[part 4 of 4: package /ComponentTypes]
AUTOSAR XML (schema 00050)
package /ComponentTypes  (continued)
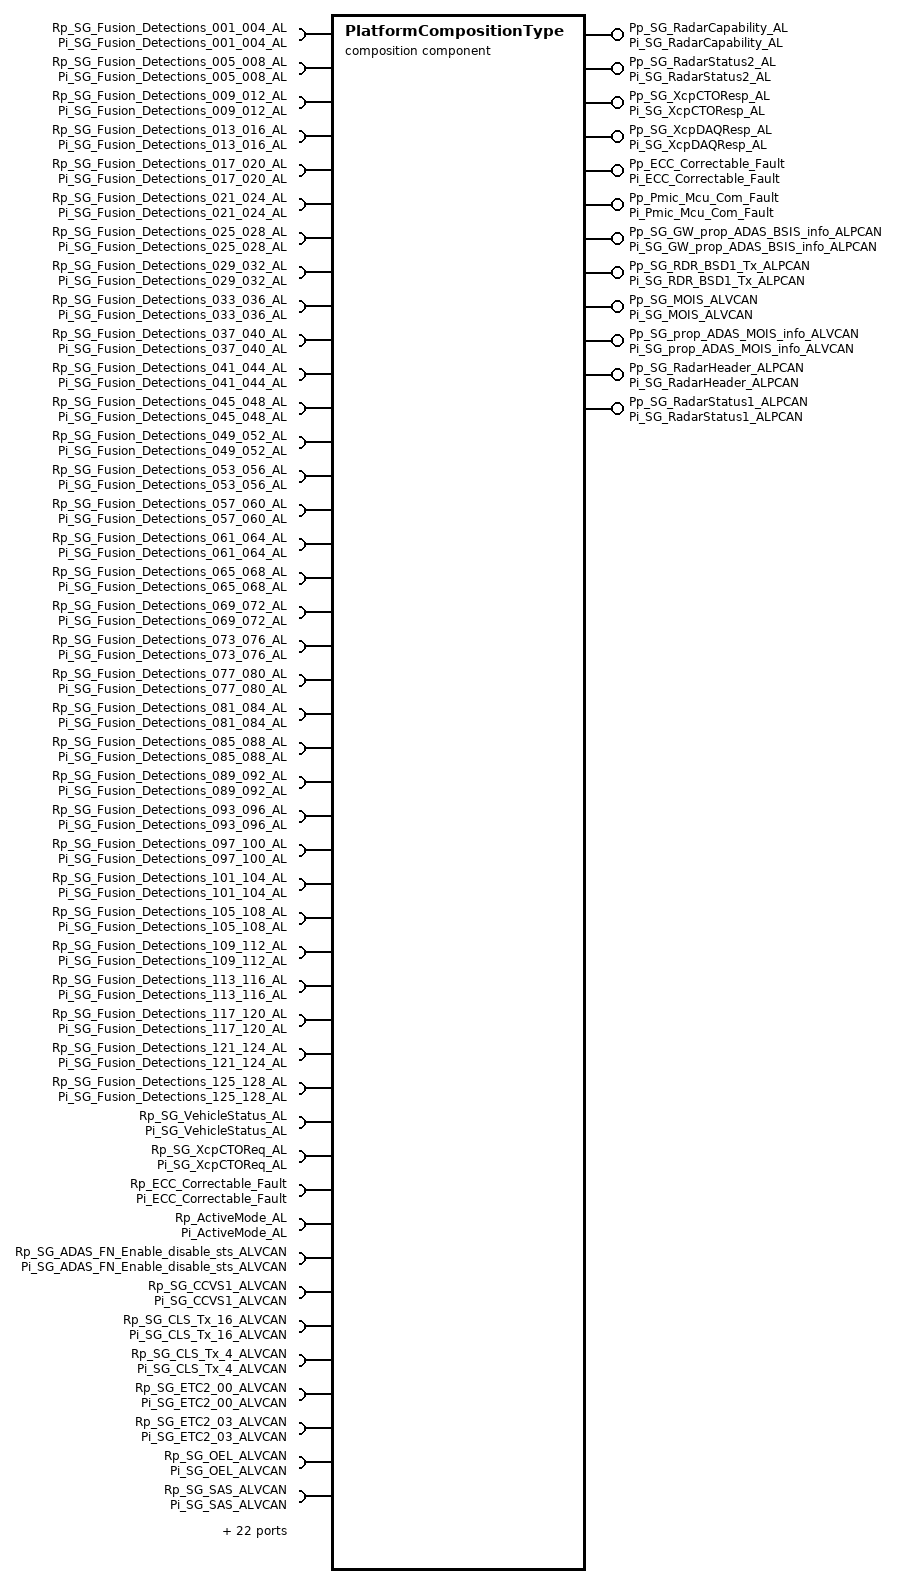
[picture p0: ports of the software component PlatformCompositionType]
  composition sw component type PlatformCompositionType  (continued)
    102 x provide port:  (continued)
      Pp_SG_Detections_397_400_AL: nonqueued-sender-com-spec{data-element=Vdp_SG_Detections_397_400_AL, init-value=fields=[DET_AZIMUTH_397:0, DET_AZIMUTH_398:0, DET_AZIMUTH_399:0, DET_AZIMUTH_400:0, DET_AZIMUTH_ERR_397:0, DET_AZIMUTH_ERR_398:0, DET_AZIMUTH_ERR_399:0, DET_AZIMUTH_ERR_400:0, DET_BELOW_RAIN_THOLD_397:0, DET_BELOW_RAIN_THOLD_398:0, DET_BELOW_RAIN_THOLD_399:0, DET_BELOW_RAIN_THOLD_400:0, DET_BI_STATIC_FLAG_397:0, DET_BI_STATIC_FLAG_398:0, DET_BI_STATIC_FLAG_399:0, DET_BI_STATIC_FLAG_400:0, DET_CONFD_AZIMUTH_397:0, DET_CONFD_AZIMUTH_398:0, DET_CONFD_AZIMUTH_399:0, DET_CONFD_AZIMUTH_400:0, DET_CONFD_ELEVATION_397:0, DET_CONFD_ELEVATION_398:0, DET_CONFD_ELEVATION_399:0, DET_CONFD_ELEVATION_400:0, DET_ELEVATION_397:0, DET_ELEVATION_398:0, DET_ELEVATION_399:0, DET_ELEVATION_400:0, DET_ELEVATION_ERR_397:0, DET_ELEVATION_ERR_398:0, DET_ELEVATION_ERR_399:0, DET_ELEVATION_ERR_400:0, DET_EXISTENCE_PROB_397:0, DET_EXISTENCE_PROB_398:0, DET_EXISTENCE_PROB_399:0, DET_EXISTENCE_PROB_400:0, DET_HVC_FLAG_397:0, DET_HVC_FLAG_398:0, DET_HVC_FLAG_399:0, DET_HVC_FLAG_400:0, DET_IDM_397:0, DET_IDM_398:0, DET_IDM_399:0, DET_IDM_400:0, DET_MH_CRC16_397_400:0, DET_MH_CYCLE_COUNTER_397_400:0, DET_MH_SCAN_INDEX_4LSB_397_400:0, DET_MTD_397:0, DET_MTD_398:0, DET_MTD_399:0, DET_MTD_400:0, DET_PROB_1STAZHYPO_397:0, DET_PROB_1STAZHYPO_398:0, DET_PROB_1STAZHYPO_399:0, DET_PROB_1STAZHYPO_400:0, DET_RANGE_397:0, DET_RANGE_398:0, DET_RANGE_399:0, DET_RANGE_400:0, DET_RANGE_ERR_397:0, DET_RANGE_ERR_398:0, DET_RANGE_ERR_399:0, DET_RANGE_ERR_400:0, DET_RANGE_VELOCITY_397:16384, DET_RANGE_VELOCITY_398:16384, DET_RANGE_VELOCITY_399:16384, DET_RANGE_VELOCITY_400:16384, DET_RANGE_VELOCITY_ERR_397:0, DET_RANGE_VELOCITY_ERR_398:0, DET_RANGE_VELOCITY_ERR_399:0, DET_RANGE_VELOCITY_ERR_400:0, DET_RCS_397:128, DET_RCS_398:128, DET_RCS_399:128, DET_RCS_400:128, DET_SNR_397:0, DET_SNR_398:0, DET_SNR_399:0, DET_SNR_400:0, DET_SUPER_RES_TARGET_397:0, DET_SUPER_RES_TARGET_398:0, DET_SUPER_RES_TARGET_399:0, DET_SUPER_RES_TARGET_400:0]}, provided-interface=Pi_SG_Detections_397_400_AL
    32 x require port:
      Rp_SG_Fusion_Detections_001_004_AL: nonqueued-receiver-com-spec{data-element=Vdp_SG_Fusion_Detections_001_004_AL, init-value=fields=[DET_AZIMUTH_001_Rx:0, DET_AZIMUTH_002_Rx:0, DET_AZIMUTH_003_Rx:0, DET_AZIMUTH_004_Rx:0, DET_AZIMUTH_ERR_001_Rx:0, DET_AZIMUTH_ERR_002_Rx:0, DET_AZIMUTH_ERR_003_Rx:0, DET_AZIMUTH_ERR_004_Rx:0, DET_BELOW_RAIN_THOLD_001_Rx:0, DET_BELOW_RAIN_THOLD_002_Rx:0, DET_BELOW_RAIN_THOLD_003_Rx:0, DET_BELOW_RAIN_THOLD_004_Rx:0, DET_BI_STATIC_FLAG_001_Rx:0, DET_BI_STATIC_FLAG_002_Rx:0, DET_BI_STATIC_FLAG_003_Rx:0, DET_BI_STATIC_FLAG_004_Rx:0, DET_CONFD_AZIMUTH_001_Rx:0, DET_CONFD_AZIMUTH_002_Rx:0, DET_CONFD_AZIMUTH_003_Rx:0, DET_CONFD_AZIMUTH_004_Rx:0, DET_CONFD_ELEVATION_001_Rx:0, DET_CONFD_ELEVATION_002_Rx:0, DET_CONFD_ELEVATION_003_Rx:0, DET_CONFD_ELEVATION_004_Rx:0, DET_ELEVATION_001_Rx:0, DET_ELEVATION_002_Rx:0, DET_ELEVATION_003_Rx:0, DET_ELEVATION_004_Rx:0, DET_ELEVATION_ERR_001_Rx:0, DET_ELEVATION_ERR_002_Rx:0, DET_ELEVATION_ERR_003_Rx:0, DET_ELEVATION_ERR_004_Rx:0, DET_EXISTENCE_PROB_001_Rx:0, DET_EXISTENCE_PROB_002_Rx:0, DET_EXISTENCE_PROB_003_Rx:0, DET_EXISTENCE_PROB_004_Rx:0, DET_HVC_FLAG_001_Rx:0, DET_HVC_FLAG_002_Rx:0, DET_HVC_FLAG_003_Rx:0, DET_HVC_FLAG_004_Rx:0, DET_IDM_001_Rx:0, DET_IDM_002_Rx:0, DET_IDM_003_Rx:0, DET_IDM_004_Rx:0, DET_MH_CRC16_001_004_Rx:0, DET_MH_CYCLE_COUNTER_001_004_Rx:0, DET_MH_SCAN_INDEX_4LSB_001_004_Rx:0, DET_MTD_001_Rx:0, DET_MTD_002_Rx:0, DET_MTD_003_Rx:0, DET_MTD_004_Rx:0, DET_PROB_1STAZHYPO_001_Rx:0, DET_PROB_1STAZHYPO_002_Rx:0, DET_PROB_1STAZHYPO_003_Rx:0, DET_PROB_1STAZHYPO_004_Rx:0, DET_RANGE_001_Rx:0, DET_RANGE_002_Rx:0, DET_RANGE_003_Rx:0, DET_RANGE_004_Rx:0, DET_RANGE_ERR_001_Rx:0, DET_RANGE_ERR_002_Rx:0, DET_RANGE_ERR_003_Rx:0, DET_RANGE_ERR_004_Rx:0, DET_RANGE_VELOCITY_001_Rx:0, DET_RANGE_VELOCITY_002_Rx:0, DET_RANGE_VELOCITY_003_Rx:0, DET_RANGE_VELOCITY_004_Rx:0, DET_RANGE_VELOCITY_ERR_001_Rx:0, DET_RANGE_VELOCITY_ERR_002_Rx:0, DET_RANGE_VELOCITY_ERR_003_Rx:0, DET_RANGE_VELOCITY_ERR_004_Rx:0, DET_RCS_001_Rx:0, DET_RCS_002_Rx:0, DET_RCS_003_Rx:0, DET_RCS_004_Rx:0, DET_SNR_001_Rx:0, DET_SNR_002_Rx:0, DET_SNR_003_Rx:0, DET_SNR_004_Rx:0, DET_SUPER_RES_TARGET_001_Rx:0, DET_SUPER_RES_TARGET_002_Rx:0, DET_SUPER_RES_TARGET_003_Rx:0, DET_SUPER_RES_TARGET_004_Rx:0]}, required-interface=Pi_SG_Fusion_Detections_001_004_AL
      Rp_SG_Fusion_Detections_005_008_AL: nonqueued-receiver-com-spec{data-element=Vdp_SG_Fusion_Detections_005_008_AL, init-value=fields=[DET_AZIMUTH_005_Rx:0, DET_AZIMUTH_006_Rx:0, DET_AZIMUTH_007_Rx:0, DET_AZIMUTH_008_Rx:0, DET_AZIMUTH_ERR_005_Rx:0, DET_AZIMUTH_ERR_006_Rx:0, DET_AZIMUTH_ERR_007_Rx:0, DET_AZIMUTH_ERR_008_Rx:0, DET_BELOW_RAIN_THOLD_005_Rx:0, DET_BELOW_RAIN_THOLD_006_Rx:0, DET_BELOW_RAIN_THOLD_007_Rx:0, DET_BELOW_RAIN_THOLD_008_Rx:0, DET_BI_STATIC_FLAG_005_Rx:0, DET_BI_STATIC_FLAG_006_Rx:0, DET_BI_STATIC_FLAG_007_Rx:0, DET_BI_STATIC_FLAG_008_Rx:0, DET_CONFD_AZIMUTH_005_Rx:0, DET_CONFD_AZIMUTH_006_Rx:0, DET_CONFD_AZIMUTH_007_Rx:0, DET_CONFD_AZIMUTH_008_Rx:0, DET_CONFD_ELEVATION_005_Rx:0, DET_CONFD_ELEVATION_006_Rx:0, DET_CONFD_ELEVATION_007_Rx:0, DET_CONFD_ELEVATION_008_Rx:0, DET_ELEVATION_005_Rx:0, DET_ELEVATION_006_Rx:0, DET_ELEVATION_007_Rx:0, DET_ELEVATION_008_Rx:0, DET_ELEVATION_ERR_005_Rx:0, DET_ELEVATION_ERR_006_Rx:0, DET_ELEVATION_ERR_007_Rx:0, DET_ELEVATION_ERR_008_Rx:0, DET_EXISTENCE_PROB_005_Rx:0, DET_EXISTENCE_PROB_006_Rx:0, DET_EXISTENCE_PROB_007_Rx:0, DET_EXISTENCE_PROB_008_Rx:0, DET_HVC_FLAG_005_Rx:0, DET_HVC_FLAG_006_Rx:0, DET_HVC_FLAG_007_Rx:0, DET_HVC_FLAG_008_Rx:0, DET_IDM_005_Rx:0, DET_IDM_006_Rx:0, DET_IDM_007_Rx:0, DET_IDM_008_Rx:0, DET_MH_CRC16_005_008_Rx:0, DET_MH_CYCLE_COUNTER_005_008_Rx:0, DET_MH_SCAN_INDEX_4LSB_005_008_Rx:0, DET_MTD_005_Rx:0, DET_MTD_006_Rx:0, DET_MTD_007_Rx:0, DET_MTD_008_Rx:0, DET_PROB_1STAZHYPO_005_Rx:0, DET_PROB_1STAZHYPO_006_Rx:0, DET_PROB_1STAZHYPO_007_Rx:0, DET_PROB_1STAZHYPO_008_Rx:0, DET_RANGE_005_Rx:0, DET_RANGE_006_Rx:0, DET_RANGE_007_Rx:0, DET_RANGE_008_Rx:0, DET_RANGE_ERR_005_Rx:0, DET_RANGE_ERR_006_Rx:0, DET_RANGE_ERR_007_Rx:0, DET_RANGE_ERR_008_Rx:0, DET_RANGE_VELOCITY_005_Rx:0, DET_RANGE_VELOCITY_006_Rx:0, DET_RANGE_VELOCITY_007_Rx:0, DET_RANGE_VELOCITY_008_Rx:0, DET_RANGE_VELOCITY_ERR_005_Rx:0, DET_RANGE_VELOCITY_ERR_006_Rx:0, DET_RANGE_VELOCITY_ERR_007_Rx:0, DET_RANGE_VELOCITY_ERR_008_Rx:0, DET_RCS_005_Rx:0, DET_RCS_006_Rx:0, DET_RCS_007_Rx:0, DET_RCS_008_Rx:0, DET_SNR_005_Rx:0, DET_SNR_006_Rx:0, DET_SNR_007_Rx:0, DET_SNR_008_Rx:0, DET_SUPER_RES_TARGET_005_Rx:0, DET_SUPER_RES_TARGET_006_Rx:0, DET_SUPER_RES_TARGET_007_Rx:0, DET_SUPER_RES_TARGET_008_Rx:0]}, required-interface=Pi_SG_Fusion_Detections_005_008_AL
      Rp_SG_Fusion_Detections_009_012_AL: nonqueued-receiver-com-spec{data-element=Vdp_SG_Fusion_Detections_009_012_AL, init-value=fields=[DET_AZIMUTH_009_Rx:0, DET_AZIMUTH_010_Rx:0, DET_AZIMUTH_011_Rx:0, DET_AZIMUTH_012_Rx:0, DET_AZIMUTH_ERR_009_Rx:0, DET_AZIMUTH_ERR_010_Rx:0, DET_AZIMUTH_ERR_011_Rx:0, DET_AZIMUTH_ERR_012_Rx:0, DET_BELOW_RAIN_THOLD_009_Rx:0, DET_BELOW_RAIN_THOLD_010_Rx:0, DET_BELOW_RAIN_THOLD_011_Rx:0, DET_BELOW_RAIN_THOLD_012_Rx:0, DET_BI_STATIC_FLAG_009_Rx:0, DET_BI_STATIC_FLAG_010_Rx:0, DET_BI_STATIC_FLAG_011_Rx:0, DET_BI_STATIC_FLAG_012_Rx:0, DET_CONFD_AZIMUTH_009_Rx:0, DET_CONFD_AZIMUTH_010_Rx:0, DET_CONFD_AZIMUTH_011_Rx:0, DET_CONFD_AZIMUTH_012_Rx:0, DET_CONFD_ELEVATION_009_Rx:0, DET_CONFD_ELEVATION_010_Rx:0, DET_CONFD_ELEVATION_011_Rx:0, DET_CONFD_ELEVATION_012_Rx:0, DET_ELEVATION_009_Rx:0, DET_ELEVATION_010_Rx:0, DET_ELEVATION_011_Rx:0, DET_ELEVATION_012_Rx:0, DET_ELEVATION_ERR_009_Rx:0, DET_ELEVATION_ERR_010_Rx:0, DET_ELEVATION_ERR_011_Rx:0, DET_ELEVATION_ERR_012_Rx:0, DET_EXISTENCE_PROB_009_Rx:0, DET_EXISTENCE_PROB_010_Rx:0, DET_EXISTENCE_PROB_011_Rx:0, DET_EXISTENCE_PROB_012_Rx:0, DET_HVC_FLAG_009_Rx:0, DET_HVC_FLAG_010_Rx:0, DET_HVC_FLAG_011_Rx:0, DET_HVC_FLAG_012_Rx:0, DET_IDM_009_Rx:0, DET_IDM_010_Rx:0, DET_IDM_011_Rx:0, DET_IDM_012_Rx:0, DET_MH_CRC16_009_012_Rx:0, DET_MH_CYCLE_COUNTER_009_012_Rx:0, DET_MH_SCAN_INDEX_4LSB_009_012_Rx:0, DET_MTD_009_Rx:0, DET_MTD_010_Rx:0, DET_MTD_011_Rx:0, DET_MTD_012_Rx:0, DET_PROB_1STAZHYPO_009_Rx:0, DET_PROB_1STAZHYPO_010_Rx:0, DET_PROB_1STAZHYPO_011_Rx:0, DET_PROB_1STAZHYPO_012_Rx:0, DET_RANGE_009_Rx:0, DET_RANGE_010_Rx:0, DET_RANGE_011_Rx:0, DET_RANGE_012_Rx:0, DET_RANGE_ERR_009_Rx:0, DET_RANGE_ERR_010_Rx:0, DET_RANGE_ERR_011_Rx:0, DET_RANGE_ERR_012_Rx:0, DET_RANGE_VELOCITY_009_Rx:0, DET_RANGE_VELOCITY_010_Rx:0, DET_RANGE_VELOCITY_011_Rx:0, DET_RANGE_VELOCITY_012_Rx:0, DET_RANGE_VELOCITY_ERR_009_Rx:0, DET_RANGE_VELOCITY_ERR_010_Rx:0, DET_RANGE_VELOCITY_ERR_011_Rx:0, DET_RANGE_VELOCITY_ERR_012_Rx:0, DET_RCS_009_Rx:0, DET_RCS_010_Rx:0, DET_RCS_011_Rx:0, DET_RCS_012_Rx:0, DET_SNR_009_Rx:0, DET_SNR_010_Rx:0, DET_SNR_011_Rx:0, DET_SNR_012_Rx:0, DET_SUPER_RES_TARGET_009_Rx:0, DET_SUPER_RES_TARGET_010_Rx:0, DET_SUPER_RES_TARGET_011_Rx:0, DET_SUPER_RES_TARGET_012_Rx:0]}, required-interface=Pi_SG_Fusion_Detections_009_012_AL
      Rp_SG_Fusion_Detections_013_016_AL: nonqueued-receiver-com-spec{data-element=Vdp_SG_Fusion_Detections_013_016_AL, init-value=fields=[DET_AZIMUTH_013_Rx:0, DET_AZIMUTH_014_Rx:0, DET_AZIMUTH_015_Rx:0, DET_AZIMUTH_016_Rx:0, DET_AZIMUTH_ERR_013_Rx:0, DET_AZIMUTH_ERR_014_Rx:0, DET_AZIMUTH_ERR_015_Rx:0, DET_AZIMUTH_ERR_016_Rx:0, DET_BELOW_RAIN_THOLD_013_Rx:0, DET_BELOW_RAIN_THOLD_014_Rx:0, DET_BELOW_RAIN_THOLD_015_Rx:0, DET_BELOW_RAIN_THOLD_016_Rx:0, DET_BI_STATIC_FLAG_013_Rx:0, DET_BI_STATIC_FLAG_014_Rx:0, DET_BI_STATIC_FLAG_015_Rx:0, DET_BI_STATIC_FLAG_016_Rx:0, DET_CONFD_AZIMUTH_013_Rx:0, DET_CONFD_AZIMUTH_014_Rx:0, DET_CONFD_AZIMUTH_015_Rx:0, DET_CONFD_AZIMUTH_016_Rx:0, DET_CONFD_ELEVATION_013_Rx:0, DET_CONFD_ELEVATION_014_Rx:0, DET_CONFD_ELEVATION_015_Rx:0, DET_CONFD_ELEVATION_016_Rx:0, DET_ELEVATION_013_Rx:0, DET_ELEVATION_014_Rx:0, DET_ELEVATION_015_Rx:0, DET_ELEVATION_016_Rx:0, DET_ELEVATION_ERR_013_Rx:0, DET_ELEVATION_ERR_014_Rx:0, DET_ELEVATION_ERR_015_Rx:0, DET_ELEVATION_ERR_016_Rx:0, DET_EXISTENCE_PROB_013_Rx:0, DET_EXISTENCE_PROB_014_Rx:0, DET_EXISTENCE_PROB_015_Rx:0, DET_EXISTENCE_PROB_016_Rx:0, DET_HVC_FLAG_013_Rx:0, DET_HVC_FLAG_014_Rx:0, DET_HVC_FLAG_015_Rx:0, DET_HVC_FLAG_016_Rx:0, DET_IDM_013_Rx:0, DET_IDM_014_Rx:0, DET_IDM_015_Rx:0, DET_IDM_016_Rx:0, DET_MH_CRC16_013_016_Rx:0, DET_MH_CYCLE_COUNTER_013_016_Rx:0, DET_MH_SCAN_INDEX_4LSB_013_016_Rx:0, DET_MTD_013_Rx:0, DET_MTD_014_Rx:0, DET_MTD_015_Rx:0, DET_MTD_016_Rx:0, DET_PROB_1STAZHYPO_013_Rx:0, DET_PROB_1STAZHYPO_014_Rx:0, DET_PROB_1STAZHYPO_015_Rx:0, DET_PROB_1STAZHYPO_016_Rx:0, DET_RANGE_013_Rx:0, DET_RANGE_014_Rx:0, DET_RANGE_015_Rx:0, DET_RANGE_016_Rx:0, DET_RANGE_ERR_013_Rx:0, DET_RANGE_ERR_014_Rx:0, DET_RANGE_ERR_015_Rx:0, DET_RANGE_ERR_016_Rx:0, DET_RANGE_VELOCITY_013_Rx:0, DET_RANGE_VELOCITY_014_Rx:0, DET_RANGE_VELOCITY_015_Rx:0, DET_RANGE_VELOCITY_016_Rx:0, DET_RANGE_VELOCITY_ERR_013_Rx:0, DET_RANGE_VELOCITY_ERR_014_Rx:0, DET_RANGE_VELOCITY_ERR_015_Rx:0, DET_RANGE_VELOCITY_ERR_016_Rx:0, DET_RCS_013_Rx:0, DET_RCS_014_Rx:0, DET_RCS_015_Rx:0, DET_RCS_016_Rx:0, DET_SNR_013_Rx:0, DET_SNR_014_Rx:0, DET_SNR_015_Rx:0, DET_SNR_016_Rx:0, DET_SUPER_RES_TARGET_013_Rx:0, DET_SUPER_RES_TARGET_014_Rx:0, DET_SUPER_RES_TARGET_015_Rx:0, DET_SUPER_RES_TARGET_016_Rx:0]}, required-interface=Pi_SG_Fusion_Detections_013_016_AL
      Rp_SG_Fusion_Detections_017_020_AL: nonqueued-receiver-com-spec{data-element=Vdp_SG_Fusion_Detections_017_020_AL, init-value=fields=[DET_AZIMUTH_017_Rx:0, DET_AZIMUTH_018_Rx:0, DET_AZIMUTH_019_Rx:0, DET_AZIMUTH_020_Rx:0, DET_AZIMUTH_ERR_017_Rx:0, DET_AZIMUTH_ERR_018_Rx:0, DET_AZIMUTH_ERR_019_Rx:0, DET_AZIMUTH_ERR_020_Rx:0, DET_BELOW_RAIN_THOLD_017_Rx:0, DET_BELOW_RAIN_THOLD_018_Rx:0, DET_BELOW_RAIN_THOLD_019_Rx:0, DET_BELOW_RAIN_THOLD_020_Rx:0, DET_BI_STATIC_FLAG_017_Rx:0, DET_BI_STATIC_FLAG_018_Rx:0, DET_BI_STATIC_FLAG_019_Rx:0, DET_BI_STATIC_FLAG_020_Rx:0, DET_CONFD_AZIMUTH_017_Rx:0, DET_CONFD_AZIMUTH_018_Rx:0, DET_CONFD_AZIMUTH_019_Rx:0, DET_CONFD_AZIMUTH_020_Rx:0, DET_CONFD_ELEVATION_017_Rx:0, DET_CONFD_ELEVATION_018_Rx:0, DET_CONFD_ELEVATION_019_Rx:0, DET_CONFD_ELEVATION_020_Rx:0, DET_ELEVATION_017_Rx:0, DET_ELEVATION_018_Rx:0, DET_ELEVATION_019_Rx:0, DET_ELEVATION_020_Rx:0, DET_ELEVATION_ERR_017_Rx:0, DET_ELEVATION_ERR_018_Rx:0, DET_ELEVATION_ERR_019_Rx:0, DET_ELEVATION_ERR_020_Rx:0, DET_EXISTENCE_PROB_017_Rx:0, DET_EXISTENCE_PROB_018_Rx:0, DET_EXISTENCE_PROB_019_Rx:0, DET_EXISTENCE_PROB_020_Rx:0, DET_HVC_FLAG_017_Rx:0, DET_HVC_FLAG_018_Rx:0, DET_HVC_FLAG_019_Rx:0, DET_HVC_FLAG_020_Rx:0, DET_IDM_017_Rx:0, DET_IDM_018_Rx:0, DET_IDM_019_Rx:0, DET_IDM_020_Rx:0, DET_MH_CRC16_017_020_Rx:0, DET_MH_CYCLE_COUNTER_017_020_Rx:0, DET_MH_SCAN_INDEX_4LSB_017_020_Rx:0, DET_MTD_017_Rx:0, DET_MTD_018_Rx:0, DET_MTD_019_Rx:0, DET_MTD_020_Rx:0, DET_PROB_1STAZHYPO_017_Rx:0, DET_PROB_1STAZHYPO_018_Rx:0, DET_PROB_1STAZHYPO_019_Rx:0, DET_PROB_1STAZHYPO_020_Rx:0, DET_RANGE_017_Rx:0, DET_RANGE_018_Rx:0, DET_RANGE_019_Rx:0, DET_RANGE_020_Rx:0, DET_RANGE_ERR_017_Rx:0, DET_RANGE_ERR_018_Rx:0, DET_RANGE_ERR_019_Rx:0, DET_RANGE_ERR_020_Rx:0, DET_RANGE_VELOCITY_017_Rx:0, DET_RANGE_VELOCITY_018_Rx:0, DET_RANGE_VELOCITY_019_Rx:0, DET_RANGE_VELOCITY_020_Rx:0, DET_RANGE_VELOCITY_ERR_017_Rx:0, DET_RANGE_VELOCITY_ERR_018_Rx:0, DET_RANGE_VELOCITY_ERR_019_Rx:0, DET_RANGE_VELOCITY_ERR_020_Rx:0, DET_RCS_017_Rx:0, DET_RCS_018_Rx:0, DET_RCS_019_Rx:0, DET_RCS_020_Rx:0, DET_SNR_017_Rx:0, DET_SNR_018_Rx:0, DET_SNR_019_Rx:0, DET_SNR_020_Rx:0, DET_SUPER_RES_TARGET_017_Rx:0, DET_SUPER_RES_TARGET_018_Rx:0, DET_SUPER_RES_TARGET_019_Rx:0, DET_SUPER_RES_TARGET_020_Rx:0]}, required-interface=Pi_SG_Fusion_Detections_017_020_AL
      Rp_SG_Fusion_Detections_021_024_AL: nonqueued-receiver-com-spec{data-element=Vdp_SG_Fusion_Detections_021_024_AL, init-value=fields=[DET_AZIMUTH_021_Rx:0, DET_AZIMUTH_022_Rx:0, DET_AZIMUTH_023_Rx:0, DET_AZIMUTH_024_Rx:0, DET_AZIMUTH_ERR_021_Rx:0, DET_AZIMUTH_ERR_022_Rx:0, DET_AZIMUTH_ERR_023_Rx:0, DET_AZIMUTH_ERR_024_Rx:0, DET_BELOW_RAIN_THOLD_021_Rx:0, DET_BELOW_RAIN_THOLD_022_Rx:0, DET_BELOW_RAIN_THOLD_023_Rx:0, DET_BELOW_RAIN_THOLD_024_Rx:0, DET_BI_STATIC_FLAG_021_Rx:0, DET_BI_STATIC_FLAG_022_Rx:0, DET_BI_STATIC_FLAG_023_Rx:0, DET_BI_STATIC_FLAG_024_Rx:0, DET_CONFD_AZIMUTH_021_Rx:0, DET_CONFD_AZIMUTH_022_Rx:0, DET_CONFD_AZIMUTH_023_Rx:0, DET_CONFD_AZIMUTH_024_Rx:0, DET_CONFD_ELEVATION_021_Rx:0, DET_CONFD_ELEVATION_022_Rx:0, DET_CONFD_ELEVATION_023_Rx:0, DET_CONFD_ELEVATION_024_Rx:0, DET_ELEVATION_021_Rx:0, DET_ELEVATION_022_Rx:0, DET_ELEVATION_023_Rx:0, DET_ELEVATION_024_Rx:0, DET_ELEVATION_ERR_021_Rx:0, DET_ELEVATION_ERR_022_Rx:0, DET_ELEVATION_ERR_023_Rx:0, DET_ELEVATION_ERR_024_Rx:0, DET_EXISTENCE_PROB_021_Rx:0, DET_EXISTENCE_PROB_022_Rx:0, DET_EXISTENCE_PROB_023_Rx:0, DET_EXISTENCE_PROB_024_Rx:0, DET_HVC_FLAG_021_Rx:0, DET_HVC_FLAG_022_Rx:0, DET_HVC_FLAG_023_Rx:0, DET_HVC_FLAG_024_Rx:0, DET_IDM_021_Rx:0, DET_IDM_022_Rx:0, DET_IDM_023_Rx:0, DET_IDM_024_Rx:0, DET_MH_CRC16_021_024_Rx:0, DET_MH_CYCLE_COUNTER_021_024_Rx:0, DET_MH_SCAN_INDEX_4LSB_021_024_Rx:0, DET_MTD_021_Rx:0, DET_MTD_022_Rx:0, DET_MTD_023_Rx:0, DET_MTD_024_Rx:0, DET_PROB_1STAZHYPO_021_Rx:0, DET_PROB_1STAZHYPO_022_Rx:0, DET_PROB_1STAZHYPO_023_Rx:0, DET_PROB_1STAZHYPO_024_Rx:0, DET_RANGE_021_Rx:0, DET_RANGE_022_Rx:0, DET_RANGE_023_Rx:0, DET_RANGE_024_Rx:0, DET_RANGE_ERR_021_Rx:0, DET_RANGE_ERR_022_Rx:0, DET_RANGE_ERR_023_Rx:0, DET_RANGE_ERR_024_Rx:0, DET_RANGE_VELOCITY_021_Rx:0, DET_RANGE_VELOCITY_022_Rx:0, DET_RANGE_VELOCITY_023_Rx:0, DET_RANGE_VELOCITY_024_Rx:0, DET_RANGE_VELOCITY_ERR_021_Rx:0, DET_RANGE_VELOCITY_ERR_022_Rx:0, DET_RANGE_VELOCITY_ERR_023_Rx:0, DET_RANGE_VELOCITY_ERR_024_Rx:0, DET_RCS_021_Rx:0, DET_RCS_022_Rx:0, DET_RCS_023_Rx:0, DET_RCS_024_Rx:0, DET_SNR_021_Rx:0, DET_SNR_022_Rx:0, DET_SNR_023_Rx:0, DET_SNR_024_Rx:0, DET_SUPER_RES_TARGET_021_Rx:0, DET_SUPER_RES_TARGET_022_Rx:0, DET_SUPER_RES_TARGET_023_Rx:0, DET_SUPER_RES_TARGET_024_Rx:0]}, required-interface=Pi_SG_Fusion_Detections_021_024_AL
      Rp_SG_Fusion_Detections_025_028_AL: nonqueued-receiver-com-spec{data-element=Vdp_SG_Fusion_Detections_025_028_AL, init-value=fields=[DET_AZIMUTH_025_Rx:0, DET_AZIMUTH_026_Rx:0, DET_AZIMUTH_027_Rx:0, DET_AZIMUTH_028_Rx:0, DET_AZIMUTH_ERR_025_Rx:0, DET_AZIMUTH_ERR_026_Rx:0, DET_AZIMUTH_ERR_027_Rx:0, DET_AZIMUTH_ERR_028_Rx:0, DET_BELOW_RAIN_THOLD_025_Rx:0, DET_BELOW_RAIN_THOLD_026_Rx:0, DET_BELOW_RAIN_THOLD_027_Rx:0, DET_BELOW_RAIN_THOLD_028_Rx:0, DET_BI_STATIC_FLAG_025_Rx:0, DET_BI_STATIC_FLAG_026_Rx:0, DET_BI_STATIC_FLAG_027_Rx:0, DET_BI_STATIC_FLAG_028_Rx:0, DET_CONFD_AZIMUTH_025_Rx:0, DET_CONFD_AZIMUTH_026_Rx:0, DET_CONFD_AZIMUTH_027_Rx:0, DET_CONFD_AZIMUTH_028_Rx:0, DET_CONFD_ELEVATION_025_Rx:0, DET_CONFD_ELEVATION_026_Rx:0, DET_CONFD_ELEVATION_027_Rx:0, DET_CONFD_ELEVATION_028_Rx:0, DET_ELEVATION_025_Rx:0, DET_ELEVATION_026_Rx:0, DET_ELEVATION_027_Rx:0, DET_ELEVATION_028_Rx:0, DET_ELEVATION_ERR_025_Rx:0, DET_ELEVATION_ERR_026_Rx:0, DET_ELEVATION_ERR_027_Rx:0, DET_ELEVATION_ERR_028_Rx:0, DET_EXISTENCE_PROB_025_Rx:0, DET_EXISTENCE_PROB_026_Rx:0, DET_EXISTENCE_PROB_027_Rx:0, DET_EXISTENCE_PROB_028_Rx:0, DET_HVC_FLAG_025_Rx:0, DET_HVC_FLAG_026_Rx:0, DET_HVC_FLAG_027_Rx:0, DET_HVC_FLAG_028_Rx:0, DET_IDM_025_Rx:0, DET_IDM_026_Rx:0, DET_IDM_027_Rx:0, DET_IDM_028_Rx:0, DET_MH_CRC16_025_028_Rx:0, DET_MH_CYCLE_COUNTER_025_028_Rx:0, DET_MH_SCAN_INDEX_4LSB_025_028_Rx:0, DET_MTD_025_Rx:0, DET_MTD_026_Rx:0, DET_MTD_027_Rx:0, DET_MTD_028_Rx:0, DET_PROB_1STAZHYPO_025_Rx:0, DET_PROB_1STAZHYPO_026_Rx:0, DET_PROB_1STAZHYPO_027_Rx:0, DET_PROB_1STAZHYPO_028_Rx:0, DET_RANGE_025_Rx:0, DET_RANGE_026_Rx:0, DET_RANGE_027_Rx:0, DET_RANGE_028_Rx:0, DET_RANGE_ERR_025_Rx:0, DET_RANGE_ERR_026_Rx:0, DET_RANGE_ERR_027_Rx:0, DET_RANGE_ERR_028_Rx:0, DET_RANGE_VELOCITY_025_Rx:0, DET_RANGE_VELOCITY_026_Rx:0, DET_RANGE_VELOCITY_027_Rx:0, DET_RANGE_VELOCITY_028_Rx:0, DET_RANGE_VELOCITY_ERR_025_Rx:0, DET_RANGE_VELOCITY_ERR_026_Rx:0, DET_RANGE_VELOCITY_ERR_027_Rx:0, DET_RANGE_VELOCITY_ERR_028_Rx:0, DET_RCS_025_Rx:0, DET_RCS_026_Rx:0, DET_RCS_027_Rx:0, DET_RCS_028_Rx:0, DET_SNR_025_Rx:0, DET_SNR_026_Rx:0, DET_SNR_027_Rx:0, DET_SNR_028_Rx:0, DET_SUPER_RES_TARGET_025_Rx:0, DET_SUPER_RES_TARGET_026_Rx:0, DET_SUPER_RES_TARGET_027_Rx:0, DET_SUPER_RES_TARGET_028_Rx:0]}, required-interface=Pi_SG_Fusion_Detections_025_028_AL
      Rp_SG_Fusion_Detections_029_032_AL: nonqueued-receiver-com-spec{data-element=Vdp_SG_Fusion_Detections_029_032_AL, init-value=fields=[DET_AZIMUTH_029_Rx:0, DET_AZIMUTH_030_Rx:0, DET_AZIMUTH_031_Rx:0, DET_AZIMUTH_032_Rx:0, DET_AZIMUTH_ERR_029_Rx:0, DET_AZIMUTH_ERR_030_Rx:0, DET_AZIMUTH_ERR_031_Rx:0, DET_AZIMUTH_ERR_032_Rx:0, DET_BELOW_RAIN_THOLD_029_Rx:0, DET_BELOW_RAIN_THOLD_030_Rx:0, DET_BELOW_RAIN_THOLD_031_Rx:0, DET_BELOW_RAIN_THOLD_032_Rx:0, DET_BI_STATIC_FLAG_029_Rx:0, DET_BI_STATIC_FLAG_030_Rx:0, DET_BI_STATIC_FLAG_031_Rx:0, DET_BI_STATIC_FLAG_032_Rx:0, DET_CONFD_AZIMUTH_029_Rx:0, DET_CONFD_AZIMUTH_030_Rx:0, DET_CONFD_AZIMUTH_031_Rx:0, DET_CONFD_AZIMUTH_032_Rx:0, DET_CONFD_ELEVATION_029_Rx:0, DET_CONFD_ELEVATION_030_Rx:0, DET_CONFD_ELEVATION_031_Rx:0, DET_CONFD_ELEVATION_032_Rx:0, DET_ELEVATION_029_Rx:0, DET_ELEVATION_030_Rx:0, DET_ELEVATION_031_Rx:0, DET_ELEVATION_032_Rx:0, DET_ELEVATION_ERR_029_Rx:0, DET_ELEVATION_ERR_030_Rx:0, DET_ELEVATION_ERR_031_Rx:0, DET_ELEVATION_ERR_032_Rx:0, DET_EXISTENCE_PROB_029_Rx:0, DET_EXISTENCE_PROB_030_Rx:0, DET_EXISTENCE_PROB_031_Rx:0, DET_EXISTENCE_PROB_032_Rx:0, DET_HVC_FLAG_029_Rx:0, DET_HVC_FLAG_030_Rx:0, DET_HVC_FLAG_031_Rx:0, DET_HVC_FLAG_032_Rx:0, DET_IDM_029_Rx:0, DET_IDM_030_Rx:0, DET_IDM_031_Rx:0, DET_IDM_032_Rx:0, DET_MH_CRC16_029_032_Rx:0, DET_MH_CYCLE_COUNTER_029_032_Rx:0, DET_MH_SCAN_INDEX_4LSB_029_032_Rx:0, DET_MTD_029_Rx:0, DET_MTD_030_Rx:0, DET_MTD_031_Rx:0, DET_MTD_032_Rx:0, DET_PROB_1STAZHYPO_029_Rx:0, DET_PROB_1STAZHYPO_030_Rx:0, DET_PROB_1STAZHYPO_031_Rx:0, DET_PROB_1STAZHYPO_032_Rx:0, DET_RANGE_029_Rx:0, DET_RANGE_030_Rx:0, DET_RANGE_031_Rx:0, DET_RANGE_032_Rx:0, DET_RANGE_ERR_029_Rx:0, DET_RANGE_ERR_030_Rx:0, DET_RANGE_ERR_031_Rx:0, DET_RANGE_ERR_032_Rx:0, DET_RANGE_VELOCITY_029_Rx:0, DET_RANGE_VELOCITY_030_Rx:0, DET_RANGE_VELOCITY_031_Rx:0, DET_RANGE_VELOCITY_032_Rx:0, DET_RANGE_VELOCITY_ERR_029_Rx:0, DET_RANGE_VELOCITY_ERR_030_Rx:0, DET_RANGE_VELOCITY_ERR_031_Rx:0, DET_RANGE_VELOCITY_ERR_032_Rx:0, DET_RCS_029_Rx:0, DET_RCS_030_Rx:0, DET_RCS_031_Rx:0, DET_RCS_032_Rx:0, DET_SNR_029_Rx:0, DET_SNR_030_Rx:0, DET_SNR_031_Rx:0, DET_SNR_032_Rx:0, DET_SUPER_RES_TARGET_029_Rx:0, DET_SUPER_RES_TARGET_030_Rx:0, DET_SUPER_RES_TARGET_031_Rx:0, DET_SUPER_RES_TARGET_032_Rx:0]}, required-interface=Pi_SG_Fusion_Detections_029_032_AL
      Rp_SG_Fusion_Detections_033_036_AL: nonqueued-receiver-com-spec{data-element=Vdp_SG_Fusion_Detections_033_036_AL, init-value=fields=[DET_AZIMUTH_033_Rx:0, DET_AZIMUTH_034_Rx:0, DET_AZIMUTH_035_Rx:0, DET_AZIMUTH_036_Rx:0, DET_AZIMUTH_ERR_033_Rx:0, DET_AZIMUTH_ERR_034_Rx:0, DET_AZIMUTH_ERR_035_Rx:0, DET_AZIMUTH_ERR_036_Rx:0, DET_BELOW_RAIN_THOLD_033_Rx:0, DET_BELOW_RAIN_THOLD_034_Rx:0, DET_BELOW_RAIN_THOLD_035_Rx:0, DET_BELOW_RAIN_THOLD_036_Rx:0, DET_BI_STATIC_FLAG_033_Rx:0, DET_BI_STATIC_FLAG_034_Rx:0, DET_BI_STATIC_FLAG_035_Rx:0, DET_BI_STATIC_FLAG_036_Rx:0, DET_CONFD_AZIMUTH_033_Rx:0, DET_CONFD_AZIMUTH_034_Rx:0, DET_CONFD_AZIMUTH_035_Rx:0, DET_CONFD_AZIMUTH_036_Rx:0, DET_CONFD_ELEVATION_033_Rx:0, DET_CONFD_ELEVATION_034_Rx:0, DET_CONFD_ELEVATION_035_Rx:0, DET_CONFD_ELEVATION_036_Rx:0, DET_ELEVATION_033_Rx:0, DET_ELEVATION_034_Rx:0, DET_ELEVATION_035_Rx:0, DET_ELEVATION_036_Rx:0, DET_ELEVATION_ERR_033_Rx:0, DET_ELEVATION_ERR_034_Rx:0, DET_ELEVATION_ERR_035_Rx:0, DET_ELEVATION_ERR_036_Rx:0, DET_EXISTENCE_PROB_033_Rx:0, DET_EXISTENCE_PROB_034_Rx:0, DET_EXISTENCE_PROB_035_Rx:0, DET_EXISTENCE_PROB_036_Rx:0, DET_HVC_FLAG_033_Rx:0, DET_HVC_FLAG_034_Rx:0, DET_HVC_FLAG_035_Rx:0, DET_HVC_FLAG_036_Rx:0, DET_IDM_033_Rx:0, DET_IDM_034_Rx:0, DET_IDM_035_Rx:0, DET_IDM_036_Rx:0, DET_MH_CRC16_033_036_Rx:0, DET_MH_CYCLE_COUNTER_033_036_Rx:0, DET_MH_SCAN_INDEX_4LSB_033_036_Rx:0, DET_MTD_033_Rx:0, DET_MTD_034_Rx:0, DET_MTD_035_Rx:0, DET_MTD_036_Rx:0, DET_PROB_1STAZHYPO_033_Rx:0, DET_PROB_1STAZHYPO_034_Rx:0, DET_PROB_1STAZHYPO_035_Rx:0, DET_PROB_1STAZHYPO_036_Rx:0, DET_RANGE_033_Rx:0, DET_RANGE_034_Rx:0, DET_RANGE_035_Rx:0, DET_RANGE_036_Rx:0, DET_RANGE_ERR_033_Rx:0, DET_RANGE_ERR_034_Rx:0, DET_RANGE_ERR_035_Rx:0, DET_RANGE_ERR_036_Rx:0, DET_RANGE_VELOCITY_033_Rx:0, DET_RANGE_VELOCITY_034_Rx:0, DET_RANGE_VELOCITY_035_Rx:0, DET_RANGE_VELOCITY_036_Rx:0, DET_RANGE_VELOCITY_ERR_033_Rx:0, DET_RANGE_VELOCITY_ERR_034_Rx:0, DET_RANGE_VELOCITY_ERR_035_Rx:0, DET_RANGE_VELOCITY_ERR_036_Rx:0, DET_RCS_033_Rx:0, DET_RCS_034_Rx:0, DET_RCS_035_Rx:0, DET_RCS_036_Rx:0, DET_SNR_033_Rx:0, DET_SNR_034_Rx:0, DET_SNR_035_Rx:0, DET_SNR_036_Rx:0, DET_SUPER_RES_TARGET_033_Rx:0, DET_SUPER_RES_TARGET_034_Rx:0, DET_SUPER_RES_TARGET_035_Rx:0, DET_SUPER_RES_TARGET_036_Rx:0]}, required-interface=Pi_SG_Fusion_Detections_033_036_AL
      Rp_SG_Fusion_Detections_037_040_AL: nonqueued-receiver-com-spec{data-element=Vdp_SG_Fusion_Detections_037_040_AL, init-value=fields=[DET_AZIMUTH_037_Rx:0, DET_AZIMUTH_038_Rx:0, DET_AZIMUTH_039_Rx:0, DET_AZIMUTH_040_Rx:0, DET_AZIMUTH_ERR_037_Rx:0, DET_AZIMUTH_ERR_038_Rx:0, DET_AZIMUTH_ERR_039_Rx:0, DET_AZIMUTH_ERR_040_Rx:0, DET_BELOW_RAIN_THOLD_037_Rx:0, DET_BELOW_RAIN_THOLD_038_Rx:0, DET_BELOW_RAIN_THOLD_039_Rx:0, DET_BELOW_RAIN_THOLD_040_Rx:0, DET_BI_STATIC_FLAG_037_Rx:0, DET_BI_STATIC_FLAG_038_Rx:0, DET_BI_STATIC_FLAG_039_Rx:0, DET_BI_STATIC_FLAG_040_Rx:0, DET_CONFD_AZIMUTH_037_Rx:0, DET_CONFD_AZIMUTH_038_Rx:0, DET_CONFD_AZIMUTH_039_Rx:0, DET_CONFD_AZIMUTH_040_Rx:0, DET_CONFD_ELEVATION_037_Rx:0, DET_CONFD_ELEVATION_038_Rx:0, DET_CONFD_ELEVATION_039_Rx:0, DET_CONFD_ELEVATION_040_Rx:0, DET_ELEVATION_037_Rx:0, DET_ELEVATION_038_Rx:0, DET_ELEVATION_039_Rx:0, DET_ELEVATION_040_Rx:0, DET_ELEVATION_ERR_037_Rx:0, DET_ELEVATION_ERR_038_Rx:0, DET_ELEVATION_ERR_039_Rx:0, DET_ELEVATION_ERR_040_Rx:0, DET_EXISTENCE_PROB_037_Rx:0, DET_EXISTENCE_PROB_038_Rx:0, DET_EXISTENCE_PROB_039_Rx:0, DET_EXISTENCE_PROB_040_Rx:0, DET_HVC_FLAG_037_Rx:0, DET_HVC_FLAG_038_Rx:0, DET_HVC_FLAG_039_Rx:0, DET_HVC_FLAG_040_Rx:0, DET_IDM_037_Rx:0, DET_IDM_038_Rx:0, DET_IDM_039_Rx:0, DET_IDM_040_Rx:0, DET_MH_CRC16_037_040_Rx:0, DET_MH_CYCLE_COUNTER_037_040_Rx:0, DET_MH_SCAN_INDEX_4LSB_037_040_Rx:0, DET_MTD_037_Rx:0, DET_MTD_038_Rx:0, DET_MTD_039_Rx:0, DET_MTD_040_Rx:0, DET_PROB_1STAZHYPO_037_Rx:0, DET_PROB_1STAZHYPO_038_Rx:0, DET_PROB_1STAZHYPO_039_Rx:0, DET_PROB_1STAZHYPO_040_Rx:0, DET_RANGE_037_Rx:0, DET_RANGE_038_Rx:0, DET_RANGE_039_Rx:0, DET_RANGE_040_Rx:0, DET_RANGE_ERR_037_Rx:0, DET_RANGE_ERR_038_Rx:0, DET_RANGE_ERR_039_Rx:0, DET_RANGE_ERR_040_Rx:0, DET_RANGE_VELOCITY_037_Rx:0, DET_RANGE_VELOCITY_038_Rx:0, DET_RANGE_VELOCITY_039_Rx:0, DET_RANGE_VELOCITY_040_Rx:0, DET_RANGE_VELOCITY_ERR_037_Rx:0, DET_RANGE_VELOCITY_ERR_038_Rx:0, DET_RANGE_VELOCITY_ERR_039_Rx:0, DET_RANGE_VELOCITY_ERR_040_Rx:0, DET_RCS_037_Rx:0, DET_RCS_038_Rx:0, DET_RCS_039_Rx:0, DET_RCS_040_Rx:0, DET_SNR_037_Rx:0, DET_SNR_038_Rx:0, DET_SNR_039_Rx:0, DET_SNR_040_Rx:0, DET_SUPER_RES_TARGET_037_Rx:0, DET_SUPER_RES_TARGET_038_Rx:0, DET_SUPER_RES_TARGET_039_Rx:0, DET_SUPER_RES_TARGET_040_Rx:0]}, required-interface=Pi_SG_Fusion_Detections_037_040_AL
      Rp_SG_Fusion_Detections_041_044_AL: nonqueued-receiver-com-spec{data-element=Vdp_SG_Fusion_Detections_041_044_AL, init-value=fields=[DET_AZIMUTH_041_Rx:0, DET_AZIMUTH_042_Rx:0, DET_AZIMUTH_043_Rx:0, DET_AZIMUTH_044_Rx:0, DET_AZIMUTH_ERR_041_Rx:0, DET_AZIMUTH_ERR_042_Rx:0, DET_AZIMUTH_ERR_043_Rx:0, DET_AZIMUTH_ERR_044_Rx:0, DET_BELOW_RAIN_THOLD_041_Rx:0, DET_BELOW_RAIN_THOLD_042_Rx:0, DET_BELOW_RAIN_THOLD_043_Rx:0, DET_BELOW_RAIN_THOLD_044_Rx:0, DET_BI_STATIC_FLAG_041_Rx:0, DET_BI_STATIC_FLAG_042_Rx:0, DET_BI_STATIC_FLAG_043_Rx:0, DET_BI_STATIC_FLAG_044_Rx:0, DET_CONFD_AZIMUTH_041_Rx:0, DET_CONFD_AZIMUTH_042_Rx:0, DET_CONFD_AZIMUTH_043_Rx:0, DET_CONFD_AZIMUTH_044_Rx:0, DET_CONFD_ELEVATION_041_Rx:0, DET_CONFD_ELEVATION_042_Rx:0, DET_CONFD_ELEVATION_043_Rx:0, DET_CONFD_ELEVATION_044_Rx:0, DET_ELEVATION_041_Rx:0, DET_ELEVATION_042_Rx:0, DET_ELEVATION_043_Rx:0, DET_ELEVATION_044_Rx:0, DET_ELEVATION_ERR_041_Rx:0, DET_ELEVATION_ERR_042_Rx:0, DET_ELEVATION_ERR_043_Rx:0, DET_ELEVATION_ERR_044_Rx:0, DET_EXISTENCE_PROB_041_Rx:0, DET_EXISTENCE_PROB_042_Rx:0, DET_EXISTENCE_PROB_043_Rx:0, DET_EXISTENCE_PROB_044_Rx:0, DET_HVC_FLAG_041_Rx:0, DET_HVC_FLAG_042_Rx:0, DET_HVC_FLAG_043_Rx:0, DET_HVC_FLAG_044_Rx:0, DET_IDM_041_Rx:0, DET_IDM_042_Rx:0, DET_IDM_043_Rx:0, DET_IDM_044_Rx:0, DET_MH_CRC16_041_044_Rx:0, DET_MH_CYCLE_COUNTER_041_044_Rx:0, DET_MH_SCAN_INDEX_4LSB_041_044_Rx:0, DET_MTD_041_Rx:0, DET_MTD_042_Rx:0, DET_MTD_043_Rx:0, DET_MTD_044_Rx:0, DET_PROB_1STAZHYPO_041_Rx:0, DET_PROB_1STAZHYPO_042_Rx:0, DET_PROB_1STAZHYPO_043_Rx:0, DET_PROB_1STAZHYPO_044_Rx:0, DET_RANGE_041_Rx:0, DET_RANGE_042_Rx:0, DET_RANGE_043_Rx:0, DET_RANGE_044_Rx:0, DET_RANGE_ERR_041_Rx:0, DET_RANGE_ERR_042_Rx:0, DET_RANGE_ERR_043_Rx:0, DET_RANGE_ERR_044_Rx:0, DET_RANGE_VELOCITY_041_Rx:0, DET_RANGE_VELOCITY_042_Rx:0, DET_RANGE_VELOCITY_043_Rx:0, DET_RANGE_VELOCITY_044_Rx:0, DET_RANGE_VELOCITY_ERR_041_Rx:0, DET_RANGE_VELOCITY_ERR_042_Rx:0, DET_RANGE_VELOCITY_ERR_043_Rx:0, DET_RANGE_VELOCITY_ERR_044_Rx:0, DET_RCS_041_Rx:0, DET_RCS_042_Rx:0, DET_RCS_043_Rx:0, DET_RCS_044_Rx:0, DET_SNR_041_Rx:0, DET_SNR_042_Rx:0, DET_SNR_043_Rx:0, DET_SNR_044_Rx:0, DET_SUPER_RES_TARGET_041_Rx:0, DET_SUPER_RES_TARGET_042_Rx:0, DET_SUPER_RES_TARGET_043_Rx:0, DET_SUPER_RES_TARGET_044_Rx:0]}, required-interface=Pi_SG_Fusion_Detections_041_044_AL
      Rp_SG_Fusion_Detections_045_048_AL: nonqueued-receiver-com-spec{data-element=Vdp_SG_Fusion_Detections_045_048_AL, init-value=fields=[DET_AZIMUTH_045_Rx:0, DET_AZIMUTH_046_Rx:0, DET_AZIMUTH_047_Rx:0, DET_AZIMUTH_048_Rx:0, DET_AZIMUTH_ERR_045_Rx:0, DET_AZIMUTH_ERR_046_Rx:0, DET_AZIMUTH_ERR_047_Rx:0, DET_AZIMUTH_ERR_048_Rx:0, DET_BELOW_RAIN_THOLD_045_Rx:0, DET_BELOW_RAIN_THOLD_046_Rx:0, DET_BELOW_RAIN_THOLD_047_Rx:0, DET_BELOW_RAIN_THOLD_048_Rx:0, DET_BI_STATIC_FLAG_045_Rx:0, DET_BI_STATIC_FLAG_046_Rx:0, DET_BI_STATIC_FLAG_047_Rx:0, DET_BI_STATIC_FLAG_048_Rx:0, DET_CONFD_AZIMUTH_045_Rx:0, DET_CONFD_AZIMUTH_046_Rx:0, DET_CONFD_AZIMUTH_047_Rx:0, DET_CONFD_AZIMUTH_048_Rx:0, DET_CONFD_ELEVATION_045_Rx:0, DET_CONFD_ELEVATION_046_Rx:0, DET_CONFD_ELEVATION_047_Rx:0, DET_CONFD_ELEVATION_048_Rx:0, DET_ELEVATION_045_Rx:0, DET_ELEVATION_046_Rx:0, DET_ELEVATION_047_Rx:0, DET_ELEVATION_048_Rx:0, DET_ELEVATION_ERR_045_Rx:0, DET_ELEVATION_ERR_046_Rx:0, DET_ELEVATION_ERR_047_Rx:0, DET_ELEVATION_ERR_048_Rx:0, DET_EXISTENCE_PROB_045_Rx:0, DET_EXISTENCE_PROB_046_Rx:0, DET_EXISTENCE_PROB_047_Rx:0, DET_EXISTENCE_PROB_048_Rx:0, DET_HVC_FLAG_045_Rx:0, DET_HVC_FLAG_046_Rx:0, DET_HVC_FLAG_047_Rx:0, DET_HVC_FLAG_048_Rx:0, DET_IDM_045_Rx:0, DET_IDM_046_Rx:0, DET_IDM_047_Rx:0, DET_IDM_048_Rx:0, DET_MH_CRC16_045_048_Rx:0, DET_MH_CYCLE_COUNTER_045_048_Rx:0, DET_MH_SCAN_INDEX_4LSB_045_048_Rx:0, DET_MTD_045_Rx:0, DET_MTD_046_Rx:0, DET_MTD_047_Rx:0, DET_MTD_048_Rx:0, DET_PROB_1STAZHYPO_045_Rx:0, DET_PROB_1STAZHYPO_046_Rx:0, DET_PROB_1STAZHYPO_047_Rx:0, DET_PROB_1STAZHYPO_048_Rx:0, DET_RANGE_045_Rx:0, DET_RANGE_046_Rx:0, DET_RANGE_047_Rx:0, DET_RANGE_048_Rx:0, DET_RANGE_ERR_045_Rx:0, DET_RANGE_ERR_046_Rx:0, DET_RANGE_ERR_047_Rx:0, DET_RANGE_ERR_048_Rx:0, DET_RANGE_VELOCITY_045_Rx:0, DET_RANGE_VELOCITY_046_Rx:0, DET_RANGE_VELOCITY_047_Rx:0, DET_RANGE_VELOCITY_048_Rx:0, DET_RANGE_VELOCITY_ERR_045_Rx:0, DET_RANGE_VELOCITY_ERR_046_Rx:0, DET_RANGE_VELOCITY_ERR_047_Rx:0, DET_RANGE_VELOCITY_ERR_048_Rx:0, DET_RCS_045_Rx:0, DET_RCS_046_Rx:0, DET_RCS_047_Rx:0, DET_RCS_048_Rx:0, DET_SNR_045_Rx:0, DET_SNR_046_Rx:0, DET_SNR_047_Rx:0, DET_SNR_048_Rx:0, DET_SUPER_RES_TARGET_045_Rx:0, DET_SUPER_RES_TARGET_046_Rx:0, DET_SUPER_RES_TARGET_047_Rx:0, DET_SUPER_RES_TARGET_048_Rx:0]}, required-interface=Pi_SG_Fusion_Detections_045_048_AL
      Rp_SG_Fusion_Detections_049_052_AL: nonqueued-receiver-com-spec{data-element=Vdp_SG_Fusion_Detections_049_052_AL, init-value=fields=[DET_AZIMUTH_049_Rx:0, DET_AZIMUTH_050_Rx:0, DET_AZIMUTH_051_Rx:0, DET_AZIMUTH_052_Rx:0, DET_AZIMUTH_ERR_049_Rx:0, DET_AZIMUTH_ERR_050_Rx:0, DET_AZIMUTH_ERR_051_Rx:0, DET_AZIMUTH_ERR_052_Rx:0, DET_BELOW_RAIN_THOLD_049_Rx:0, DET_BELOW_RAIN_THOLD_050_Rx:0, DET_BELOW_RAIN_THOLD_051_Rx:0, DET_BELOW_RAIN_THOLD_052_Rx:0, DET_BI_STATIC_FLAG_049_Rx:0, DET_BI_STATIC_FLAG_050_Rx:0, DET_BI_STATIC_FLAG_051_Rx:0, DET_BI_STATIC_FLAG_052_Rx:0, DET_CONFD_AZIMUTH_049_Rx:0, DET_CONFD_AZIMUTH_050_Rx:0, DET_CONFD_AZIMUTH_051_Rx:0, DET_CONFD_AZIMUTH_052_Rx:0, DET_CONFD_ELEVATION_049_Rx:0, DET_CONFD_ELEVATION_050_Rx:0, DET_CONFD_ELEVATION_051_Rx:0, DET_CONFD_ELEVATION_052_Rx:0, DET_ELEVATION_049_Rx:0, DET_ELEVATION_050_Rx:0, DET_ELEVATION_051_Rx:0, DET_ELEVATION_052_Rx:0, DET_ELEVATION_ERR_049_Rx:0, DET_ELEVATION_ERR_050_Rx:0, DET_ELEVATION_ERR_051_Rx:0, DET_ELEVATION_ERR_052_Rx:0, DET_EXISTENCE_PROB_049_Rx:0, DET_EXISTENCE_PROB_050_Rx:0, DET_EXISTENCE_PROB_051_Rx:0, DET_EXISTENCE_PROB_052_Rx:0, DET_HVC_FLAG_049_Rx:0, DET_HVC_FLAG_050_Rx:0, DET_HVC_FLAG_051_Rx:0, DET_HVC_FLAG_052_Rx:0, DET_IDM_049_Rx:0, DET_IDM_050_Rx:0, DET_IDM_051_Rx:0, DET_IDM_052_Rx:0, DET_MH_CRC16_049_052_Rx:0, DET_MH_CYCLE_COUNTER_049_052_Rx:0, DET_MH_SCAN_INDEX_4LSB_049_052_Rx:0, DET_MTD_049_Rx:0, DET_MTD_050_Rx:0, DET_MTD_051_Rx:0, DET_MTD_052_Rx:0, DET_PROB_1STAZHYPO_049_Rx:0, DET_PROB_1STAZHYPO_050_Rx:0, DET_PROB_1STAZHYPO_051_Rx:0, DET_PROB_1STAZHYPO_052_Rx:0, DET_RANGE_049_Rx:0, DET_RANGE_050_Rx:0, DET_RANGE_051_Rx:0, DET_RANGE_052_Rx:0, DET_RANGE_ERR_049_Rx:0, DET_RANGE_ERR_050_Rx:0, DET_RANGE_ERR_051_Rx:0, DET_RANGE_ERR_052_Rx:0, DET_RANGE_VELOCITY_049_Rx:0, DET_RANGE_VELOCITY_050_Rx:0, DET_RANGE_VELOCITY_051_Rx:0, DET_RANGE_VELOCITY_052_Rx:0, DET_RANGE_VELOCITY_ERR_049_Rx:0, DET_RANGE_VELOCITY_ERR_050_Rx:0, DET_RANGE_VELOCITY_ERR_051_Rx:0, DET_RANGE_VELOCITY_ERR_052_Rx:0, DET_RCS_049_Rx:0, DET_RCS_050_Rx:0, DET_RCS_051_Rx:0, DET_RCS_052_Rx:0, DET_SNR_049_Rx:0, DET_SNR_050_Rx:0, DET_SNR_051_Rx:0, DET_SNR_052_Rx:0, DET_SUPER_RES_TARGET_049_Rx:0, DET_SUPER_RES_TARGET_050_Rx:0, DET_SUPER_RES_TARGET_051_Rx:0, DET_SUPER_RES_TARGET_052_Rx:0]}, required-interface=Pi_SG_Fusion_Detections_049_052_AL
      Rp_SG_Fusion_Detections_053_056_AL: nonqueued-receiver-com-spec{data-element=Vdp_SG_Fusion_Detections_053_056_AL, init-value=fields=[DET_AZIMUTH_053_Rx:0, DET_AZIMUTH_054_Rx:0, DET_AZIMUTH_055_Rx:0, DET_AZIMUTH_056_Rx:0, DET_AZIMUTH_ERR_053_Rx:0, DET_AZIMUTH_ERR_054_Rx:0, DET_AZIMUTH_ERR_055_Rx:0, DET_AZIMUTH_ERR_056_Rx:0, DET_BELOW_RAIN_THOLD_053_Rx:0, DET_BELOW_RAIN_THOLD_054_Rx:0, DET_BELOW_RAIN_THOLD_055_Rx:0, DET_BELOW_RAIN_THOLD_056_Rx:0, DET_BI_STATIC_FLAG_053_Rx:0, DET_BI_STATIC_FLAG_054_Rx:0, DET_BI_STATIC_FLAG_055_Rx:0, DET_BI_STATIC_FLAG_056_Rx:0, DET_CONFD_AZIMUTH_053_Rx:0, DET_CONFD_AZIMUTH_054_Rx:0, DET_CONFD_AZIMUTH_055_Rx:0, DET_CONFD_AZIMUTH_056_Rx:0, DET_CONFD_ELEVATION_053_Rx:0, DET_CONFD_ELEVATION_054_Rx:0, DET_CONFD_ELEVATION_055_Rx:0, DET_CONFD_ELEVATION_056_Rx:0, DET_ELEVATION_053_Rx:0, DET_ELEVATION_054_Rx:0, DET_ELEVATION_055_Rx:0, DET_ELEVATION_056_Rx:0, DET_ELEVATION_ERR_053_Rx:0, DET_ELEVATION_ERR_054_Rx:0, DET_ELEVATION_ERR_055_Rx:0, DET_ELEVATION_ERR_056_Rx:0, DET_EXISTENCE_PROB_053_Rx:0, DET_EXISTENCE_PROB_054_Rx:0, DET_EXISTENCE_PROB_055_Rx:0, DET_EXISTENCE_PROB_056_Rx:0, DET_HVC_FLAG_053_Rx:0, DET_HVC_FLAG_054_Rx:0, DET_HVC_FLAG_055_Rx:0, DET_HVC_FLAG_056_Rx:0, DET_IDM_053_Rx:0, DET_IDM_054_Rx:0, DET_IDM_055_Rx:0, DET_IDM_056_Rx:0, DET_MH_CRC16_053_056_Rx:0, DET_MH_CYCLE_COUNTER_053_056_Rx:0, DET_MH_SCAN_INDEX_4LSB_053_056_Rx:0, DET_MTD_053_Rx:0, DET_MTD_054_Rx:0, DET_MTD_055_Rx:0, DET_MTD_056_Rx:0, DET_PROB_1STAZHYPO_053_Rx:0, DET_PROB_1STAZHYPO_054_Rx:0, DET_PROB_1STAZHYPO_055_Rx:0, DET_PROB_1STAZHYPO_056_Rx:0, DET_RANGE_053_Rx:0, DET_RANGE_054_Rx:0, DET_RANGE_055_Rx:0, DET_RANGE_056_Rx:0, DET_RANGE_ERR_053_Rx:0, DET_RANGE_ERR_054_Rx:0, DET_RANGE_ERR_055_Rx:0, DET_RANGE_ERR_056_Rx:0, DET_RANGE_VELOCITY_053_Rx:0, DET_RANGE_VELOCITY_054_Rx:0, DET_RANGE_VELOCITY_055_Rx:0, DET_RANGE_VELOCITY_056_Rx:0, DET_RANGE_VELOCITY_ERR_053_Rx:0, DET_RANGE_VELOCITY_ERR_054_Rx:0, DET_RANGE_VELOCITY_ERR_055_Rx:0, DET_RANGE_VELOCITY_ERR_056_Rx:0, DET_RCS_053_Rx:0, DET_RCS_054_Rx:0, DET_RCS_055_Rx:0, DET_RCS_056_Rx:0, DET_SNR_053_Rx:0, DET_SNR_054_Rx:0, DET_SNR_055_Rx:0, DET_SNR_056_Rx:0, DET_SUPER_RES_TARGET_053_Rx:0, DET_SUPER_RES_TARGET_054_Rx:0, DET_SUPER_RES_TARGET_055_Rx:0, DET_SUPER_RES_TARGET_056_Rx:0]}, required-interface=Pi_SG_Fusion_Detections_053_056_AL
      Rp_SG_Fusion_Detections_057_060_AL: nonqueued-receiver-com-spec{data-element=Vdp_SG_Fusion_Detections_057_060_AL, init-value=fields=[DET_AZIMUTH_057_Rx:0, DET_AZIMUTH_058_Rx:0, DET_AZIMUTH_059_Rx:0, DET_AZIMUTH_060_Rx:0, DET_AZIMUTH_ERR_057_Rx:0, DET_AZIMUTH_ERR_058_Rx:0, DET_AZIMUTH_ERR_059_Rx:0, DET_AZIMUTH_ERR_060_Rx:0, DET_BELOW_RAIN_THOLD_057_Rx:0, DET_BELOW_RAIN_THOLD_058_Rx:0, DET_BELOW_RAIN_THOLD_059_Rx:0, DET_BELOW_RAIN_THOLD_060_Rx:0, DET_BI_STATIC_FLAG_057_Rx:0, DET_BI_STATIC_FLAG_058_Rx:0, DET_BI_STATIC_FLAG_059_Rx:0, DET_BI_STATIC_FLAG_060_Rx:0, DET_CONFD_AZIMUTH_057_Rx:0, DET_CONFD_AZIMUTH_058_Rx:0, DET_CONFD_AZIMUTH_059_Rx:0, DET_CONFD_AZIMUTH_060_Rx:0, DET_CONFD_ELEVATION_057_Rx:0, DET_CONFD_ELEVATION_058_Rx:0, DET_CONFD_ELEVATION_059_Rx:0, DET_CONFD_ELEVATION_060_Rx:0, DET_ELEVATION_057_Rx:0, DET_ELEVATION_058_Rx:0, DET_ELEVATION_059_Rx:0, DET_ELEVATION_060_Rx:0, DET_ELEVATION_ERR_057_Rx:0, DET_ELEVATION_ERR_058_Rx:0, DET_ELEVATION_ERR_059_Rx:0, DET_ELEVATION_ERR_060_Rx:0, DET_EXISTENCE_PROB_057_Rx:0, DET_EXISTENCE_PROB_058_Rx:0, DET_EXISTENCE_PROB_059_Rx:0, DET_EXISTENCE_PROB_060_Rx:0, DET_HVC_FLAG_057_Rx:0, DET_HVC_FLAG_058_Rx:0, DET_HVC_FLAG_059_Rx:0, DET_HVC_FLAG_060_Rx:0, DET_IDM_057_Rx:0, DET_IDM_058_Rx:0, DET_IDM_059_Rx:0, DET_IDM_060_Rx:0, DET_MH_CRC16_057_060_Rx:0, DET_MH_CYCLE_COUNTER_057_060_Rx:0, DET_MH_SCAN_INDEX_4LSB_057_060_Rx:0, DET_MTD_057_Rx:0, DET_MTD_058_Rx:0, DET_MTD_059_Rx:0, DET_MTD_060_Rx:0, DET_PROB_1STAZHYPO_057_Rx:0, DET_PROB_1STAZHYPO_058_Rx:0, DET_PROB_1STAZHYPO_059_Rx:0, DET_PROB_1STAZHYPO_060_Rx:0, DET_RANGE_057_Rx:0, DET_RANGE_058_Rx:0, DET_RANGE_059_Rx:0, DET_RANGE_060_Rx:0, DET_RANGE_ERR_057_Rx:0, DET_RANGE_ERR_058_Rx:0, DET_RANGE_ERR_059_Rx:0, DET_RANGE_ERR_060_Rx:0, DET_RANGE_VELOCITY_057_Rx:0, DET_RANGE_VELOCITY_058_Rx:0, DET_RANGE_VELOCITY_059_Rx:0, DET_RANGE_VELOCITY_060_Rx:0, DET_RANGE_VELOCITY_ERR_057_Rx:0, DET_RANGE_VELOCITY_ERR_058_Rx:0, DET_RANGE_VELOCITY_ERR_059_Rx:0, DET_RANGE_VELOCITY_ERR_060_Rx:0, DET_RCS_057_Rx:0, DET_RCS_058_Rx:0, DET_RCS_059_Rx:0, DET_RCS_060_Rx:0, DET_SNR_057_Rx:0, DET_SNR_058_Rx:0, DET_SNR_059_Rx:0, DET_SNR_060_Rx:0, DET_SUPER_RES_TARGET_057_Rx:0, DET_SUPER_RES_TARGET_058_Rx:0, DET_SUPER_RES_TARGET_059_Rx:0, DET_SUPER_RES_TARGET_060_Rx:0]}, required-interface=Pi_SG_Fusion_Detections_057_060_AL
      Rp_SG_Fusion_Detections_061_064_AL: nonqueued-receiver-com-spec{data-element=Vdp_SG_Fusion_Detections_061_064_AL, init-value=fields=[DET_AZIMUTH_061_Rx:0, DET_AZIMUTH_062_Rx:0, DET_AZIMUTH_063_Rx:0, DET_AZIMUTH_064_Rx:0, DET_AZIMUTH_ERR_061_Rx:0, DET_AZIMUTH_ERR_062_Rx:0, DET_AZIMUTH_ERR_063_Rx:0, DET_AZIMUTH_ERR_064_Rx:0, DET_BELOW_RAIN_THOLD_061_Rx:0, DET_BELOW_RAIN_THOLD_062_Rx:0, DET_BELOW_RAIN_THOLD_063_Rx:0, DET_BELOW_RAIN_THOLD_064_Rx:0, DET_BI_STATIC_FLAG_061_Rx:0, DET_BI_STATIC_FLAG_062_Rx:0, DET_BI_STATIC_FLAG_063_Rx:0, DET_BI_STATIC_FLAG_064_Rx:0, DET_CONFD_AZIMUTH_061_Rx:0, DET_CONFD_AZIMUTH_062_Rx:0, DET_CONFD_AZIMUTH_063_Rx:0, DET_CONFD_AZIMUTH_064_Rx:0, DET_CONFD_ELEVATION_061_Rx:0, DET_CONFD_ELEVATION_062_Rx:0, DET_CONFD_ELEVATION_063_Rx:0, DET_CONFD_ELEVATION_064_Rx:0, DET_ELEVATION_061_Rx:0, DET_ELEVATION_062_Rx:0, DET_ELEVATION_063_Rx:0, DET_ELEVATION_064_Rx:0, DET_ELEVATION_ERR_061_Rx:0, DET_ELEVATION_ERR_062_Rx:0, DET_ELEVATION_ERR_063_Rx:0, DET_ELEVATION_ERR_064_Rx:0, DET_EXISTENCE_PROB_061_Rx:0, DET_EXISTENCE_PROB_062_Rx:0, DET_EXISTENCE_PROB_063_Rx:0, DET_EXISTENCE_PROB_064_Rx:0, DET_HVC_FLAG_061_Rx:0, DET_HVC_FLAG_062_Rx:0, DET_HVC_FLAG_063_Rx:0, DET_HVC_FLAG_064_Rx:0, DET_IDM_061_Rx:0, DET_IDM_062_Rx:0, DET_IDM_063_Rx:0, DET_IDM_064_Rx:0, DET_MH_CRC16_061_064_Rx:0, DET_MH_CYCLE_COUNTER_061_064_Rx:0, DET_MH_SCAN_INDEX_4LSB_061_064_Rx:0, DET_MTD_061_Rx:0, DET_MTD_062_Rx:0, DET_MTD_063_Rx:0, DET_MTD_064_Rx:0, DET_PROB_1STAZHYPO_061_Rx:0, DET_PROB_1STAZHYPO_062_Rx:0, DET_PROB_1STAZHYPO_063_Rx:0, DET_PROB_1STAZHYPO_064_Rx:0, DET_RANGE_061_Rx:0, DET_RANGE_062_Rx:0, DET_RANGE_063_Rx:0, DET_RANGE_064_Rx:0, DET_RANGE_ERR_061_Rx:0, DET_RANGE_ERR_062_Rx:0, DET_RANGE_ERR_063_Rx:0, DET_RANGE_ERR_064_Rx:0, DET_RANGE_VELOCITY_061_Rx:0, DET_RANGE_VELOCITY_062_Rx:0, DET_RANGE_VELOCITY_063_Rx:0, DET_RANGE_VELOCITY_064_Rx:0, DET_RANGE_VELOCITY_ERR_061_Rx:0, DET_RANGE_VELOCITY_ERR_062_Rx:0, DET_RANGE_VELOCITY_ERR_063_Rx:0, DET_RANGE_VELOCITY_ERR_064_Rx:0, DET_RCS_061_Rx:0, DET_RCS_062_Rx:0, DET_RCS_063_Rx:0, DET_RCS_064_Rx:0, DET_SNR_061_Rx:0, DET_SNR_062_Rx:0, DET_SNR_063_Rx:0, DET_SNR_064_Rx:0, DET_SUPER_RES_TARGET_061_Rx:0, DET_SUPER_RES_TARGET_062_Rx:0, DET_SUPER_RES_TARGET_063_Rx:0, DET_SUPER_RES_TARGET_064_Rx:0]}, required-interface=Pi_SG_Fusion_Detections_061_064_AL
      Rp_SG_Fusion_Detections_065_068_AL: nonqueued-receiver-com-spec{data-element=Vdp_SG_Fusion_Detections_065_068_AL, init-value=fields=[DET_AZIMUTH_065_Rx:0, DET_AZIMUTH_066_Rx:0, DET_AZIMUTH_067_Rx:0, DET_AZIMUTH_068_Rx:0, DET_AZIMUTH_ERR_065_Rx:0, DET_AZIMUTH_ERR_066_Rx:0, DET_AZIMUTH_ERR_067_Rx:0, DET_AZIMUTH_ERR_068_Rx:0, DET_BELOW_RAIN_THOLD_065_Rx:0, DET_BELOW_RAIN_THOLD_066_Rx:0, DET_BELOW_RAIN_THOLD_067_Rx:0, DET_BELOW_RAIN_THOLD_068_Rx:0, DET_BI_STATIC_FLAG_065_Rx:0, DET_BI_STATIC_FLAG_066_Rx:0, DET_BI_STATIC_FLAG_067_Rx:0, DET_BI_STATIC_FLAG_068_Rx:0, DET_CONFD_AZIMUTH_065_Rx:0, DET_CONFD_AZIMUTH_066_Rx:0, DET_CONFD_AZIMUTH_067_Rx:0, DET_CONFD_AZIMUTH_068_Rx:0, DET_CONFD_ELEVATION_065_Rx:0, DET_CONFD_ELEVATION_066_Rx:0, DET_CONFD_ELEVATION_067_Rx:0, DET_CONFD_ELEVATION_068_Rx:0, DET_ELEVATION_065_Rx:0, DET_ELEVATION_066_Rx:0, DET_ELEVATION_067_Rx:0, DET_ELEVATION_068_Rx:0, DET_ELEVATION_ERR_065_Rx:0, DET_ELEVATION_ERR_066_Rx:0, DET_ELEVATION_ERR_067_Rx:0, DET_ELEVATION_ERR_068_Rx:0, DET_EXISTENCE_PROB_065_Rx:0, DET_EXISTENCE_PROB_066_Rx:0, DET_EXISTENCE_PROB_067_Rx:0, DET_EXISTENCE_PROB_068_Rx:0, DET_HVC_FLAG_065_Rx:0, DET_HVC_FLAG_066_Rx:0, DET_HVC_FLAG_067_Rx:0, DET_HVC_FLAG_068_Rx:0, DET_IDM_065_Rx:0, DET_IDM_066_Rx:0, DET_IDM_067_Rx:0, DET_IDM_068_Rx:0, DET_MH_CRC16_065_068_Rx:0, DET_MH_CYCLE_COUNTER_065_068_Rx:0, DET_MH_SCAN_INDEX_4LSB_065_068_Rx:0, DET_MTD_065_Rx:0, DET_MTD_066_Rx:0, DET_MTD_067_Rx:0, DET_MTD_068_Rx:0, DET_PROB_1STAZHYPO_065_Rx:0, DET_PROB_1STAZHYPO_066_Rx:0, DET_PROB_1STAZHYPO_067_Rx:0, DET_PROB_1STAZHYPO_068_Rx:0, DET_RANGE_065_Rx:0, DET_RANGE_066_Rx:0, DET_RANGE_067_Rx:0, DET_RANGE_068_Rx:0, DET_RANGE_ERR_065_Rx:0, DET_RANGE_ERR_066_Rx:0, DET_RANGE_ERR_067_Rx:0, DET_RANGE_ERR_068_Rx:0, DET_RANGE_VELOCITY_065_Rx:0, DET_RANGE_VELOCITY_066_Rx:0, DET_RANGE_VELOCITY_067_Rx:0, DET_RANGE_VELOCITY_068_Rx:0, DET_RANGE_VELOCITY_ERR_065_Rx:0, DET_RANGE_VELOCITY_ERR_066_Rx:0, DET_RANGE_VELOCITY_ERR_067_Rx:0, DET_RANGE_VELOCITY_ERR_068_Rx:0, DET_RCS_065_Rx:0, DET_RCS_066_Rx:0, DET_RCS_067_Rx:0, DET_RCS_068_Rx:0, DET_SNR_065_Rx:0, DET_SNR_066_Rx:0, DET_SNR_067_Rx:0, DET_SNR_068_Rx:0, DET_SUPER_RES_TARGET_065_Rx:0, DET_SUPER_RES_TARGET_066_Rx:0, DET_SUPER_RES_TARGET_067_Rx:0, DET_SUPER_RES_TARGET_068_Rx:0]}, required-interface=Pi_SG_Fusion_Detections_065_068_AL
      Rp_SG_Fusion_Detections_069_072_AL: nonqueued-receiver-com-spec{data-element=Vdp_SG_Fusion_Detections_069_072_AL, init-value=fields=[DET_AZIMUTH_069_Rx:0, DET_AZIMUTH_070_Rx:0, DET_AZIMUTH_071_Rx:0, DET_AZIMUTH_072_Rx:0, DET_AZIMUTH_ERR_069_Rx:0, DET_AZIMUTH_ERR_070_Rx:0, DET_AZIMUTH_ERR_071_Rx:0, DET_AZIMUTH_ERR_072_Rx:0, DET_BELOW_RAIN_THOLD_069_Rx:0, DET_BELOW_RAIN_THOLD_070_Rx:0, DET_BELOW_RAIN_THOLD_071_Rx:0, DET_BELOW_RAIN_THOLD_072_Rx:0, DET_BI_STATIC_FLAG_069_Rx:0, DET_BI_STATIC_FLAG_070_Rx:0, DET_BI_STATIC_FLAG_071_Rx:0, DET_BI_STATIC_FLAG_072_Rx:0, DET_CONFD_AZIMUTH_069_Rx:0, DET_CONFD_AZIMUTH_070_Rx:0, DET_CONFD_AZIMUTH_071_Rx:0, DET_CONFD_AZIMUTH_072_Rx:0, DET_CONFD_ELEVATION_069_Rx:0, DET_CONFD_ELEVATION_070_Rx:0, DET_CONFD_ELEVATION_071_Rx:0, DET_CONFD_ELEVATION_072_Rx:0, DET_ELEVATION_069_Rx:0, DET_ELEVATION_070_Rx:0, DET_ELEVATION_071_Rx:0, DET_ELEVATION_072_Rx:0, DET_ELEVATION_ERR_069_Rx:0, DET_ELEVATION_ERR_070_Rx:0, DET_ELEVATION_ERR_071_Rx:0, DET_ELEVATION_ERR_072_Rx:0, DET_EXISTENCE_PROB_069_Rx:0, DET_EXISTENCE_PROB_070_Rx:0, DET_EXISTENCE_PROB_071_Rx:0, DET_EXISTENCE_PROB_072_Rx:0, DET_HVC_FLAG_069_Rx:0, DET_HVC_FLAG_070_Rx:0, DET_HVC_FLAG_071_Rx:0, DET_HVC_FLAG_072_Rx:0, DET_IDM_069_Rx:0, DET_IDM_070_Rx:0, DET_IDM_071_Rx:0, DET_IDM_072_Rx:0, DET_MH_CRC16_069_072_Rx:0, DET_MH_CYCLE_COUNTER_069_072_Rx:0, DET_MH_SCAN_INDEX_4LSB_069_072_Rx:0, DET_MTD_069_Rx:0, DET_MTD_070_Rx:0, DET_MTD_071_Rx:0, DET_MTD_072_Rx:0, DET_PROB_1STAZHYPO_069_Rx:0, DET_PROB_1STAZHYPO_070_Rx:0, DET_PROB_1STAZHYPO_071_Rx:0, DET_PROB_1STAZHYPO_072_Rx:0, DET_RANGE_069_Rx:0, DET_RANGE_070_Rx:0, DET_RANGE_071_Rx:0, DET_RANGE_072_Rx:0, DET_RANGE_ERR_069_Rx:0, DET_RANGE_ERR_070_Rx:0, DET_RANGE_ERR_071_Rx:0, DET_RANGE_ERR_072_Rx:0, DET_RANGE_VELOCITY_069_Rx:0, DET_RANGE_VELOCITY_070_Rx:0, DET_RANGE_VELOCITY_071_Rx:0, DET_RANGE_VELOCITY_072_Rx:0, DET_RANGE_VELOCITY_ERR_069_Rx:0, DET_RANGE_VELOCITY_ERR_070_Rx:0, DET_RANGE_VELOCITY_ERR_071_Rx:0, DET_RANGE_VELOCITY_ERR_072_Rx:0, DET_RCS_069_Rx:0, DET_RCS_070_Rx:0, DET_RCS_071_Rx:0, DET_RCS_072_Rx:0, DET_SNR_069_Rx:0, DET_SNR_070_Rx:0, DET_SNR_071_Rx:0, DET_SNR_072_Rx:0, DET_SUPER_RES_TARGET_069_Rx:0, DET_SUPER_RES_TARGET_070_Rx:0, DET_SUPER_RES_TARGET_071_Rx:0, DET_SUPER_RES_TARGET_072_Rx:0]}, required-interface=Pi_SG_Fusion_Detections_069_072_AL
      Rp_SG_Fusion_Detections_073_076_AL: nonqueued-receiver-com-spec{data-element=Vdp_SG_Fusion_Detections_073_076_AL, init-value=fields=[DET_AZIMUTH_073_Rx:0, DET_AZIMUTH_074_Rx:0, DET_AZIMUTH_075_Rx:0, DET_AZIMUTH_076_Rx:0, DET_AZIMUTH_ERR_073_Rx:0, DET_AZIMUTH_ERR_074_Rx:0, DET_AZIMUTH_ERR_075_Rx:0, DET_AZIMUTH_ERR_076_Rx:0, DET_BELOW_RAIN_THOLD_073_Rx:0, DET_BELOW_RAIN_THOLD_074_Rx:0, DET_BELOW_RAIN_THOLD_075_Rx:0, DET_BELOW_RAIN_THOLD_076_Rx:0, DET_BI_STATIC_FLAG_073_Rx:0, DET_BI_STATIC_FLAG_074_Rx:0, DET_BI_STATIC_FLAG_075_Rx:0, DET_BI_STATIC_FLAG_076_Rx:0, DET_CONFD_AZIMUTH_073_Rx:0, DET_CONFD_AZIMUTH_074_Rx:0, DET_CONFD_AZIMUTH_075_Rx:0, DET_CONFD_AZIMUTH_076_Rx:0, DET_CONFD_ELEVATION_073_Rx:0, DET_CONFD_ELEVATION_074_Rx:0, DET_CONFD_ELEVATION_075_Rx:0, DET_CONFD_ELEVATION_076_Rx:0, DET_ELEVATION_073_Rx:0, DET_ELEVATION_074_Rx:0, DET_ELEVATION_075_Rx:0, DET_ELEVATION_076_Rx:0, DET_ELEVATION_ERR_073_Rx:0, DET_ELEVATION_ERR_074_Rx:0, DET_ELEVATION_ERR_075_Rx:0, DET_ELEVATION_ERR_076_Rx:0, DET_EXISTENCE_PROB_073_Rx:0, DET_EXISTENCE_PROB_074_Rx:0, DET_EXISTENCE_PROB_075_Rx:0, DET_EXISTENCE_PROB_076_Rx:0, DET_HVC_FLAG_073_Rx:0, DET_HVC_FLAG_074_Rx:0, DET_HVC_FLAG_075_Rx:0, DET_HVC_FLAG_076_Rx:0, DET_IDM_073_Rx:0, DET_IDM_074_Rx:0, DET_IDM_075_Rx:0, DET_IDM_076_Rx:0, DET_MH_CRC16_073_076_Rx:0, DET_MH_CYCLE_COUNTER_073_076_Rx:0, DET_MH_SCAN_INDEX_4LSB_073_076_Rx:0, DET_MTD_073_Rx:0, DET_MTD_074_Rx:0, DET_MTD_075_Rx:0, DET_MTD_076_Rx:0, DET_PROB_1STAZHYPO_073_Rx:0, DET_PROB_1STAZHYPO_074_Rx:0, DET_PROB_1STAZHYPO_075_Rx:0, DET_PROB_1STAZHYPO_076_Rx:0, DET_RANGE_073_Rx:0, DET_RANGE_074_Rx:0, DET_RANGE_075_Rx:0, DET_RANGE_076_Rx:0, DET_RANGE_ERR_073_Rx:0, DET_RANGE_ERR_074_Rx:0, DET_RANGE_ERR_075_Rx:0, DET_RANGE_ERR_076_Rx:0, DET_RANGE_VELOCITY_073_Rx:0, DET_RANGE_VELOCITY_074_Rx:0, DET_RANGE_VELOCITY_075_Rx:0, DET_RANGE_VELOCITY_076_Rx:0, DET_RANGE_VELOCITY_ERR_073_Rx:0, DET_RANGE_VELOCITY_ERR_074_Rx:0, DET_RANGE_VELOCITY_ERR_075_Rx:0, DET_RANGE_VELOCITY_ERR_076_Rx:0, DET_RCS_073_Rx:0, DET_RCS_074_Rx:0, DET_RCS_075_Rx:0, DET_RCS_076_Rx:0, DET_SNR_073_Rx:0, DET_SNR_074_Rx:0, DET_SNR_075_Rx:0, DET_SNR_076_Rx:0, DET_SUPER_RES_TARGET_073_Rx:0, DET_SUPER_RES_TARGET_074_Rx:0, DET_SUPER_RES_TARGET_075_Rx:0, DET_SUPER_RES_TARGET_076_Rx:0]}, required-interface=Pi_SG_Fusion_Detections_073_076_AL
      Rp_SG_Fusion_Detections_077_080_AL: nonqueued-receiver-com-spec{data-element=Vdp_SG_Fusion_Detections_077_080_AL, init-value=fields=[DET_AZIMUTH_077_Rx:0, DET_AZIMUTH_078_Rx:0, DET_AZIMUTH_079_Rx:0, DET_AZIMUTH_080_Rx:0, DET_AZIMUTH_ERR_077_Rx:0, DET_AZIMUTH_ERR_078_Rx:0, DET_AZIMUTH_ERR_079_Rx:0, DET_AZIMUTH_ERR_080_Rx:0, DET_BELOW_RAIN_THOLD_077_Rx:0, DET_BELOW_RAIN_THOLD_078_Rx:0, DET_BELOW_RAIN_THOLD_079_Rx:0, DET_BELOW_RAIN_THOLD_080_Rx:0, DET_BI_STATIC_FLAG_077_Rx:0, DET_BI_STATIC_FLAG_078_Rx:0, DET_BI_STATIC_FLAG_079_Rx:0, DET_BI_STATIC_FLAG_080_Rx:0, DET_CONFD_AZIMUTH_077_Rx:0, DET_CONFD_AZIMUTH_078_Rx:0, DET_CONFD_AZIMUTH_079_Rx:0, DET_CONFD_AZIMUTH_080_Rx:0, DET_CONFD_ELEVATION_077_Rx:0, DET_CONFD_ELEVATION_078_Rx:0, DET_CONFD_ELEVATION_079_Rx:0, DET_CONFD_ELEVATION_080_Rx:0, DET_ELEVATION_077_Rx:0, DET_ELEVATION_078_Rx:0, DET_ELEVATION_079_Rx:0, DET_ELEVATION_080_Rx:0, DET_ELEVATION_ERR_077_Rx:0, DET_ELEVATION_ERR_078_Rx:0, DET_ELEVATION_ERR_079_Rx:0, DET_ELEVATION_ERR_080_Rx:0, DET_EXISTENCE_PROB_077_Rx:0, DET_EXISTENCE_PROB_078_Rx:0, DET_EXISTENCE_PROB_079_Rx:0, DET_EXISTENCE_PROB_080_Rx:0, DET_HVC_FLAG_077_Rx:0, DET_HVC_FLAG_078_Rx:0, DET_HVC_FLAG_079_Rx:0, DET_HVC_FLAG_080_Rx:0, DET_IDM_077_Rx:0, DET_IDM_078_Rx:0, DET_IDM_079_Rx:0, DET_IDM_080_Rx:0, DET_MH_CRC16_077_080_Rx:0, DET_MH_CYCLE_COUNTER_077_080_Rx:0, DET_MH_SCAN_INDEX_4LSB_077_080_Rx:0, DET_MTD_077_Rx:0, DET_MTD_078_Rx:0, DET_MTD_079_Rx:0, DET_MTD_080_Rx:0, DET_PROB_1STAZHYPO_077_Rx:0, DET_PROB_1STAZHYPO_078_Rx:0, DET_PROB_1STAZHYPO_079_Rx:0, DET_PROB_1STAZHYPO_080_Rx:0, DET_RANGE_077_Rx:0, DET_RANGE_078_Rx:0, DET_RANGE_079_Rx:0, DET_RANGE_080_Rx:0, DET_RANGE_ERR_077_Rx:0, DET_RANGE_ERR_078_Rx:0, DET_RANGE_ERR_079_Rx:0, DET_RANGE_ERR_080_Rx:0, DET_RANGE_VELOCITY_077_Rx:0, DET_RANGE_VELOCITY_078_Rx:0, DET_RANGE_VELOCITY_079_Rx:0, DET_RANGE_VELOCITY_080_Rx:0, DET_RANGE_VELOCITY_ERR_077_Rx:0, DET_RANGE_VELOCITY_ERR_078_Rx:0, DET_RANGE_VELOCITY_ERR_079_Rx:0, DET_RANGE_VELOCITY_ERR_080_Rx:0, DET_RCS_077_Rx:0, DET_RCS_078_Rx:0, DET_RCS_079_Rx:0, DET_RCS_080_Rx:0, DET_SNR_077_Rx:0, DET_SNR_078_Rx:0, DET_SNR_079_Rx:0, DET_SNR_080_Rx:0, DET_SUPER_RES_TARGET_077_Rx:0, DET_SUPER_RES_TARGET_078_Rx:0, DET_SUPER_RES_TARGET_079_Rx:0, DET_SUPER_RES_TARGET_080_Rx:0]}, required-interface=Pi_SG_Fusion_Detections_077_080_AL
      Rp_SG_Fusion_Detections_081_084_AL: nonqueued-receiver-com-spec{data-element=Vdp_SG_Fusion_Detections_081_084_AL, init-value=fields=[DET_AZIMUTH_081_Rx:0, DET_AZIMUTH_082_Rx:0, DET_AZIMUTH_083_Rx:0, DET_AZIMUTH_084_Rx:0, DET_AZIMUTH_ERR_081_Rx:0, DET_AZIMUTH_ERR_082_Rx:0, DET_AZIMUTH_ERR_083_Rx:0, DET_AZIMUTH_ERR_084_Rx:0, DET_BELOW_RAIN_THOLD_081_Rx:0, DET_BELOW_RAIN_THOLD_082_Rx:0, DET_BELOW_RAIN_THOLD_083_Rx:0, DET_BELOW_RAIN_THOLD_084_Rx:0, DET_BI_STATIC_FLAG_081_Rx:0, DET_BI_STATIC_FLAG_082_Rx:0, DET_BI_STATIC_FLAG_083_Rx:0, DET_BI_STATIC_FLAG_084_Rx:0, DET_CONFD_AZIMUTH_081_Rx:0, DET_CONFD_AZIMUTH_082_Rx:0, DET_CONFD_AZIMUTH_083_Rx:0, DET_CONFD_AZIMUTH_084_Rx:0, DET_CONFD_ELEVATION_081_Rx:0, DET_CONFD_ELEVATION_082_Rx:0, DET_CONFD_ELEVATION_083_Rx:0, DET_CONFD_ELEVATION_084_Rx:0, DET_ELEVATION_081_Rx:0, DET_ELEVATION_082_Rx:0, DET_ELEVATION_083_Rx:0, DET_ELEVATION_084_Rx:0, DET_ELEVATION_ERR_081_Rx:0, DET_ELEVATION_ERR_082_Rx:0, DET_ELEVATION_ERR_083_Rx:0, DET_ELEVATION_ERR_084_Rx:0, DET_EXISTENCE_PROB_081_Rx:0, DET_EXISTENCE_PROB_082_Rx:0, DET_EXISTENCE_PROB_083_Rx:0, DET_EXISTENCE_PROB_084_Rx:0, DET_HVC_FLAG_081_Rx:0, DET_HVC_FLAG_082_Rx:0, DET_HVC_FLAG_083_Rx:0, DET_HVC_FLAG_084_Rx:0, DET_IDM_081_Rx:0, DET_IDM_082_Rx:0, DET_IDM_083_Rx:0, DET_IDM_084_Rx:0, DET_MH_CRC16_081_084_Rx:0, DET_MH_CYCLE_COUNTER_081_084_Rx:0, DET_MH_SCAN_INDEX_4LSB_081_084_Rx:0, DET_MTD_081_Rx:0, DET_MTD_082_Rx:0, DET_MTD_083_Rx:0, DET_MTD_084_Rx:0, DET_PROB_1STAZHYPO_081_Rx:0, DET_PROB_1STAZHYPO_082_Rx:0, DET_PROB_1STAZHYPO_083_Rx:0, DET_PROB_1STAZHYPO_084_Rx:0, DET_RANGE_081_Rx:0, DET_RANGE_082_Rx:0, DET_RANGE_083_Rx:0, DET_RANGE_084_Rx:0, DET_RANGE_ERR_081_Rx:0, DET_RANGE_ERR_082_Rx:0, DET_RANGE_ERR_083_Rx:0, DET_RANGE_ERR_084_Rx:0, DET_RANGE_VELOCITY_081_Rx:0, DET_RANGE_VELOCITY_082_Rx:0, DET_RANGE_VELOCITY_083_Rx:0, DET_RANGE_VELOCITY_084_Rx:0, DET_RANGE_VELOCITY_ERR_081_Rx:0, DET_RANGE_VELOCITY_ERR_082_Rx:0, DET_RANGE_VELOCITY_ERR_083_Rx:0, DET_RANGE_VELOCITY_ERR_084_Rx:0, DET_RCS_081_Rx:0, DET_RCS_082_Rx:0, DET_RCS_083_Rx:0, DET_RCS_084_Rx:0, DET_SNR_081_Rx:0, DET_SNR_082_Rx:0, DET_SNR_083_Rx:0, DET_SNR_084_Rx:0, DET_SUPER_RES_TARGET_081_Rx:0, DET_SUPER_RES_TARGET_082_Rx:0, DET_SUPER_RES_TARGET_083_Rx:0, DET_SUPER_RES_TARGET_084_Rx:0]}, required-interface=Pi_SG_Fusion_Detections_081_084_AL
      Rp_SG_Fusion_Detections_085_088_AL: nonqueued-receiver-com-spec{data-element=Vdp_SG_Fusion_Detections_085_088_AL, init-value=fields=[DET_AZIMUTH_085_Rx:0, DET_AZIMUTH_086_Rx:0, DET_AZIMUTH_087_Rx:0, DET_AZIMUTH_088_Rx:0, DET_AZIMUTH_ERR_085_Rx:0, DET_AZIMUTH_ERR_086_Rx:0, DET_AZIMUTH_ERR_087_Rx:0, DET_AZIMUTH_ERR_088_Rx:0, DET_BELOW_RAIN_THOLD_085_Rx:0, DET_BELOW_RAIN_THOLD_086_Rx:0, DET_BELOW_RAIN_THOLD_087_Rx:0, DET_BELOW_RAIN_THOLD_088_Rx:0, DET_BI_STATIC_FLAG_085_Rx:0, DET_BI_STATIC_FLAG_086_Rx:0, DET_BI_STATIC_FLAG_087_Rx:0, DET_BI_STATIC_FLAG_088_Rx:0, DET_CONFD_AZIMUTH_085_Rx:0, DET_CONFD_AZIMUTH_086_Rx:0, DET_CONFD_AZIMUTH_087_Rx:0, DET_CONFD_AZIMUTH_088_Rx:0, DET_CONFD_ELEVATION_085_Rx:0, DET_CONFD_ELEVATION_086_Rx:0, DET_CONFD_ELEVATION_087_Rx:0, DET_CONFD_ELEVATION_088_Rx:0, DET_ELEVATION_085_Rx:0, DET_ELEVATION_086_Rx:0, DET_ELEVATION_087_Rx:0, DET_ELEVATION_088_Rx:0, DET_ELEVATION_ERR_085_Rx:0, DET_ELEVATION_ERR_086_Rx:0, DET_ELEVATION_ERR_087_Rx:0, DET_ELEVATION_ERR_088_Rx:0, DET_EXISTENCE_PROB_085_Rx:0, DET_EXISTENCE_PROB_086_Rx:0, DET_EXISTENCE_PROB_087_Rx:0, DET_EXISTENCE_PROB_088_Rx:0, DET_HVC_FLAG_085_Rx:0, DET_HVC_FLAG_086_Rx:0, DET_HVC_FLAG_087_Rx:0, DET_HVC_FLAG_088_Rx:0, DET_IDM_085_Rx:0, DET_IDM_086_Rx:0, DET_IDM_087_Rx:0, DET_IDM_088_Rx:0, DET_MH_CRC16_085_088_Rx:0, DET_MH_CYCLE_COUNTER_085_088_Rx:0, DET_MH_SCAN_INDEX_4LSB_085_088_Rx:0, DET_MTD_085_Rx:0, DET_MTD_086_Rx:0, DET_MTD_087_Rx:0, DET_MTD_088_Rx:0, DET_PROB_1STAZHYPO_085_Rx:0, DET_PROB_1STAZHYPO_086_Rx:0, DET_PROB_1STAZHYPO_087_Rx:0, DET_PROB_1STAZHYPO_088_Rx:0, DET_RANGE_085_Rx:0, DET_RANGE_086_Rx:0, DET_RANGE_087_Rx:0, DET_RANGE_088_Rx:0, DET_RANGE_ERR_085_Rx:0, DET_RANGE_ERR_086_Rx:0, DET_RANGE_ERR_087_Rx:0, DET_RANGE_ERR_088_Rx:0, DET_RANGE_VELOCITY_085_Rx:0, DET_RANGE_VELOCITY_086_Rx:0, DET_RANGE_VELOCITY_087_Rx:0, DET_RANGE_VELOCITY_088_Rx:0, DET_RANGE_VELOCITY_ERR_085_Rx:0, DET_RANGE_VELOCITY_ERR_086_Rx:0, DET_RANGE_VELOCITY_ERR_087_Rx:0, DET_RANGE_VELOCITY_ERR_088_Rx:0, DET_RCS_085_Rx:0, DET_RCS_086_Rx:0, DET_RCS_087_Rx:0, DET_RCS_088_Rx:0, DET_SNR_085_Rx:0, DET_SNR_086_Rx:0, DET_SNR_087_Rx:0, DET_SNR_088_Rx:0, DET_SUPER_RES_TARGET_085_Rx:0, DET_SUPER_RES_TARGET_086_Rx:0, DET_SUPER_RES_TARGET_087_Rx:0, DET_SUPER_RES_TARGET_088_Rx:0]}, required-interface=Pi_SG_Fusion_Detections_085_088_AL
      Rp_SG_Fusion_Detections_089_092_AL: nonqueued-receiver-com-spec{data-element=Vdp_SG_Fusion_Detections_089_092_AL, init-value=fields=[DET_AZIMUTH_089_Rx:0, DET_AZIMUTH_090_Rx:0, DET_AZIMUTH_091_Rx:0, DET_AZIMUTH_092_Rx:0, DET_AZIMUTH_ERR_089_Rx:0, DET_AZIMUTH_ERR_090_Rx:0, DET_AZIMUTH_ERR_091_Rx:0, DET_AZIMUTH_ERR_092_Rx:0, DET_BELOW_RAIN_THOLD_089_Rx:0, DET_BELOW_RAIN_THOLD_090_Rx:0, DET_BELOW_RAIN_THOLD_091_Rx:0, DET_BELOW_RAIN_THOLD_092_Rx:0, DET_BI_STATIC_FLAG_089_Rx:0, DET_BI_STATIC_FLAG_090_Rx:0, DET_BI_STATIC_FLAG_091_Rx:0, DET_BI_STATIC_FLAG_092_Rx:0, DET_CONFD_AZIMUTH_089_Rx:0, DET_CONFD_AZIMUTH_090_Rx:0, DET_CONFD_AZIMUTH_091_Rx:0, DET_CONFD_AZIMUTH_092_Rx:0, DET_CONFD_ELEVATION_089_Rx:0, DET_CONFD_ELEVATION_090_Rx:0, DET_CONFD_ELEVATION_091_Rx:0, DET_CONFD_ELEVATION_092_Rx:0, DET_ELEVATION_089_Rx:0, DET_ELEVATION_090_Rx:0, DET_ELEVATION_091_Rx:0, DET_ELEVATION_092_Rx:0, DET_ELEVATION_ERR_089_Rx:0, DET_ELEVATION_ERR_090_Rx:0, DET_ELEVATION_ERR_091_Rx:0, DET_ELEVATION_ERR_092_Rx:0, DET_EXISTENCE_PROB_089_Rx:0, DET_EXISTENCE_PROB_090_Rx:0, DET_EXISTENCE_PROB_091_Rx:0, DET_EXISTENCE_PROB_092_Rx:0, DET_HVC_FLAG_089_Rx:0, DET_HVC_FLAG_090_Rx:0, DET_HVC_FLAG_091_Rx:0, DET_HVC_FLAG_092_Rx:0, DET_IDM_089_Rx:0, DET_IDM_090_Rx:0, DET_IDM_091_Rx:0, DET_IDM_092_Rx:0, DET_MH_CRC16_089_092_Rx:0, DET_MH_CYCLE_COUNTER_089_092_Rx:0, DET_MH_SCAN_INDEX_4LSB_089_092_Rx:0, DET_MTD_089_Rx:0, DET_MTD_090_Rx:0, DET_MTD_091_Rx:0, DET_MTD_092_Rx:0, DET_PROB_1STAZHYPO_089_Rx:0, DET_PROB_1STAZHYPO_090_Rx:0, DET_PROB_1STAZHYPO_091_Rx:0, DET_PROB_1STAZHYPO_092_Rx:0, DET_RANGE_089_Rx:0, DET_RANGE_090_Rx:0, DET_RANGE_091_Rx:0, DET_RANGE_092_Rx:0, DET_RANGE_ERR_089_Rx:0, DET_RANGE_ERR_090_Rx:0, DET_RANGE_ERR_091_Rx:0, DET_RANGE_ERR_092_Rx:0, DET_RANGE_VELOCITY_089_Rx:0, DET_RANGE_VELOCITY_090_Rx:0, DET_RANGE_VELOCITY_091_Rx:0, DET_RANGE_VELOCITY_092_Rx:0, DET_RANGE_VELOCITY_ERR_089_Rx:0, DET_RANGE_VELOCITY_ERR_090_Rx:0, DET_RANGE_VELOCITY_ERR_091_Rx:0, DET_RANGE_VELOCITY_ERR_092_Rx:0, DET_RCS_089_Rx:0, DET_RCS_090_Rx:0, DET_RCS_091_Rx:0, DET_RCS_092_Rx:0, DET_SNR_089_Rx:0, DET_SNR_090_Rx:0, DET_SNR_091_Rx:0, DET_SNR_092_Rx:0, DET_SUPER_RES_TARGET_089_Rx:0, DET_SUPER_RES_TARGET_090_Rx:0, DET_SUPER_RES_TARGET_091_Rx:0, DET_SUPER_RES_TARGET_092_Rx:0]}, required-interface=Pi_SG_Fusion_Detections_089_092_AL
      Rp_SG_Fusion_Detections_093_096_AL: nonqueued-receiver-com-spec{data-element=Vdp_SG_Fusion_Detections_093_096_AL, init-value=fields=[DET_AZIMUTH_093_Rx:0, DET_AZIMUTH_094_Rx:0, DET_AZIMUTH_095_Rx:0, DET_AZIMUTH_096_Rx:0, DET_AZIMUTH_ERR_093_Rx:0, DET_AZIMUTH_ERR_094_Rx:0, DET_AZIMUTH_ERR_095_Rx:0, DET_AZIMUTH_ERR_096_Rx:0, DET_BELOW_RAIN_THOLD_093_Rx:0, DET_BELOW_RAIN_THOLD_094_Rx:0, DET_BELOW_RAIN_THOLD_095_Rx:0, DET_BELOW_RAIN_THOLD_096_Rx:0, DET_BI_STATIC_FLAG_093_Rx:0, DET_BI_STATIC_FLAG_094_Rx:0, DET_BI_STATIC_FLAG_095_Rx:0, DET_BI_STATIC_FLAG_096_Rx:0, DET_CONFD_AZIMUTH_093_Rx:0, DET_CONFD_AZIMUTH_094_Rx:0, DET_CONFD_AZIMUTH_095_Rx:0, DET_CONFD_AZIMUTH_096_Rx:0, DET_CONFD_ELEVATION_093_Rx:0, DET_CONFD_ELEVATION_094_Rx:0, DET_CONFD_ELEVATION_095_Rx:0, DET_CONFD_ELEVATION_096_Rx:0, DET_ELEVATION_093_Rx:0, DET_ELEVATION_094_Rx:0, DET_ELEVATION_095_Rx:0, DET_ELEVATION_096_Rx:0, DET_ELEVATION_ERR_093_Rx:0, DET_ELEVATION_ERR_094_Rx:0, DET_ELEVATION_ERR_095_Rx:0, DET_ELEVATION_ERR_096_Rx:0, DET_EXISTENCE_PROB_093_Rx:0, DET_EXISTENCE_PROB_094_Rx:0, DET_EXISTENCE_PROB_095_Rx:0, DET_EXISTENCE_PROB_096_Rx:0, DET_HVC_FLAG_093_Rx:0, DET_HVC_FLAG_094_Rx:0, DET_HVC_FLAG_095_Rx:0, DET_HVC_FLAG_096_Rx:0, DET_IDM_093_Rx:0, DET_IDM_094_Rx:0, DET_IDM_095_Rx:0, DET_IDM_096_Rx:0, DET_MH_CRC16_093_096_Rx:0, DET_MH_CYCLE_COUNTER_093_096_Rx:0, DET_MH_SCAN_INDEX_4LSB_093_096_Rx:0, DET_MTD_093_Rx:0, DET_MTD_094_Rx:0, DET_MTD_095_Rx:0, DET_MTD_096_Rx:0, DET_PROB_1STAZHYPO_093_Rx:0, DET_PROB_1STAZHYPO_094_Rx:0, DET_PROB_1STAZHYPO_095_Rx:0, DET_PROB_1STAZHYPO_096_Rx:0, DET_RANGE_093_Rx:0, DET_RANGE_094_Rx:0, DET_RANGE_095_Rx:0, DET_RANGE_096_Rx:0, DET_RANGE_ERR_093_Rx:0, DET_RANGE_ERR_094_Rx:0, DET_RANGE_ERR_095_Rx:0, DET_RANGE_ERR_096_Rx:0, DET_RANGE_VELOCITY_093_Rx:0, DET_RANGE_VELOCITY_094_Rx:0, DET_RANGE_VELOCITY_095_Rx:0, DET_RANGE_VELOCITY_096_Rx:0, DET_RANGE_VELOCITY_ERR_093_Rx:0, DET_RANGE_VELOCITY_ERR_094_Rx:0, DET_RANGE_VELOCITY_ERR_095_Rx:0, DET_RANGE_VELOCITY_ERR_096_Rx:0, DET_RCS_093_Rx:0, DET_RCS_094_Rx:0, DET_RCS_095_Rx:0, DET_RCS_096_Rx:0, DET_SNR_093_Rx:0, DET_SNR_094_Rx:0, DET_SNR_095_Rx:0, DET_SNR_096_Rx:0, DET_SUPER_RES_TARGET_093_Rx:0, DET_SUPER_RES_TARGET_094_Rx:0, DET_SUPER_RES_TARGET_095_Rx:0, DET_SUPER_RES_TARGET_096_Rx:0]}, required-interface=Pi_SG_Fusion_Detections_093_096_AL
      Rp_SG_Fusion_Detections_097_100_AL: nonqueued-receiver-com-spec{data-element=Vdp_SG_Fusion_Detections_097_100_AL, init-value=fields=[DET_AZIMUTH_097_Rx:0, DET_AZIMUTH_098_Rx:0, DET_AZIMUTH_099_Rx:0, DET_AZIMUTH_100_Rx:0, DET_AZIMUTH_ERR_097_Rx:0, DET_AZIMUTH_ERR_098_Rx:0, DET_AZIMUTH_ERR_099_Rx:0, DET_AZIMUTH_ERR_100_Rx:0, DET_BELOW_RAIN_THOLD_097_Rx:0, DET_BELOW_RAIN_THOLD_098_Rx:0, DET_BELOW_RAIN_THOLD_099_Rx:0, DET_BELOW_RAIN_THOLD_100_Rx:0, DET_BI_STATIC_FLAG_097_Rx:0, DET_BI_STATIC_FLAG_098_Rx:0, DET_BI_STATIC_FLAG_099_Rx:0, DET_BI_STATIC_FLAG_100_Rx:0, DET_CONFD_AZIMUTH_097_Rx:0, DET_CONFD_AZIMUTH_098_Rx:0, DET_CONFD_AZIMUTH_099_Rx:0, DET_CONFD_AZIMUTH_100_Rx:0, DET_CONFD_ELEVATION_097_Rx:0, DET_CONFD_ELEVATION_098_Rx:0, DET_CONFD_ELEVATION_099_Rx:0, DET_CONFD_ELEVATION_100_Rx:0, DET_ELEVATION_097_Rx:0, DET_ELEVATION_098_Rx:0, DET_ELEVATION_099_Rx:0, DET_ELEVATION_100_Rx:0, DET_ELEVATION_ERR_097_Rx:0, DET_ELEVATION_ERR_098_Rx:0, DET_ELEVATION_ERR_099_Rx:0, DET_ELEVATION_ERR_100_Rx:0, DET_EXISTENCE_PROB_097_Rx:0, DET_EXISTENCE_PROB_098_Rx:0, DET_EXISTENCE_PROB_099_Rx:0, DET_EXISTENCE_PROB_100_Rx:0, DET_HVC_FLAG_097_Rx:0, DET_HVC_FLAG_098_Rx:0, DET_HVC_FLAG_099_Rx:0, DET_HVC_FLAG_100_Rx:0, DET_IDM_097_Rx:0, DET_IDM_098_Rx:0, DET_IDM_099_Rx:0, DET_IDM_100_Rx:0, DET_MH_CRC16_097_100_Rx:0, DET_MH_CYCLE_COUNTER_097_100_Rx:0, DET_MH_SCAN_INDEX_4LSB_097_100_Rx:0, DET_MTD_097_Rx:0, DET_MTD_098_Rx:0, DET_MTD_099_Rx:0, DET_MTD_100_Rx:0, DET_PROB_1STAZHYPO_097_Rx:0, DET_PROB_1STAZHYPO_098_Rx:0, DET_PROB_1STAZHYPO_099_Rx:0, DET_PROB_1STAZHYPO_100_Rx:0, DET_RANGE_097_Rx:0, DET_RANGE_098_Rx:0, DET_RANGE_099_Rx:0, DET_RANGE_100_Rx:0, DET_RANGE_ERR_097_Rx:0, DET_RANGE_ERR_098_Rx:0, DET_RANGE_ERR_099_Rx:0, DET_RANGE_ERR_100_Rx:0, DET_RANGE_VELOCITY_097_Rx:0, DET_RANGE_VELOCITY_098_Rx:0, DET_RANGE_VELOCITY_099_Rx:0, DET_RANGE_VELOCITY_100_Rx:0, DET_RANGE_VELOCITY_ERR_097_Rx:0, DET_RANGE_VELOCITY_ERR_098_Rx:0, DET_RANGE_VELOCITY_ERR_099_Rx:0, DET_RANGE_VELOCITY_ERR_100_Rx:0, DET_RCS_097_Rx:0, DET_RCS_098_Rx:0, DET_RCS_099_Rx:0, DET_RCS_100_Rx:0, DET_SNR_097_Rx:0, DET_SNR_098_Rx:0, DET_SNR_099_Rx:0, DET_SNR_100_Rx:0, DET_SUPER_RES_TARGET_097_Rx:0, DET_SUPER_RES_TARGET_098_Rx:0, DET_SUPER_RES_TARGET_099_Rx:0, DET_SUPER_RES_TARGET_100_Rx:0]}, required-interface=Pi_SG_Fusion_Detections_097_100_AL
      Rp_SG_Fusion_Detections_101_104_AL: nonqueued-receiver-com-spec{data-element=Vdp_SG_Fusion_Detections_101_104_AL, init-value=fields=[DET_AZIMUTH_101_Rx:0, DET_AZIMUTH_102_Rx:0, DET_AZIMUTH_103_Rx:0, DET_AZIMUTH_104_Rx:0, DET_AZIMUTH_ERR_101_Rx:0, DET_AZIMUTH_ERR_102_Rx:0, DET_AZIMUTH_ERR_103_Rx:0, DET_AZIMUTH_ERR_104_Rx:0, DET_BELOW_RAIN_THOLD_101_Rx:0, DET_BELOW_RAIN_THOLD_102_Rx:0, DET_BELOW_RAIN_THOLD_103_Rx:0, DET_BELOW_RAIN_THOLD_104_Rx:0, DET_BI_STATIC_FLAG_101_Rx:0, DET_BI_STATIC_FLAG_102_Rx:0, DET_BI_STATIC_FLAG_103_Rx:0, DET_BI_STATIC_FLAG_104_Rx:0, DET_CONFD_AZIMUTH_101_Rx:0, DET_CONFD_AZIMUTH_102_Rx:0, DET_CONFD_AZIMUTH_103_Rx:0, DET_CONFD_AZIMUTH_104_Rx:0, DET_CONFD_ELEVATION_101_Rx:0, DET_CONFD_ELEVATION_102_Rx:0, DET_CONFD_ELEVATION_103_Rx:0, DET_CONFD_ELEVATION_104_Rx:0, DET_ELEVATION_101_Rx:0, DET_ELEVATION_102_Rx:0, DET_ELEVATION_103_Rx:0, DET_ELEVATION_104_Rx:0, DET_ELEVATION_ERR_101_Rx:0, DET_ELEVATION_ERR_102_Rx:0, DET_ELEVATION_ERR_103_Rx:0, DET_ELEVATION_ERR_104_Rx:0, DET_EXISTENCE_PROB_101_Rx:0, DET_EXISTENCE_PROB_102_Rx:0, DET_EXISTENCE_PROB_103_Rx:0, DET_EXISTENCE_PROB_104_Rx:0, DET_HVC_FLAG_101_Rx:0, DET_HVC_FLAG_102_Rx:0, DET_HVC_FLAG_103_Rx:0, DET_HVC_FLAG_104_Rx:0, DET_IDM_101_Rx:0, DET_IDM_102_Rx:0, DET_IDM_103_Rx:0, DET_IDM_104_Rx:0, DET_MH_CRC16_101_104_Rx:0, DET_MH_CYCLE_COUNTER_101_104_Rx:0, DET_MH_SCAN_INDEX_4LSB_101_104_Rx:0, DET_MTD_101_Rx:0, DET_MTD_102_Rx:0, DET_MTD_103_Rx:0, DET_MTD_104_Rx:0, DET_PROB_1STAZHYPO_101_Rx:0, DET_PROB_1STAZHYPO_102_Rx:0, DET_PROB_1STAZHYPO_103_Rx:0, DET_PROB_1STAZHYPO_104_Rx:0, DET_RANGE_101_Rx:0, DET_RANGE_102_Rx:0, DET_RANGE_103_Rx:0, DET_RANGE_104_Rx:0, DET_RANGE_ERR_101_Rx:0, DET_RANGE_ERR_102_Rx:0, DET_RANGE_ERR_103_Rx:0, DET_RANGE_ERR_104_Rx:0, DET_RANGE_VELOCITY_101_Rx:0, DET_RANGE_VELOCITY_102_Rx:0, DET_RANGE_VELOCITY_103_Rx:0, DET_RANGE_VELOCITY_104_Rx:0, DET_RANGE_VELOCITY_ERR_101_Rx:0, DET_RANGE_VELOCITY_ERR_102_Rx:0, DET_RANGE_VELOCITY_ERR_103_Rx:0, DET_RANGE_VELOCITY_ERR_104_Rx:0, DET_RCS_101_Rx:0, DET_RCS_102_Rx:0, DET_RCS_103_Rx:0, DET_RCS_104_Rx:0, DET_SNR_101_Rx:0, DET_SNR_102_Rx:0, DET_SNR_103_Rx:0, DET_SNR_104_Rx:0, DET_SUPER_RES_TARGET_101_Rx:0, DET_SUPER_RES_TARGET_102_Rx:0, DET_SUPER_RES_TARGET_103_Rx:0, DET_SUPER_RES_TARGET_104_Rx:0]}, required-interface=Pi_SG_Fusion_Detections_101_104_AL
      Rp_SG_Fusion_Detections_105_108_AL: nonqueued-receiver-com-spec{data-element=Vdp_SG_Fusion_Detections_105_108_AL, init-value=fields=[DET_AZIMUTH_105_Rx:0, DET_AZIMUTH_106_Rx:0, DET_AZIMUTH_107_Rx:0, DET_AZIMUTH_108_Rx:0, DET_AZIMUTH_ERR_105_Rx:0, DET_AZIMUTH_ERR_106_Rx:0, DET_AZIMUTH_ERR_107_Rx:0, DET_AZIMUTH_ERR_108_Rx:0, DET_BELOW_RAIN_THOLD_105_Rx:0, DET_BELOW_RAIN_THOLD_106_Rx:0, DET_BELOW_RAIN_THOLD_107_Rx:0, DET_BELOW_RAIN_THOLD_108_Rx:0, DET_BI_STATIC_FLAG_105_Rx:0, DET_BI_STATIC_FLAG_106_Rx:0, DET_BI_STATIC_FLAG_107_Rx:0, DET_BI_STATIC_FLAG_108_Rx:0, DET_CONFD_AZIMUTH_105_Rx:0, DET_CONFD_AZIMUTH_106_Rx:0, DET_CONFD_AZIMUTH_107_Rx:0, DET_CONFD_AZIMUTH_108_Rx:0, DET_CONFD_ELEVATION_105_Rx:0, DET_CONFD_ELEVATION_106_Rx:0, DET_CONFD_ELEVATION_107_Rx:0, DET_CONFD_ELEVATION_108_Rx:0, DET_ELEVATION_105_Rx:0, DET_ELEVATION_106_Rx:0, DET_ELEVATION_107_Rx:0, DET_ELEVATION_108_Rx:0, DET_ELEVATION_ERR_105_Rx:0, DET_ELEVATION_ERR_106_Rx:0, DET_ELEVATION_ERR_107_Rx:0, DET_ELEVATION_ERR_108_Rx:0, DET_EXISTENCE_PROB_105_Rx:0, DET_EXISTENCE_PROB_106_Rx:0, DET_EXISTENCE_PROB_107_Rx:0, DET_EXISTENCE_PROB_108_Rx:0, DET_HVC_FLAG_105_Rx:0, DET_HVC_FLAG_106_Rx:0, DET_HVC_FLAG_107_Rx:0, DET_HVC_FLAG_108_Rx:0, DET_IDM_105_Rx:0, DET_IDM_106_Rx:0, DET_IDM_107_Rx:0, DET_IDM_108_Rx:0, DET_MH_CRC16_105_108_Rx:0, DET_MH_CYCLE_COUNTER_105_108_Rx:0, DET_MH_SCAN_INDEX_4LSB_105_108_Rx:0, DET_MTD_105_Rx:0, DET_MTD_106_Rx:0, DET_MTD_107_Rx:0, DET_MTD_108_Rx:0, DET_PROB_1STAZHYPO_105_Rx:0, DET_PROB_1STAZHYPO_106_Rx:0, DET_PROB_1STAZHYPO_107_Rx:0, DET_PROB_1STAZHYPO_108_Rx:0, DET_RANGE_105_Rx:0, DET_RANGE_106_Rx:0, DET_RANGE_107_Rx:0, DET_RANGE_108_Rx:0, DET_RANGE_ERR_105_Rx:0, DET_RANGE_ERR_106_Rx:0, DET_RANGE_ERR_107_Rx:0, DET_RANGE_ERR_108_Rx:0, DET_RANGE_VELOCITY_105_Rx:0, DET_RANGE_VELOCITY_106_Rx:0, DET_RANGE_VELOCITY_107_Rx:0, DET_RANGE_VELOCITY_108_Rx:0, DET_RANGE_VELOCITY_ERR_105_Rx:0, DET_RANGE_VELOCITY_ERR_106_Rx:0, DET_RANGE_VELOCITY_ERR_107_Rx:0, DET_RANGE_VELOCITY_ERR_108_Rx:0, DET_RCS_105_Rx:0, DET_RCS_106_Rx:0, DET_RCS_107_Rx:0, DET_RCS_108_Rx:0, DET_SNR_105_Rx:0, DET_SNR_106_Rx:0, DET_SNR_107_Rx:0, DET_SNR_108_Rx:0, DET_SUPER_RES_TARGET_105_Rx:0, DET_SUPER_RES_TARGET_106_Rx:0, DET_SUPER_RES_TARGET_107_Rx:0, DET_SUPER_RES_TARGET_108_Rx:0]}, required-interface=Pi_SG_Fusion_Detections_105_108_AL
      Rp_SG_Fusion_Detections_109_112_AL: nonqueued-receiver-com-spec{data-element=Vdp_SG_Fusion_Detections_109_112_AL, init-value=fields=[DET_AZIMUTH_109_Rx:0, DET_AZIMUTH_110_Rx:0, DET_AZIMUTH_111_Rx:0, DET_AZIMUTH_112_Rx:0, DET_AZIMUTH_ERR_109_Rx:0, DET_AZIMUTH_ERR_110_Rx:0, DET_AZIMUTH_ERR_111_Rx:0, DET_AZIMUTH_ERR_112_Rx:0, DET_BELOW_RAIN_THOLD_109_Rx:0, DET_BELOW_RAIN_THOLD_110_Rx:0, DET_BELOW_RAIN_THOLD_111_Rx:0, DET_BELOW_RAIN_THOLD_112_Rx:0, DET_BI_STATIC_FLAG_109_Rx:0, DET_BI_STATIC_FLAG_110_Rx:0, DET_BI_STATIC_FLAG_111_Rx:0, DET_BI_STATIC_FLAG_112_Rx:0, DET_CONFD_AZIMUTH_109_Rx:0, DET_CONFD_AZIMUTH_110_Rx:0, DET_CONFD_AZIMUTH_111_Rx:0, DET_CONFD_AZIMUTH_112_Rx:0, DET_CONFD_ELEVATION_109_Rx:0, DET_CONFD_ELEVATION_110_Rx:0, DET_CONFD_ELEVATION_111_Rx:0, DET_CONFD_ELEVATION_112_Rx:0, DET_ELEVATION_109_Rx:0, DET_ELEVATION_110_Rx:0, DET_ELEVATION_111_Rx:0, DET_ELEVATION_112_Rx:0, DET_ELEVATION_ERR_109_Rx:0, DET_ELEVATION_ERR_110_Rx:0, DET_ELEVATION_ERR_111_Rx:0, DET_ELEVATION_ERR_112_Rx:0, DET_EXISTENCE_PROB_109_Rx:0, DET_EXISTENCE_PROB_110_Rx:0, DET_EXISTENCE_PROB_111_Rx:0, DET_EXISTENCE_PROB_112_Rx:0, DET_HVC_FLAG_109_Rx:0, DET_HVC_FLAG_110_Rx:0, DET_HVC_FLAG_111_Rx:0, DET_HVC_FLAG_112_Rx:0, DET_IDM_109_Rx:0, DET_IDM_110_Rx:0, DET_IDM_111_Rx:0, DET_IDM_112_Rx:0, DET_MH_CRC16_109_112_Rx:0, DET_MH_CYCLE_COUNTER_109_112_Rx:0, DET_MH_SCAN_INDEX_4LSB_109_112_Rx:0, DET_MTD_109_Rx:0, DET_MTD_110_Rx:0, DET_MTD_111_Rx:0, DET_MTD_112_Rx:0, DET_PROB_1STAZHYPO_109_Rx:0, DET_PROB_1STAZHYPO_110_Rx:0, DET_PROB_1STAZHYPO_111_Rx:0, DET_PROB_1STAZHYPO_112_Rx:0, DET_RANGE_109_Rx:0, DET_RANGE_110_Rx:0, DET_RANGE_111_Rx:0, DET_RANGE_112_Rx:0, DET_RANGE_ERR_109_Rx:0, DET_RANGE_ERR_110_Rx:0, DET_RANGE_ERR_111_Rx:0, DET_RANGE_ERR_112_Rx:0, DET_RANGE_VELOCITY_109_Rx:0, DET_RANGE_VELOCITY_110_Rx:0, DET_RANGE_VELOCITY_111_Rx:0, DET_RANGE_VELOCITY_112_Rx:0, DET_RANGE_VELOCITY_ERR_109_Rx:0, DET_RANGE_VELOCITY_ERR_110_Rx:0, DET_RANGE_VELOCITY_ERR_111_Rx:0, DET_RANGE_VELOCITY_ERR_112_Rx:0, DET_RCS_109_Rx:0, DET_RCS_110_Rx:0, DET_RCS_111_Rx:0, DET_RCS_112_Rx:0, DET_SNR_109_Rx:0, DET_SNR_110_Rx:0, DET_SNR_111_Rx:0, DET_SNR_112_Rx:0, DET_SUPER_RES_TARGET_109_Rx:0, DET_SUPER_RES_TARGET_110_Rx:0, DET_SUPER_RES_TARGET_111_Rx:0, DET_SUPER_RES_TARGET_112_Rx:0]}, required-interface=Pi_SG_Fusion_Detections_109_112_AL
      Rp_SG_Fusion_Detections_113_116_AL: nonqueued-receiver-com-spec{data-element=Vdp_SG_Fusion_Detections_113_116_AL, init-value=fields=[DET_AZIMUTH_113_Rx:0, DET_AZIMUTH_114_Rx:0, DET_AZIMUTH_115_Rx:0, DET_AZIMUTH_116_Rx:0, DET_AZIMUTH_ERR_113_Rx:0, DET_AZIMUTH_ERR_114_Rx:0, DET_AZIMUTH_ERR_115_Rx:0, DET_AZIMUTH_ERR_116_Rx:0, DET_BELOW_RAIN_THOLD_113_Rx:0, DET_BELOW_RAIN_THOLD_114_Rx:0, DET_BELOW_RAIN_THOLD_115_Rx:0, DET_BELOW_RAIN_THOLD_116_Rx:0, DET_BI_STATIC_FLAG_113_Rx:0, DET_BI_STATIC_FLAG_114_Rx:0, DET_BI_STATIC_FLAG_115_Rx:0, DET_BI_STATIC_FLAG_116_Rx:0, DET_CONFD_AZIMUTH_113_Rx:0, DET_CONFD_AZIMUTH_114_Rx:0, DET_CONFD_AZIMUTH_115_Rx:0, DET_CONFD_AZIMUTH_116_Rx:0, DET_CONFD_ELEVATION_113_Rx:0, DET_CONFD_ELEVATION_114_Rx:0, DET_CONFD_ELEVATION_115_Rx:0, DET_CONFD_ELEVATION_116_Rx:0, DET_ELEVATION_113_Rx:0, DET_ELEVATION_114_Rx:0, DET_ELEVATION_115_Rx:0, DET_ELEVATION_116_Rx:0, DET_ELEVATION_ERR_113_Rx:0, DET_ELEVATION_ERR_114_Rx:0, DET_ELEVATION_ERR_115_Rx:0, DET_ELEVATION_ERR_116_Rx:0, DET_EXISTENCE_PROB_113_Rx:0, DET_EXISTENCE_PROB_114_Rx:0, DET_EXISTENCE_PROB_115_Rx:0, DET_EXISTENCE_PROB_116_Rx:0, DET_HVC_FLAG_113_Rx:0, DET_HVC_FLAG_114_Rx:0, DET_HVC_FLAG_115_Rx:0, DET_HVC_FLAG_116_Rx:0, DET_IDM_113_Rx:0, DET_IDM_114_Rx:0, DET_IDM_115_Rx:0, DET_IDM_116_Rx:0, DET_MH_CRC16_113_116_Rx:0, DET_MH_CYCLE_COUNTER_113_116_Rx:0, DET_MH_SCAN_INDEX_4LSB_113_116_Rx:0, DET_MTD_113_Rx:0, DET_MTD_114_Rx:0, DET_MTD_115_Rx:0, DET_MTD_116_Rx:0, DET_PROB_1STAZHYPO_113_Rx:0, DET_PROB_1STAZHYPO_114_Rx:0, DET_PROB_1STAZHYPO_115_Rx:0, DET_PROB_1STAZHYPO_116_Rx:0, DET_RANGE_113_Rx:0, DET_RANGE_114_Rx:0, DET_RANGE_115_Rx:0, DET_RANGE_116_Rx:0, DET_RANGE_ERR_113_Rx:0, DET_RANGE_ERR_114_Rx:0, DET_RANGE_ERR_115_Rx:0, DET_RANGE_ERR_116_Rx:0, DET_RANGE_VELOCITY_113_Rx:0, DET_RANGE_VELOCITY_114_Rx:0, DET_RANGE_VELOCITY_115_Rx:0, DET_RANGE_VELOCITY_116_Rx:0, DET_RANGE_VELOCITY_ERR_113_Rx:0, DET_RANGE_VELOCITY_ERR_114_Rx:0, DET_RANGE_VELOCITY_ERR_115_Rx:0, DET_RANGE_VELOCITY_ERR_116_Rx:0, DET_RCS_113_Rx:0, DET_RCS_114_Rx:0, DET_RCS_115_Rx:0, DET_RCS_116_Rx:0, DET_SNR_113_Rx:0, DET_SNR_114_Rx:0, DET_SNR_115_Rx:0, DET_SNR_116_Rx:0, DET_SUPER_RES_TARGET_113_Rx:0, DET_SUPER_RES_TARGET_114_Rx:0, DET_SUPER_RES_TARGET_115_Rx:0, DET_SUPER_RES_TARGET_116_Rx:0]}, required-interface=Pi_SG_Fusion_Detections_113_116_AL
      Rp_SG_Fusion_Detections_117_120_AL: nonqueued-receiver-com-spec{data-element=Vdp_SG_Fusion_Detections_117_120_AL, init-value=fields=[DET_AZIMUTH_117_Rx:0, DET_AZIMUTH_118_Rx:0, DET_AZIMUTH_119_Rx:0, DET_AZIMUTH_120_Rx:0, DET_AZIMUTH_ERR_117_Rx:0, DET_AZIMUTH_ERR_118_Rx:0, DET_AZIMUTH_ERR_119_Rx:0, DET_AZIMUTH_ERR_120_Rx:0, DET_BELOW_RAIN_THOLD_117_Rx:0, DET_BELOW_RAIN_THOLD_118_Rx:0, DET_BELOW_RAIN_THOLD_119_Rx:0, DET_BELOW_RAIN_THOLD_120_Rx:0, DET_BI_STATIC_FLAG_117_Rx:0, DET_BI_STATIC_FLAG_118_Rx:0, DET_BI_STATIC_FLAG_119_Rx:0, DET_BI_STATIC_FLAG_120_Rx:0, DET_CONFD_AZIMUTH_117_Rx:0, DET_CONFD_AZIMUTH_118_Rx:0, DET_CONFD_AZIMUTH_119_Rx:0, DET_CONFD_AZIMUTH_120_Rx:0, DET_CONFD_ELEVATION_117_Rx:0, DET_CONFD_ELEVATION_118_Rx:0, DET_CONFD_ELEVATION_119_Rx:0, DET_CONFD_ELEVATION_120_Rx:0, DET_ELEVATION_117_Rx:0, DET_ELEVATION_118_Rx:0, DET_ELEVATION_119_Rx:0, DET_ELEVATION_120_Rx:0, DET_ELEVATION_ERR_117_Rx:0, DET_ELEVATION_ERR_118_Rx:0, DET_ELEVATION_ERR_119_Rx:0, DET_ELEVATION_ERR_120_Rx:0, DET_EXISTENCE_PROB_117_Rx:0, DET_EXISTENCE_PROB_118_Rx:0, DET_EXISTENCE_PROB_119_Rx:0, DET_EXISTENCE_PROB_120_Rx:0, DET_HVC_FLAG_117_Rx:0, DET_HVC_FLAG_118_Rx:0, DET_HVC_FLAG_119_Rx:0, DET_HVC_FLAG_120_Rx:0, DET_IDM_117_Rx:0, DET_IDM_118_Rx:0, DET_IDM_119_Rx:0, DET_IDM_120_Rx:0, DET_MH_CRC16_117_120_Rx:0, DET_MH_CYCLE_COUNTER_117_120_Rx:0, DET_MH_SCAN_INDEX_4LSB_117_120_Rx:0, DET_MTD_117_Rx:0, DET_MTD_118_Rx:0, DET_MTD_119_Rx:0, DET_MTD_120_Rx:0, DET_PROB_1STAZHYPO_117_Rx:0, DET_PROB_1STAZHYPO_118_Rx:0, DET_PROB_1STAZHYPO_119_Rx:0, DET_PROB_1STAZHYPO_120_Rx:0, DET_RANGE_117_Rx:0, DET_RANGE_118_Rx:0, DET_RANGE_119_Rx:0, DET_RANGE_120_Rx:0, DET_RANGE_ERR_117_Rx:0, DET_RANGE_ERR_118_Rx:0, DET_RANGE_ERR_119_Rx:0, DET_RANGE_ERR_120_Rx:0, DET_RANGE_VELOCITY_117_Rx:0, DET_RANGE_VELOCITY_118_Rx:0, DET_RANGE_VELOCITY_119_Rx:0, DET_RANGE_VELOCITY_120_Rx:0, DET_RANGE_VELOCITY_ERR_117_Rx:0, DET_RANGE_VELOCITY_ERR_118_Rx:0, DET_RANGE_VELOCITY_ERR_119_Rx:0, DET_RANGE_VELOCITY_ERR_120_Rx:0, DET_RCS_117_Rx:0, DET_RCS_118_Rx:0, DET_RCS_119_Rx:0, DET_RCS_120_Rx:0, DET_SNR_117_Rx:0, DET_SNR_118_Rx:0, DET_SNR_119_Rx:0, DET_SNR_120_Rx:0, DET_SUPER_RES_TARGET_117_Rx:0, DET_SUPER_RES_TARGET_118_Rx:0, DET_SUPER_RES_TARGET_119_Rx:0, DET_SUPER_RES_TARGET_120_Rx:0]}, required-interface=Pi_SG_Fusion_Detections_117_120_AL
      Rp_SG_Fusion_Detections_121_124_AL: nonqueued-receiver-com-spec{data-element=Vdp_SG_Fusion_Detections_121_124_AL, init-value=fields=[DET_AZIMUTH_121_Rx:0, DET_AZIMUTH_122_Rx:0, DET_AZIMUTH_123_Rx:0, DET_AZIMUTH_124_Rx:0, DET_AZIMUTH_ERR_121_Rx:0, DET_AZIMUTH_ERR_122_Rx:0, DET_AZIMUTH_ERR_123_Rx:0, DET_AZIMUTH_ERR_124_Rx:0, DET_BELOW_RAIN_THOLD_121_Rx:0, DET_BELOW_RAIN_THOLD_122_Rx:0, DET_BELOW_RAIN_THOLD_123_Rx:0, DET_BELOW_RAIN_THOLD_124_Rx:0, DET_BI_STATIC_FLAG_121_Rx:0, DET_BI_STATIC_FLAG_122_Rx:0, DET_BI_STATIC_FLAG_123_Rx:0, DET_BI_STATIC_FLAG_124_Rx:0, DET_CONFD_AZIMUTH_121_Rx:0, DET_CONFD_AZIMUTH_122_Rx:0, DET_CONFD_AZIMUTH_123_Rx:0, DET_CONFD_AZIMUTH_124_Rx:0, DET_CONFD_ELEVATION_121_Rx:0, DET_CONFD_ELEVATION_122_Rx:0, DET_CONFD_ELEVATION_123_Rx:0, DET_CONFD_ELEVATION_124_Rx:0, DET_ELEVATION_121_Rx:0, DET_ELEVATION_122_Rx:0, DET_ELEVATION_123_Rx:0, DET_ELEVATION_124_Rx:0, DET_ELEVATION_ERR_121_Rx:0, DET_ELEVATION_ERR_122_Rx:0, DET_ELEVATION_ERR_123_Rx:0, DET_ELEVATION_ERR_124_Rx:0, DET_EXISTENCE_PROB_121_Rx:0, DET_EXISTENCE_PROB_122_Rx:0, DET_EXISTENCE_PROB_123_Rx:0, DET_EXISTENCE_PROB_124_Rx:0, DET_HVC_FLAG_121_Rx:0, DET_HVC_FLAG_122_Rx:0, DET_HVC_FLAG_123_Rx:0, DET_HVC_FLAG_124_Rx:0, DET_IDM_121_Rx:0, DET_IDM_122_Rx:0, DET_IDM_123_Rx:0, DET_IDM_124_Rx:0, DET_MH_CRC16_121_124_Rx:0, DET_MH_CYCLE_COUNTER_121_124_Rx:0, DET_MH_SCAN_INDEX_4LSB_121_124_Rx:0, DET_MTD_121_Rx:0, DET_MTD_122_Rx:0, DET_MTD_123_Rx:0, DET_MTD_124_Rx:0, DET_PROB_1STAZHYPO_121_Rx:0, DET_PROB_1STAZHYPO_122_Rx:0, DET_PROB_1STAZHYPO_123_Rx:0, DET_PROB_1STAZHYPO_124_Rx:0, DET_RANGE_121_Rx:0, DET_RANGE_122_Rx:0, DET_RANGE_123_Rx:0, DET_RANGE_124_Rx:0, DET_RANGE_ERR_121_Rx:0, DET_RANGE_ERR_122_Rx:0, DET_RANGE_ERR_123_Rx:0, DET_RANGE_ERR_124_Rx:0, DET_RANGE_VELOCITY_121_Rx:0, DET_RANGE_VELOCITY_122_Rx:0, DET_RANGE_VELOCITY_123_Rx:0, DET_RANGE_VELOCITY_124_Rx:0, DET_RANGE_VELOCITY_ERR_121_Rx:0, DET_RANGE_VELOCITY_ERR_122_Rx:0, DET_RANGE_VELOCITY_ERR_123_Rx:0, DET_RANGE_VELOCITY_ERR_124_Rx:0, DET_RCS_121_Rx:0, DET_RCS_122_Rx:0, DET_RCS_123_Rx:0, DET_RCS_124_Rx:0, DET_SNR_121_Rx:0, DET_SNR_122_Rx:0, DET_SNR_123_Rx:0, DET_SNR_124_Rx:0, DET_SUPER_RES_TARGET_121_Rx:0, DET_SUPER_RES_TARGET_122_Rx:0, DET_SUPER_RES_TARGET_123_Rx:0, DET_SUPER_RES_TARGET_124_Rx:0]}, required-interface=Pi_SG_Fusion_Detections_121_124_AL
      Rp_SG_Fusion_Detections_125_128_AL: nonqueued-receiver-com-spec{data-element=Vdp_SG_Fusion_Detections_125_128_AL, init-value=fields=[DET_AZIMUTH_125_Rx:0, DET_AZIMUTH_126_Rx:0, DET_AZIMUTH_127_Rx:0, DET_AZIMUTH_128_Rx:0, DET_AZIMUTH_ERR_125_Rx:0, DET_AZIMUTH_ERR_126_Rx:0, DET_AZIMUTH_ERR_127_Rx:0, DET_AZIMUTH_ERR_128_Rx:0, DET_BELOW_RAIN_THOLD_125_Rx:0, DET_BELOW_RAIN_THOLD_126_Rx:0, DET_BELOW_RAIN_THOLD_127_Rx:0, DET_BELOW_RAIN_THOLD_128_Rx:0, DET_BI_STATIC_FLAG_125_Rx:0, DET_BI_STATIC_FLAG_126_Rx:0, DET_BI_STATIC_FLAG_127_Rx:0, DET_BI_STATIC_FLAG_128_Rx:0, DET_CONFD_AZIMUTH_125_Rx:0, DET_CONFD_AZIMUTH_126_Rx:0, DET_CONFD_AZIMUTH_127_Rx:0, DET_CONFD_AZIMUTH_128_Rx:0, DET_CONFD_ELEVATION_125_Rx:0, DET_CONFD_ELEVATION_126_Rx:0, DET_CONFD_ELEVATION_127_Rx:0, DET_CONFD_ELEVATION_128_Rx:0, DET_ELEVATION_125_Rx:0, DET_ELEVATION_126_Rx:0, DET_ELEVATION_127_Rx:0, DET_ELEVATION_128_Rx:0, DET_ELEVATION_ERR_125_Rx:0, DET_ELEVATION_ERR_126_Rx:0, DET_ELEVATION_ERR_127_Rx:0, DET_ELEVATION_ERR_128_Rx:0, DET_EXISTENCE_PROB_125_Rx:0, DET_EXISTENCE_PROB_126_Rx:0, DET_EXISTENCE_PROB_127_Rx:0, DET_EXISTENCE_PROB_128_Rx:0, DET_HVC_FLAG_125_Rx:0, DET_HVC_FLAG_126_Rx:0, DET_HVC_FLAG_127_Rx:0, DET_HVC_FLAG_128_Rx:0, DET_IDM_125_Rx:0, DET_IDM_126_Rx:0, DET_IDM_127_Rx:0, DET_IDM_128_Rx:0, DET_MH_CRC16_125_128_Rx:0, DET_MH_CYCLE_COUNTER_125_128_Rx:0, DET_MH_SCAN_INDEX_4LSB_125_128_Rx:0, DET_MTD_125_Rx:0, DET_MTD_126_Rx:0, DET_MTD_127_Rx:0, DET_MTD_128_Rx:0, DET_PROB_1STAZHYPO_125_Rx:0, DET_PROB_1STAZHYPO_126_Rx:0, DET_PROB_1STAZHYPO_127_Rx:0, DET_PROB_1STAZHYPO_128_Rx:0, DET_RANGE_125_Rx:0, DET_RANGE_126_Rx:0, DET_RANGE_127_Rx:0, DET_RANGE_128_Rx:0, DET_RANGE_ERR_125_Rx:0, DET_RANGE_ERR_126_Rx:0, DET_RANGE_ERR_127_Rx:0, DET_RANGE_ERR_128_Rx:0, DET_RANGE_VELOCITY_125_Rx:0, DET_RANGE_VELOCITY_126_Rx:0, DET_RANGE_VELOCITY_127_Rx:0, DET_RANGE_VELOCITY_128_Rx:0, DET_RANGE_VELOCITY_ERR_125_Rx:0, DET_RANGE_VELOCITY_ERR_126_Rx:0, DET_RANGE_VELOCITY_ERR_127_Rx:0, DET_RANGE_VELOCITY_ERR_128_Rx:0, DET_RCS_125_Rx:0, DET_RCS_126_Rx:0, DET_RCS_127_Rx:0, DET_RCS_128_Rx:0, DET_SNR_125_Rx:0, DET_SNR_126_Rx:0, DET_SNR_127_Rx:0, DET_SNR_128_Rx:0, DET_SUPER_RES_TARGET_125_Rx:0, DET_SUPER_RES_TARGET_126_Rx:0, DET_SUPER_RES_TARGET_127_Rx:0, DET_SUPER_RES_TARGET_128_Rx:0]}, required-interface=Pi_SG_Fusion_Detections_125_128_AL
    provide port Pp_SG_RadarCapability_AL: nonqueued-sender-com-spec{data-element=Vdp_SG_RadarCapability_AL, init-value=fields=[CAP_AngleAzimuthRangeEnd:0, CAP_AngleAzimuthRangeStart:0, CAP_BlockageActive:1, CAP_BlockageProbability:0, CAP_BlockageSensitivity:2, CAP_BlockageStatus:3, CAP_BlockageValue:5, CAP_CYCLE_COUNTER:0, CAP_DampingActive:0, CAP_DampingCurrent:25500, CAP_DampingStandardDeviation:0, CAP_DampingStatus:3, CAP_FreeSightCheckActive:1, CAP_FreeSightCheckStatus:255, CAP_MaxDetectionRangeCar_0:0, CAP_MaxDetectionRangeCar_1:0, CAP_MaxDetectionRangeCar_2:0, CAP_MaxDetRangeMotorbike_0:0, CAP_MaxDetRangeMotorbike_1:0, CAP_MaxDetRangeMotorbike_2:0, CAP_MaxDetRangePedestrian_0:0, CAP_MaxDetRangePedestrian_1:0, CAP_MaxDetRangePedestrian_2:0, CAP_MH_CRC16:0, CAP_RangeEstimationActive:1, CAP_RangeEstimationStatus:3, CAP_SideLobeLevelBeamformer:0, CAP_SLBlockageFilterValue:0, CAP_SLBlockageFlag:0, CAP_SLLMonitoringActive:1, CAP_SLLMonitoringStatus:3]}, provided-interface=Pi_SG_RadarCapability_AL
    provide port Pp_SG_RadarStatus2_AL: nonqueued-sender-com-spec{data-element=Vdp_SG_RadarStatus2_AL, init-value=fields=[STS_AF_CORE_THROUGHPUT:0, STS_BRR_STATUS:0, STS_CAN_NM_State:0, STS_CORE_ACTV_FLT_BYTE_0_to_3:0, STS_CORE_ACTV_FLT_BYTE_4_to_7:0, STS_CORE_ACTV_FLT_BYTE_8_to_11:0, STS_CORE_ACTV_FLT_BYTE_11_to_15:0, STS_First_CAN_Det_Inst_Latency:0, STS_Gear_Position:0, STS_INTRFC_VERSION_ID_MAJOR:0, STS_INTRFC_VERSION_ID_MINOR:0, STS_INTRFC_VERSION_ID_PATCH:0, STS_Last_CAN_Det_Inst_Latency:0, STS_MCU_TEMP:0, STS_MH_002_CRC16:0, STS_MH_002_CYCLE_COUNTER:0, 0, STS_MMIC_TEMP_RX:0, STS_MMIC_TEMP_TX0:0, STS_MMIC_TEMP_TX1_2:0, STS_MMIC_TEMP_TX3_4:0, STS_NO_TSYN_ERROR:0, STS_POINT_OF_TRIGGER:0, STS_RAIN_COUNT:0, STS_RDD_CORE_THROUGHPUT:0, STS_SCAN_TYPE:0, STS_STEERING_ANGLE:0, STS_STEERING_ANGLE_SIGN:0, STS_TIME_SYNC_OFFSET:0, STS_TKEY_ACTV_FLT_BYTE_0_to_3:0, STS_TKEY_ACTV_FLT_BYTE_4_to_5:0, STS_VEH_SPEED_DIRECTION:0, STS_VEHICLE_SPEED_CALC:0, STS_Vehicle_Speed_Calc_QF:0, STS_VEHICLE_SUPPLY_VOLTAGE:0, STS_XCVR_OPERATIONAL:0, STS_YAW_RATE_BIAS:0, STS_Yaw_Rate_Calc_QF:0]}, provided-interface=Pi_SG_RadarStatus2_AL
    require port Rp_SG_VehicleStatus_AL: nonqueued-receiver-com-spec{data-element=Vdp_SG_VehicleStatus_AL, init-value=fields=[SSTS_CAN_PCAN_MAJOR_ADAS:0, SSTS_CAN_PCAN_MINOR_ADAS:0, SSTS_DRIVE_DIR:0, SSTS_DRIVE_REVERSE:0, SSTS_GEAR_POSITION:0, SSTS_IGN_STATUS:0, SSTS_MH_VS_CRC16:0, SSTS_MH_VS_CYCLE_COUNTER:0, SSTS_STEERING_ANGLE:0, SSTS_STEERING_ANGLE_SIGN:0, SSTS_SW_VERSION_ADAS:0, SSTS_VEH_AbsoluteTime_Day:1, SSTS_VEH_AbsoluteTime_Hour:0, SSTS_VEH_AbsoluteTime_Minute:0, SSTS_VEH_AbsoluteTime_Month:1, SSTS_VEH_AbsoluteTime_Second:0, SSTS_VEH_AbsoluteTime_Year:0, SSTS_VEH_ODOMETER:5 x 0, SSTS_VEH_POWER_MODE_STATUS:7 x 0, SSTS_VEH_SPD_COMP_FACTOR:0, SSTS_VEH_Status_CMAC:5 x 0, SSTS_VEH_Status_FV:7 x 0, SSTS_VEH_SYSTEM_VOLTAGE:0, SSTS_VEH_TRAILER_CONNECTED:0, SSTS_VEH_VARIANT:0, SSTS_VEHICLE_SPEED_CALC:0, SSTS_VEHICLE_SPEED_CALC_QF:0, SSTS_VEHICLE_STATE:0, SSTS_VIN_Data_Byte0:0, SSTS_VIN_Data_Byte1:0, SSTS_VIN_Data_Byte2:0, SSTS_VIN_Data_Byte3:0, SSTS_VIN_Data_Byte4:0, SSTS_VIN_Data_Byte5:0, SSTS_VIN_Data_Byte6:0, SSTS_VIN_FrameIdx:0, SSTS_YAW_RATE_BIAS:0, SSTS_YAW_RATE_CALC:448, SSTS_YAW_RATE_CALC_QF:0]}, required-interface=Pi_SG_VehicleStatus_AL
    require port Rp_SG_XcpCTOReq_AL: nonqueued-receiver-com-spec{data-element=Vdp_SG_XcpCTOReq_AL, init-value=fields=[STS_PID:0, STS_XCP_REQ_CTO_Byte1:0, STS_XCP_REQ_CTO_Byte2:0, STS_XCP_REQ_CTO_Byte3:0, STS_XCP_REQ_CTO_Byte4:0, STS_XCP_REQ_CTO_Byte5:0, STS_XCP_REQ_CTO_Byte6:0, STS_XCP_REQ_CTO_Byte7:0, STS_XCP_REQ_CTO_Byte8:0, STS_XCP_REQ_CTO_Byte9:0, STS_XCP_REQ_CTO_Byte10:0, STS_XCP_REQ_CTO_Byte11:0, STS_XCP_REQ_CTO_Byte12:0, STS_XCP_REQ_CTO_Byte13:0, STS_XCP_REQ_CTO_Byte14:0, STS_XCP_REQ_CTO_Byte15:0, STS_XCP_REQ_CTO_Byte16:0, STS_XCP_REQ_CTO_Byte17:0, STS_XCP_REQ_CTO_Byte18:0, STS_XCP_REQ_CTO_Byte19:0, STS_XCP_REQ_CTO_Byte20:0, STS_XCP_REQ_CTO_Byte21:0, STS_XCP_REQ_CTO_Byte22:0, STS_XCP_REQ_CTO_Byte23:0, STS_XCP_REQ_CTO_Byte24:0, STS_XCP_REQ_CTO_Byte25:0, STS_XCP_REQ_CTO_Byte26:0, STS_XCP_REQ_CTO_Byte27:0, STS_XCP_REQ_CTO_Byte28:0, STS_XCP_REQ_CTO_Byte29:0, STS_XCP_REQ_CTO_Byte30:0, STS_XCP_REQ_CTO_Byte31:0, STS_XCP_REQ_CTO_Byte32:0, STS_XCP_REQ_CTO_Byte33:0, STS_XCP_REQ_CTO_Byte34:0, STS_XCP_REQ_CTO_Byte35:0, STS_XCP_REQ_CTO_Byte36:0, STS_XCP_REQ_CTO_Byte37:0, STS_XCP_REQ_CTO_Byte38:0, STS_XCP_REQ_CTO_Byte39:0, STS_XCP_REQ_CTO_Byte40:0, STS_XCP_REQ_CTO_Byte41:0, STS_XCP_REQ_CTO_Byte42:0, STS_XCP_REQ_CTO_Byte43:0, STS_XCP_REQ_CTO_Byte44:0, STS_XCP_REQ_CTO_Byte45:0, STS_XCP_REQ_CTO_Byte46:0, STS_XCP_REQ_CTO_Byte47:0, STS_XCP_REQ_CTO_Byte48:0, STS_XCP_REQ_CTO_Byte49:0, STS_XCP_REQ_CTO_Byte50:0, STS_XCP_REQ_CTO_Byte51:0, STS_XCP_REQ_CTO_Byte52:0, STS_XCP_REQ_CTO_Byte53:0, STS_XCP_REQ_CTO_Byte54:0, STS_XCP_REQ_CTO_Byte55:0, STS_XCP_REQ_CTO_Byte56:0, STS_XCP_REQ_CTO_Byte57:0, STS_XCP_REQ_CTO_Byte58:0, STS_XCP_REQ_CTO_Byte59:0, STS_XCP_REQ_CTO_Byte60:0, STS_XCP_REQ_CTO_Byte61:0, STS_XCP_REQ_CTO_Byte62:0, STS_XCP_REQ_CTO_Byte63:0]}, required-interface=Pi_SG_XcpCTOReq_AL
    provide port Pp_SG_XcpCTOResp_AL: nonqueued-sender-com-spec{data-element=Vdp_SG_XcpCTOResp_AL, init-value=fields=[STS_XCP_RES_CTO_Byte0:0, STS_XCP_RES_CTO_Byte1:0, STS_XCP_RES_CTO_Byte2:0, STS_XCP_RES_CTO_Byte3:0, STS_XCP_RES_CTO_Byte4:0, STS_XCP_RES_CTO_Byte5:0, STS_XCP_RES_CTO_Byte6:0, STS_XCP_RES_CTO_Byte7:0, STS_XCP_RES_CTO_Byte8:0, STS_XCP_RES_CTO_Byte9:0, STS_XCP_RES_CTO_Byte10:0, STS_XCP_RES_CTO_Byte11:0, STS_XCP_RES_CTO_Byte12:0, STS_XCP_RES_CTO_Byte13:0, STS_XCP_RES_CTO_Byte14:0, STS_XCP_RES_CTO_Byte15:0, STS_XCP_RES_CTO_Byte16:0, STS_XCP_RES_CTO_Byte17:0, STS_XCP_RES_CTO_Byte18:0, STS_XCP_RES_CTO_Byte19:0, STS_XCP_RES_CTO_Byte20:0, STS_XCP_RES_CTO_Byte21:0, STS_XCP_RES_CTO_Byte22:0, STS_XCP_RES_CTO_Byte23:0, STS_XCP_RES_CTO_Byte24:0, STS_XCP_RES_CTO_Byte25:0, STS_XCP_RES_CTO_Byte26:0, STS_XCP_RES_CTO_Byte27:0, STS_XCP_RES_CTO_Byte28:0, STS_XCP_RES_CTO_Byte29:0, STS_XCP_RES_CTO_Byte30:0, STS_XCP_RES_CTO_Byte31:0, STS_XCP_RES_CTO_Byte32:0, STS_XCP_RES_CTO_Byte33:0, STS_XCP_RES_CTO_Byte34:0, STS_XCP_RES_CTO_Byte35:0, STS_XCP_RES_CTO_Byte36:0, STS_XCP_RES_CTO_Byte37:0, STS_XCP_RES_CTO_Byte38:0, STS_XCP_RES_CTO_Byte39:0, STS_XCP_RES_CTO_Byte40:0, STS_XCP_RES_CTO_Byte41:0, STS_XCP_RES_CTO_Byte42:0, STS_XCP_RES_CTO_Byte43:0, STS_XCP_RES_CTO_Byte44:0, STS_XCP_RES_CTO_Byte45:0, STS_XCP_RES_CTO_Byte46:0, STS_XCP_RES_CTO_Byte47:0, STS_XCP_RES_CTO_Byte48:0, STS_XCP_RES_CTO_Byte49:0, STS_XCP_RES_CTO_Byte50:0, STS_XCP_RES_CTO_Byte51:0, STS_XCP_RES_CTO_Byte52:0, STS_XCP_RES_CTO_Byte53:0, STS_XCP_RES_CTO_Byte54:0, STS_XCP_RES_CTO_Byte55:0, STS_XCP_RES_CTO_Byte56:0, STS_XCP_RES_CTO_Byte57:0, STS_XCP_RES_CTO_Byte58:0, STS_XCP_RES_CTO_Byte59:0, STS_XCP_RES_CTO_Byte60:0, STS_XCP_RES_CTO_Byte61:0, STS_XCP_RES_CTO_Byte62:0, STS_XCP_RES_CTO_Byte63:0]}, provided-interface=Pi_SG_XcpCTOResp_AL
    provide port Pp_SG_XcpDAQResp_AL: nonqueued-sender-com-spec{data-element=Vdp_SG_XcpDAQResp_AL, init-value=fields=[STS_XCP_RES_DAQ_Byte0:0, STS_XCP_RES_DAQ_Byte1:0, STS_XCP_RES_DAQ_Byte2:0, STS_XCP_RES_DAQ_Byte3:0, STS_XCP_RES_DAQ_Byte4:0, STS_XCP_RES_DAQ_Byte5:0, STS_XCP_RES_DAQ_Byte6:0, STS_XCP_RES_DAQ_Byte7:0, STS_XCP_RES_DAQ_Byte8:0, STS_XCP_RES_DAQ_Byte9:0, STS_XCP_RES_DAQ_Byte10:0, STS_XCP_RES_DAQ_Byte11:0, STS_XCP_RES_DAQ_Byte12:0, STS_XCP_RES_DAQ_Byte13:0, STS_XCP_RES_DAQ_Byte14:0, STS_XCP_RES_DAQ_Byte15:0, STS_XCP_RES_DAQ_Byte16:0, STS_XCP_RES_DAQ_Byte17:0, STS_XCP_RES_DAQ_Byte18:0, STS_XCP_RES_DAQ_Byte19:0, STS_XCP_RES_DAQ_Byte20:0, STS_XCP_RES_DAQ_Byte21:0, STS_XCP_RES_DAQ_Byte22:0, STS_XCP_RES_DAQ_Byte23:0, STS_XCP_RES_DAQ_Byte24:0, STS_XCP_RES_DAQ_Byte25:0, STS_XCP_RES_DAQ_Byte26:0, STS_XCP_RES_DAQ_Byte27:0, STS_XCP_RES_DAQ_Byte28:0, STS_XCP_RES_DAQ_Byte29:0, STS_XCP_RES_DAQ_Byte30:0, STS_XCP_RES_DAQ_Byte31:0, STS_XCP_RES_DAQ_Byte32:0, STS_XCP_RES_DAQ_Byte33:0, STS_XCP_RES_DAQ_Byte34:0, STS_XCP_RES_DAQ_Byte35:0, STS_XCP_RES_DAQ_Byte36:0, STS_XCP_RES_DAQ_Byte37:0, STS_XCP_RES_DAQ_Byte38:0, STS_XCP_RES_DAQ_Byte39:0, STS_XCP_RES_DAQ_Byte40:0, STS_XCP_RES_DAQ_Byte41:0, STS_XCP_RES_DAQ_Byte42:0, STS_XCP_RES_DAQ_Byte43:0, STS_XCP_RES_DAQ_Byte44:0, STS_XCP_RES_DAQ_Byte45:0, STS_XCP_RES_DAQ_Byte46:0, STS_XCP_RES_DAQ_Byte47:0, STS_XCP_RES_DAQ_Byte48:0, STS_XCP_RES_DAQ_Byte49:0, STS_XCP_RES_DAQ_Byte50:0, STS_XCP_RES_DAQ_Byte51:0, STS_XCP_RES_DAQ_Byte52:0, STS_XCP_RES_DAQ_Byte53:0, STS_XCP_RES_DAQ_Byte54:0, STS_XCP_RES_DAQ_Byte55:0, STS_XCP_RES_DAQ_Byte56:0, STS_XCP_RES_DAQ_Byte57:0, STS_XCP_RES_DAQ_Byte58:0, STS_XCP_RES_DAQ_Byte59:0, STS_XCP_RES_DAQ_Byte60:0, STS_XCP_RES_DAQ_Byte61:0, STS_XCP_RES_DAQ_Byte62:0, STS_XCP_RES_DAQ_Byte63:0]}, provided-interface=Pi_SG_XcpDAQResp_AL
    provide port Pp_ECC_Correctable_Fault: nonqueued-sender-com-spec{data-element=De_ECC_Correctable_Fault, init-value=fields=[aa_mem_sec:0, artie_mem_sec:0, csi2_sec:0, dsp_opif_sec:0, dsp_idma_sec:0, dsp_iram_sec_axis:0, dsp_dcache_sec:0, dsp_dram_sec:0, dsp_icache_sec:0, dsp_iram_sec:0, ra_cqmem_sec:0, ra_dpmem_sec:0, ra_estmem_sec:0, ra_idxmem_sec:0, ra_phmem_sec:0, ra_wcmem_sec:0, sp_axi_m_corr:0, sp_axi_s_corr:0, sysmem0_sec:0, sysmem1_sec:0, not_recorded:0]}, provided-interface=Pi_ECC_Correctable_Fault
    require port Rp_ECC_Correctable_Fault: nonqueued-receiver-com-spec{data-element=De_ECC_Correctable_Fault, filter=data-filter-type=ALWAYS, init-value=fields=[aa_mem_sec:0, artie_mem_sec:0, csi2_sec:0, dsp_opif_sec:0, dsp_idma_sec:0, dsp_iram_sec_axis:0, dsp_dcache_sec:0, dsp_dram_sec:0, dsp_icache_sec:0, dsp_iram_sec:0, ra_cqmem_sec:0, ra_dpmem_sec:0, ra_estmem_sec:0, ra_idxmem_sec:0, ra_phmem_sec:0, ra_wcmem_sec:0, sp_axi_m_corr:0, sp_axi_s_corr:0, sysmem0_sec:0, sysmem1_sec:0, not_recorded:0]}, required-interface=Pi_ECC_Correctable_Fault
    provide port Pp_Pmic_Mcu_Com_Fault: nonqueued-sender-com-spec{data-element=De_Pmic_Mcu_Com_Fault, init-value=0}, provided-interface=Pi_Pmic_Mcu_Com_Fault
    29 x require port:
      Rp_ActiveMode_AL: nonqueued-receiver-com-spec{data-element=Vdp_ActiveMode_AL, init-value=0}, required-interface=Pi_ActiveMode_AL
      Rp_SG_ADAS_FN_Enable_disable_sts_ALVCAN: nonqueued-receiver-com-spec{data-element=Vdp_SG_ADAS_FN_Enable_disable_sts_ALVCAN, init-value=fields=[BSIS_Fn_Switch_Sts:0, MessageAliveCounter:0, MessageCRC:0, MOIS_Fn_Switch_sts:0]}, required-interface=Pi_SG_ADAS_FN_Enable_disable_sts_ALVCAN
      Rp_SG_CCVS1_ALVCAN: nonqueued-receiver-com-spec{data-element=Vdp_SG_CCVS1_ALVCAN, init-value=fields=[BrakeSwitch:0, ParkingBrakeSwitch:0, WheelBasedVehicleSpeed:0]}, required-interface=Pi_SG_CCVS1_ALVCAN
      Rp_SG_CLS_Tx_16_ALVCAN: nonqueued-receiver-com-spec{data-element=Vdp_SG_CLS_Tx_16_ALVCAN, init-value=fields=[Crawler_confi_status_info:0, Transmission_type_info:0]}, required-interface=Pi_SG_CLS_Tx_16_ALVCAN
      Rp_SG_CLS_Tx_4_ALVCAN: nonqueued-receiver-com-spec{data-element=Vdp_SG_CLS_Tx_4_ALVCAN, init-value=fields=[Ignition:0, ReverseSwitchInfo:0]}, required-interface=Pi_SG_CLS_Tx_4_ALVCAN
      Rp_SG_ETC2_00_ALVCAN: nonqueued-receiver-com-spec{data-element=Vdp_SG_ETC2_00_ALVCAN, init-value=fields=TransCurrentGear_00:125}, required-interface=Pi_SG_ETC2_00_ALVCAN
      Rp_SG_ETC2_03_ALVCAN: nonqueued-receiver-com-spec{data-element=Vdp_SG_ETC2_03_ALVCAN, init-value=fields=TransCurrentGear_03:0}, required-interface=Pi_SG_ETC2_03_ALVCAN
      Rp_SG_OEL_ALVCAN: nonqueued-receiver-com-spec{data-element=Vdp_SG_OEL_ALVCAN, init-value=fields=[HazardLightSwitch:0, HighLowBeamSwitch:0, TurnSignalSwitch:0]}, required-interface=Pi_SG_OEL_ALVCAN
      Rp_SG_SAS_ALVCAN: nonqueued-receiver-com-spec{data-element=Vdp_SG_SAS_ALVCAN, init-value=fields=[ActiveMode:0, Calibrated:0, MessageChecksum:0, MessageCounter:0, SteeringWheelAngle:0, SteeringWheelAngleRange:0, SteeringWheelAngleRangeCounter:0, SteeringWheelAngleRangeCounterType:0]}, required-interface=Pi_SG_SAS_ALVCAN
      Rp_SG_TD_ALVCAN: nonqueued-receiver-com-spec{data-element=Vdp_SG_TD_ALVCAN, init-value=fields=[Day:0, Hours:0, LocalHourOffset:125, LocalMinuteOffset:125, Minutes:0, Month:0, Seconds:0, Year:0]}, required-interface=Pi_SG_TD_ALVCAN
      Rp_SG_VD_ALVCAN: nonqueued-receiver-com-spec{data-element=Vdp_SG_VD_ALVCAN, init-value=fields=Total_vehicle_distance:0}, required-interface=Pi_SG_VD_ALVCAN
      Rp_SG_VDC2_ALVCAN: nonqueued-receiver-com-spec{data-element=Vdp_SG_VDC2_ALVCAN, init-value=fields=[LateralAcceleration:32127, LongitudinalAcceleration:125, SteerWheelAngle:32127, YawRate:32113]}, required-interface=Pi_SG_VDC2_ALVCAN
      Rp_SG_VI_ALVCAN: nonqueued-receiver-com-spec{data-element=Vdp_SG_VI_ALVCAN, init-value=fields=VehicleIdentification:0}, required-interface=Pi_SG_VI_ALVCAN
      Rp_SG_Fusion_AlignmentStatus1_ALPCAN: nonqueued-receiver-com-spec{data-element=Vdp_SG_Fusion_AlignmentStatus1_ALPCAN, init-value=fields=[AL_STS_001_CYCLE_COUNTER_Rx:0, AL_STS_001_MH_CRC16_Rx:0, STS_AAAzimuthStd_Rx:0, STS_AACurrentAzimuth_Rx:0, STS_AACurrentElevation_Rx:0, STS_AACurrentRoll_Rx:0, STS_AAElevationStd_Rx:0, STS_AARoll_Std_Rx:0, STS_AlignmentAutoStatus_Rx:0, STS_AlignmentAzimuth_Rx:0, STS_AlignmentElevation_Rx:0, STS_AlignmentError_Rx:0, STS_AlignmentModeIn_Rx:0, STS_AlignmentModeOut_Rx:0, STS_AutoAlignmentFailRootCause_Rx:0, STS_AzimuthErrorNegative_Rx:0, STS_AzimuthErrorPositive_Rx:0, STS_AzimuthStd_Rx:0, STS_AzimuthUpdates_Rx:0, STS_CalDisplay_Rx:0, STS_CalTime_Rx:0, STS_CoordinateSystemInput_Rx:0, STS_ElevationErrorNegative_Rx:0, STS_ElevationErrorPositive_Rx:0, STS_ElevationStd_Rx:0, STS_ElevationUpdates_Rx:0, STS_HostSpdCompensationFactorQF_Rx:0, STS_HostSpeedCompensationFactor_Rx:0, 0, 0, 0, 0, 0, 0, STS_ProgressPercent_Rx:0, STS_RadarTypeInput_Rx:0, STS_Roll_Updates_Rx:0, STS_RollErrorNegative_Rx:0, STS_RollErrorPositive_Rx:0, STS_StartAzimuth_Rx:0, STS_StartElevation_Rx:0, STS_StartRoll_Rx:0]}, required-interface=Pi_SG_Fusion_AlignmentStatus1_ALPCAN
      Rp_SG_Fusion_AlignmentStatus2_ALPCAN: nonqueued-receiver-com-spec{data-element=Vdp_SG_Fusion_AlignmentStatus2_ALPCAN, init-value=fields=[AL_STS_002_CYCLE_COUNTER_Rx:0, AL_STS_002_MH_CRC16_Rx:0, STS_AlignmentServiceStatus_Rx:0, STS_AlignmentShortTrackStatus_Rx:0, STS_AlignmentStaticStatus_Rx:0, STS_AverageNumberOfDetections_Rx:0, STS_AverageSpeed_Rx:0, STS_DistanceAbsolute_Rx:0, STS_DistanceEffective_Rx:0, STS_DurationAbsolute_Rx:0, STS_DurationEffective_Rx:0, STS_ImpactByInterference_Rx:0, STS_Measured_Range_Rx:0, STS_MeasuredAmpSTD_Rx:0, STS_MeasuredRangeRate_Rx:0, STS_MeasuredRangeRateStd_Rx:0, STS_MeasuredRangeStd_Rx:0, STS_MeasuredRawAmplitude_Rx:0, STS_VehicleCondition_Rx:0]}, required-interface=Pi_SG_Fusion_AlignmentStatus2_ALPCAN
      Rp_SG_Fusion_RadarCapability_ALPCAN: nonqueued-receiver-com-spec{data-element=Vdp_SG_Fusion_RadarCapability_ALPCAN, init-value=fields=[CAP_AngleAzimuthRangeEnd_Rx:0, CAP_AngleAzimuthRangeStart_Rx:0, CAP_BlockageActive_Rx:0, CAP_BlockageProbability_Rx:0, CAP_BlockageSensitivity_Rx:0, CAP_BlockageStatus_Rx:0, CAP_BlockageValue_Rx:0, CAP_CYCLE_COUNTER_Rx:0, CAP_DampingActive_Rx:0, CAP_DampingCurrent_Rx:0, CAP_DampingStandardDeviation_Rx:0, CAP_DampingStatus_Rx:0, CAP_FreeSightCheckActive_Rx:0, CAP_FreeSightCheckStatus_Rx:0, CAP_MaxDetectionRangeCar_0_Rx:0, CAP_MaxDetectionRangeCar_1_Rx:0, CAP_MaxDetectionRangeCar_2_Rx:0, CAP_MaxDetRangeMotorbike_0_Rx:0, CAP_MaxDetRangeMotorbike_1_Rx:0, CAP_MaxDetRangeMotorbike_2_Rx:0, CAP_MaxDetRangePedestrian_0_Rx:0, CAP_MaxDetRangePedestrian_1_Rx:0, CAP_MaxDetRangePedestrian_2_Rx:0, CAP_MH_CRC16_Rx:0, CAP_RangeEstimationActive_Rx:0, CAP_RangeEstimationStatus_Rx:0, CAP_SideLobeLevelBeamformer_Rx:0, CAP_SLBlockageFilterValue_Rx:0, CAP_SLBlockageFlag_Rx:0, CAP_SLLMonitoringActive_Rx:0, CAP_SLLMonitoringStatus_Rx:0]}, required-interface=Pi_SG_Fusion_RadarCapability_ALPCAN
      Rp_SG_Fusion_RadarStatus2_ALPCAN: nonqueued-receiver-com-spec{data-element=Vdp_SG_Fusion_RadarStatus2_ALPCAN, init-value=fields=[STS_AF_CORE_THROUGHPUT_Rx:0, STS_BRR_STATUS_Rx:0, STS_CAN_NM_State_Rx:0, STS_CORE_ACTV_FLT_BYTE_0_to_3_Rx:0, STS_CORE_ACTV_FLT_BYTE_4_to_7_Rx:0, STS_CORE_ACTV_FLT_BYTE_8_to_11_Rx:0, STS_CORE_ACTV_FLT_BYTE_11_to_15_Rx:0, STS_First_CAN_Det_Inst_Latency_Rx:0, STS_Gear_Position_Rx:0, STS_INTRFC_VERSION_ID_MAJOR_Rx:0, STS_INTRFC_VERSION_ID_MINOR_Rx:0, STS_INTRFC_VERSION_ID_PATCH_Rx:0, STS_Last_CAN_Det_Inst_Latency_Rx:0, STS_MCU_TEMP_Rx:0, STS_MH_002_CRC16_Rx:0, STS_MH_002_CYCLE_COUNTER_Rx:0, 0, STS_MMIC_TEMP_RX_Rx:0, STS_MMIC_TEMP_TX0_Rx:0, STS_MMIC_TEMP_TX1_2_Rx:0, STS_MMIC_TEMP_TX3_4_Rx:0, STS_NO_TSYN_ERROR_Rx:0, STS_POINT_OF_TRIGGER_Rx:0, STS_RAIN_COUNT_Rx:0, STS_RDD_CORE_THROUGHPUT_Rx:0, STS_SCAN_TYPE_Rx:0, STS_STEERING_ANGLE_Rx:0, STS_STEERING_ANGLE_SIGN_Rx:0, STS_TIME_SYNC_OFFSET_Rx:0, STS_TKEY_ACTV_FLT_BYTE_0_to_3_Rx:0, STS_TKEY_ACTV_FLT_BYTE_4_to_5_Rx:0, STS_VEH_SPEED_DIRECTION_Rx:0, STS_Vehicle_Speed_Calc_QF_Rx:0, STS_VEHICLE_SPEED_CALC_Rx:0, STS_VEHICLE_SUPPLY_VOLTAGE_Rx:0, STS_XCVR_OPERATIONAL_Rx:0, STS_YAW_RATE_BIAS_Rx:0, STS_Yaw_Rate_Calc_QF_Rx:0]}, required-interface=Pi_SG_Fusion_RadarStatus2_ALPCAN
      Rp_SG_GW_ADAS_FN_Enable_disable_sts_ALPCAN: nonqueued-receiver-com-spec{data-element=Vdp_SG_GW_ADAS_FN_Enable_disable_sts_ALPCAN, init-value=fields=[AEBS_FN_Switch_sts:0, BSIS_fn_Switch_Sts:0, DDAW_fn_switch_sts:0, DDAW_warning_suppression:0, LDWS_FN_Switch_sts:0, MessageAliveCounter:0, MessageCRC:0, MOIS_Fn_Switch_sts:0]}, required-interface=Pi_SG_GW_ADAS_FN_Enable_disable_sts_ALPCAN
      Rp_SG_GW_CCVS1_ALPCAN: nonqueued-receiver-com-spec{data-element=Vdp_SG_GW_CCVS1_ALPCAN, init-value=fields=[BrakeSwitch:0, ParkingBrakeSwitch:0, WheelBasedVehicleSpeed:0]}, required-interface=Pi_SG_GW_CCVS1_ALPCAN
      Rp_SG_GW_CLS_Tx_16_ALPCAN: nonqueued-receiver-com-spec{data-element=Vdp_SG_GW_CLS_Tx_16_ALPCAN, init-value=fields=[Crawler_confi_status_info:0, Transmission_type_info:0]}, required-interface=Pi_SG_GW_CLS_Tx_16_ALPCAN
      Rp_SG_GW_CLS_Tx_4_ALPCAN: nonqueued-receiver-com-spec{data-element=Vdp_SG_GW_CLS_Tx_4_ALPCAN, init-value=fields=[Ignition:0, ReverseSwitchInfo:0]}, required-interface=Pi_SG_GW_CLS_Tx_4_ALPCAN
      Rp_SG_GW_ETC2_ALPCAN: nonqueued-receiver-com-spec{data-element=Vdp_SG_GW_ETC2_ALPCAN, init-value=fields=TransCurrentGear_00:0}, required-interface=Pi_SG_GW_ETC2_ALPCAN
      Rp_SG_GW_OEL_ALPCAN: nonqueued-receiver-com-spec{data-element=Vdp_SG_GW_OEL_ALPCAN, init-value=fields=[HazardLightSwitch:0, HighLowBeamSwitch:0, TurnSignalSwitch:0]}, required-interface=Pi_SG_GW_OEL_ALPCAN
      Rp_SG_GW_SAS_ALPCAN: nonqueued-receiver-com-spec{data-element=Vdp_SG_GW_SAS_ALPCAN, init-value=fields=[MessageChecksum:0, MessageCounter:0, SteerAngleSensorActiveMode:0, SteerAngleSensorCalibrated:0, SteerWheelAngle:0, SteerWheelAngleRange:0, SteerWheelAngleRangeCounter:0, SteerWheelAngleRangeCounterType:0]}, required-interface=Pi_SG_GW_SAS_ALPCAN
      Rp_SG_GW_TD_ALPCAN: nonqueued-receiver-com-spec{data-element=Vdp_SG_GW_TD_ALPCAN, init-value=fields=[Day:0, Hours:0, LocalHourOffset:0, LocalMinuteOffset:0, Minutes:0, Month:0, Seconds:0, Year:0]}, required-interface=Pi_SG_GW_TD_ALPCAN
      Rp_SG_GW_VD_ALPCAN: nonqueued-receiver-com-spec{data-element=Vdp_SG_GW_VD_ALPCAN, init-value=fields=TotalVehicleDistance:0}, required-interface=Pi_SG_GW_VD_ALPCAN
      Rp_SG_GW_VI_ALPCAN: nonqueued-receiver-com-spec{data-element=Vdp_SG_GW_VI_ALPCAN, init-value=fields=VehicleIdentification:0}, required-interface=Pi_SG_GW_VI_ALPCAN
      Rp_SG_GW_ETC2_03_ALPCAN: nonqueued-receiver-com-spec{data-element=Vdp_SG_GW_ETC2_03_ALPCAN, init-value=fields=TransCurrentGear_03:0}, required-interface=Pi_SG_GW_ETC2_03_ALPCAN
      Rp_SG_GW_VDC2_ALPCAN: nonqueued-receiver-com-spec{data-element=Vdp_SG_GW_VDC2_ALPCAN, init-value=fields=[LateralAcceleration:0, LongitudinalAcceleration:0, SteerWheelAngle:0, YawRate:0]}, required-interface=Pi_SG_GW_VDC2_ALPCAN
    4 x provide port:
      Pp_SG_GW_prop_ADAS_BSIS_info_ALPCAN: nonqueued-sender-com-spec{data-element=Vdp_SG_GW_prop_ADAS_BSIS_info_ALPCAN, init-value=fields=[BlindSpotCollisionWarningLevel:0, BlindSpotDetectionState:0]}, provided-interface=Pi_SG_GW_prop_ADAS_BSIS_info_ALPCAN
      Pp_SG_RDR_BSD1_Tx_ALPCAN: nonqueued-sender-com-spec{data-element=Vdp_SG_RDR_BSD1_Tx_ALPCAN, init-value=fields=[BlindSpotCollisionWarningLevel_Tx:0, BlindSpotDetectionState_Tx:0]}, provided-interface=Pi_SG_RDR_BSD1_Tx_ALPCAN
      Pp_SG_MOIS_ALVCAN: nonqueued-sender-com-spec{data-element=Vdp_SG_MOIS_ALVCAN, init-value=fields=[MOISCollisionWarningLevel:0, MovingObjectDetectionState:0]}, provided-interface=Pi_SG_MOIS_ALVCAN
      Pp_SG_prop_ADAS_MOIS_info_ALVCAN: nonqueued-sender-com-spec{data-element=Vdp_SG_prop_ADAS_MOIS_info_ALVCAN, init-value=fields=[rdn_MOISCollisionWarningLevel:0, rdn_MovingObjectDetectionState:0]}, provided-interface=Pi_SG_prop_ADAS_MOIS_info_ALVCAN
    require port Rp_SG_Fusion_RadarHeader_ALPCAN: nonqueued-receiver-com-spec{data-element=Vdp_SG_Fusion_RadarHeader_ALPCAN, init-value=fields=[HED_ALIGN_HOR_REF_Rx:0, HED_ALIGN_VER_REF_Rx:0, HED_Auth_CRC32_Rx:0, HED_DATA_QUALIFIER_Rx:0, HED_DET_BI_STATIC_COUNT_Rx:0, HED_DET_NUM_OF_1PASS_Rx:0, HED_DET_NUM_OF_2PASS_Rx:0, HED_DET_RANGE_MAX_Rx:0, HED_DET_RANGE_MIN_Rx:0, HED_DET_SPEED_RANGE_MAX_Rx:0, HED_DET_SPEED_RANGE_MIN_Rx:0, HED_FOV_HOR_MAX_Rx:0, HED_FOV_HOR_MIN_Rx:0, HED_FOV_VER_MAX_Rx:0, HED_FOV_VER_MIN_Rx:0, HED_LOOK_ID_Rx:0, HED_LOOK_INDEX_Rx:0, HED_MAX_NUM_OF_DETECTIONS_Rx:0, HED_MH_CRC16_Rx:0, HED_MH_CYCLE_COUNTER_Rx:0, HED_NUM_OF_RESTBINS_USED_Rx:0, HED_NUM_OF_VALID_DETECTIONS_Rx:0, HED_OPERATION_MODE_Rx:0, HED_PROCESSED_RANGE_Rx:0, HED_R_WRAPPING_Rx:5 x 0, HED_Rain_Level_Rx:7 x 0, HED_RDR_HEADER_CMAC_Rx:5 x 0, HED_RDR_HEADER_FV_Rx:7 x 0, HED_SCAN_INDEX_Rx:0, HED_SENSOR_TIME_STAMP_NS_Rx:0, HED_SENSOR_TIME_STAMP_SEC_Rx:0, HED_SLOPE_CORR_EXECUTIONFLAG_Rx:0, HED_TIME_SYNC_SRC_MASTER_Rx:0, HED_TIME_SYNC_VALIDITY_FLAG_Rx:0, HED_TRIGGER_TIME_Rx:0, HED_V_WRAPPING_Rx:0]}, required-interface=Pi_SG_Fusion_RadarHeader_ALPCAN
    require port Rp_SG_Fusion_RadarStatus_ALPCAN: nonqueued-receiver-com-spec{data-element=Vdp_SG_Fusion_RadarStatus_ALPCAN, init-value=fields=[STS_AF_TIME_INST_Rx:0, STS_AF_TIME_PEAK_Rx:0, STS_DET_DBC_BASE_VER_MAJOR_Rx:0, STS_DET_DBC_BASE_VER_MINOR_Rx:0, STS_DIST_FRNT_BMPR_TO_RR_AXL_Rx:0, STS_HARDWARE_VERSION_Rx:0, STS_MAIN_CORE_TIME_INST_Rx:0, STS_MAIN_CORE_TIME_PEAK_Rx:0, STS_MH_001_CRC16_Rx:0, STS_MH_001_CYCLE_COUNTER_Rx:0, STS_PBL_VERSION_FIELD1_Rx:0, STS_PBL_VERSION_FIELD2_Rx:0, STS_PBL_VERSION_FIELD3_Rx:0, STS_PBL_VERSION_FIELD4_Rx:0, STS_PCAN_PROTOCOL_VER_MAJOR_Rx:0, STS_PCAN_PROTOCOL_VER_MINOR_Rx:0, STS_PLATFORM_VARIANT_Rx:0, STS_RDD_CORE_TIME_INST_Rx:0, STS_RDD_CORE_TIME_PEAK_Rx:0, STS_SENSOR_HEIGHT_Rx:0, STS_SENSOR_MOUNT_ORNT_PITCH_Rx:0, STS_SENSOR_MOUNT_ORNT_ROLL_Rx:0, STS_SENSOR_MOUNT_ORNT_YAW_Rx:0, STS_SENSOR_MOUNT_POS_X_Rx:0, STS_SENSOR_MOUNT_POS_Y_Rx:0, STS_SENSOR_MOUNT_POS_Z_Rx:0, STS_SENSOR_POLARITY_Rx:0, STS_SENSOR_POSITION_Rx:0, STS_SERIAL_NUM_JULIAN_DAY_Rx:0, STS_SERIAL_NUM_JULIAN_YEAR_Rx:0, STS_SERIAL_NUMBER_SEQUENCE_Rx:0, STS_SMC_CAL_VER_MAJOR_Rx:0, STS_SMC_CAL_VER_MINOR_Rx:0, STS_SMC_PLATFROM_VERSION_Rx:0, STS_SMC_SECTION_COMPTBLITY_Rx:0, STS_SP_CORE_TIME_INST_Rx:0, STS_SP_CORE_TIME_PEAK_Rx:0, STS_SW_VERSION_FIELD1_Rx:0, STS_SW_VERSION_FIELD2_Rx:0, STS_SW_VERSION_FIELD3_Rx:0, STS_SW_VERSION_FIELD4_Rx:0, STS_TIME_SINCE_POWER_ON_Rx:0, STS_USC_CAL_VER_MAJOR_Rx:0, STS_USC_CAL_VER_MINOR_Rx:0, STS_USC_SECTION_COMPTBLITY_Rx:0, STS_VIN_Status_Rx:0]}, required-interface=Pi_SG_Fusion_RadarStatus_ALPCAN
    provide port Pp_SG_RadarHeader_ALPCAN: nonqueued-sender-com-spec{data-element=Vdp_SG_RadarHeader_ALPCAN, init-value=fields=[HED_ALIGN_HOR_REF:0, HED_ALIGN_VER_REF:0, HED_Auth_CRC32:0, HED_DATA_QUALIFIER:1, HED_DET_BI_STATIC_COUNT:0, HED_DET_NUM_OF_1PASS:0, HED_DET_NUM_OF_2PASS:0, HED_DET_RANGE_MAX:0, HED_DET_RANGE_MIN:0, HED_DET_SPEED_RANGE_MAX:32768, HED_DET_SPEED_RANGE_MIN:32768, HED_FOV_HOR_MAX:0, HED_FOV_HOR_MIN:128, HED_FOV_VER_MAX:0, HED_FOV_VER_MIN:0, HED_LOOK_ID:0, HED_LOOK_INDEX:0, HED_MAX_NUM_OF_DETECTIONS:0, HED_MH_CRC16:0, HED_MH_CYCLE_COUNTER:0, HED_NUM_OF_RESTBINS_USED:0, HED_NUM_OF_VALID_DETECTIONS:0, HED_OPERATION_MODE:0, HED_PROCESSED_RANGE:0, HED_R_WRAPPING:5 x 90, HED_Rain_Level:7 x 0, HED_RDR_HEADER_CMAC:5 x 0, HED_RDR_HEADER_FV:7 x 0, HED_SCAN_INDEX:0, HED_SENSOR_TIME_STAMP_NS:0, HED_SENSOR_TIME_STAMP_SEC:0, HED_SLOPE_CORR_EXECUTIONFLAG:0, HED_TIME_SYNC_SRC_MASTER:0, HED_TIME_SYNC_VALIDITY_FLAG:0, HED_TRIGGER_TIME:0, HED_V_WRAPPING:0]}, provided-interface=Pi_SG_RadarHeader_ALPCAN
    provide port Pp_SG_RadarStatus1_ALPCAN: nonqueued-sender-com-spec{data-element=Vdp_SG_RadarStatus1_ALPCAN, init-value=fields=[STS_AF_TIME_INST:0, STS_AF_TIME_PEAK:0, STS_DET_DBC_BASE_VER_MAJOR:0, STS_DET_DBC_BASE_VER_MINOR:0, STS_DIST_FRNT_BMPR_TO_RR_AXL:0, STS_HARDWARE_VERSION:0, STS_MAIN_CORE_TIME_INST:0, STS_MAIN_CORE_TIME_PEAK:0, STS_MH_001_CRC16:0, STS_MH_001_CYCLE_COUNTER:0, STS_PBL_VERSION_FIELD1:0, STS_PBL_VERSION_FIELD2:0, STS_PBL_VERSION_FIELD3:0, STS_PBL_VERSION_FIELD4:0, STS_PCAN_PROTOCOL_VER_MAJOR:0, STS_PCAN_PROTOCOL_VER_MINOR:0, STS_PLATFORM_VARIANT:0, STS_RDD_CORE_TIME_INST:0, STS_RDD_CORE_TIME_PEAK:0, STS_SENSOR_HEIGHT:0, STS_SENSOR_MOUNT_ORNT_PITCH:0, STS_SENSOR_MOUNT_ORNT_ROLL:0, STS_SENSOR_MOUNT_ORNT_YAW:0, STS_SENSOR_MOUNT_POS_X:8192, STS_SENSOR_MOUNT_POS_Y:32768, STS_SENSOR_MOUNT_POS_Z:32768, STS_SENSOR_POLARITY:0, STS_SENSOR_POSITION:0, STS_SERIAL_NUM_JULIAN_DAY:365, STS_SERIAL_NUM_JULIAN_YEAR:0, STS_SERIAL_NUMBER_SEQUENCE:1234, STS_SMC_CAL_VER_MAJOR:0, STS_SMC_CAL_VER_MINOR:0, STS_SMC_PLATFROM_VERSION:0, STS_SMC_SECTION_COMPTBLITY:0, STS_SP_CORE_TIME_INST:0, STS_SP_CORE_TIME_PEAK:0, STS_SW_VERSION_FIELD1:0, STS_SW_VERSION_FIELD2:0, STS_SW_VERSION_FIELD3:0, STS_SW_VERSION_FIELD4:0, STS_TIME_SINCE_POWER_ON:0, STS_USC_CAL_VER_MAJOR:0, STS_USC_CAL_VER_MINOR:0, STS_USC_SECTION_COMPTBLITY:0, STS_VIN_Status:0]}, provided-interface=Pi_SG_RadarStatus1_ALPCAN
    15 x component:
      SWC_PLT_CDD_Logging: type=SWC_PLT_CDD_Logging
      SWC_PLT_CDD_Radar_Control: type=SWC_PLT_CDD_Radar_Control
      SWC_PLT_CDD_XCP: type=SWC_PLT_CDD_XCP
      SWC_PLT_CDD_ECUSync: type=SWC_PLT_CDD_ECUSync
      SWC_PLT_Appl_Communication: type=SWC_PLT_Appl_Communication
      SWC_PLT_Appl_PlatformTime: type=SWC_PLT_Appl_PlatformTime
      SWC_PLT_Appl_RTM: type=SWC_PLT_Appl_RTM
      ModeManagerCompositionType: type=ModeManagerCompositionType
      SWC_PLT_Appl_NvMHandler: type=SWC_PLT_Appl_NvMHandler
      SWC_PLT_CDD_ExternalWdg: type=SWC_PLT_CDD_ExternalWdg
      SWC_PLT_Appl_IntWDG: type=SWC_PLT_Appl_IntWDG
      SWC_PLT_CDD_WdgHandler: type=SWC_PLT_CDD_WdgHandler
      SWC_PLT_CDD_FCRU: type=SWC_PLT_CDD_FCRU
      SWC_PLT_CDD_HIL: type=SWC_PLT_CDD_HIL
      SWC_PLT_CDD_TimeSync: type=SWC_PLT_CDD_TimeSync
    connect SWC_PLT_CDD_Logging.PostRadarProcessing_Debug -> SWC_PLT_CDD_Radar_Control.PostRadarProcessing_Debug
    connect SWC_PLT_CDD_Logging.PostRadarProcessing_Detection -> SWC_PLT_CDD_Radar_Control.PostRadarProcessing_Detection
    connect SWC_PLT_CDD_Logging.PostRadarProcessing_Header -> SWC_PLT_CDD_Radar_Control.PostRadarProcessing_Header
    connect SWC_PLT_CDD_Logging.PostRadarProcessing_MMIC -> SWC_PLT_CDD_Radar_Control.PostRadarProcessing_MMIC
    connect SWC_PLT_CDD_Logging.PostRadarProcessing_Radar_Capability -> SWC_PLT_CDD_Radar_Control.PostRadarProcessing_Radar_Capability
    connect SWC_PLT_CDD_Logging.PostRadarProcessing_RDD -> SWC_PLT_CDD_Radar_Control.PostRadarProcessing_RDD
    connect SWC_PLT_CDD_Logging.PostRadarProcessing_Status -> SWC_PLT_CDD_Radar_Control.PostRadarProcessing_Status
    connect SWC_PLT_CDD_Logging.PostRadarProcessing_ADC -> SWC_PLT_CDD_Radar_Control.PostRadarProcessing_ADC
    connect SWC_PLT_CDD_ECUSync.Pp_Time_Stamp_Delta -> SWC_PLT_CDD_Logging.Rp_Time_Stamp_Delta
    connect SWC_PLT_CDD_ECUSync.Pp_TimeSync_Status_No_Tsyn_Error -> SWC_PLT_CDD_Logging.Rp_TimeSync_Status_No_Tsyn_Error
    connect SWC_PLT_CDD_Radar_Control.Pp_Radar_Ctl_Look_Trigger -> SWC_PLT_CDD_ECUSync.Pp_Radar_Ctl_Look_Trigger
    connect SWC_PLT_CDD_ECUSync.Pp_Radar_Ctl_Look_Complete -> SWC_PLT_CDD_Radar_Control.Rp_Radar_Ctl_Look_Complete
    connect SWC_PLT_CDD_XCP.Pp_XCP_CW_Mode -> SWC_PLT_CDD_Radar_Control.Rp_XCP_CW_Mode
    connect SWC_PLT_CDD_XCP.Pp_XCP_Op_Mode -> SWC_PLT_CDD_Radar_Control.Rp_XCP_Op_Mode
    connect SWC_PLT_CDD_XCP.Pp_XCP_Single_Look_Enable -> SWC_PLT_CDD_Radar_Control.Rp_XCP_Single_Look_Enable
    connect SWC_PLT_Appl_PlatformTime.Get_PlatfromTime_us -> SWC_PLT_CDD_ECUSync.CS_Get_PlatfromTime_us
    connect SWC_PLT_Appl_PlatformTime.CS_PlatformTime_Fault_Injection -> SWC_PLT_CDD_XCP.CS_PlatformTime_Fault_Injection
    connect SWC_PLT_Appl_PlatformTime.CS_Get_Platform_Elapsed_ustime -> SWC_PLT_CDD_ECUSync.CS_Get_Platform_Elapsed_ustime
    connect ModeManagerCompositionType.Pp_CommandRadiate_Final -> SWC_PLT_CDD_Radar_Control.Rp_Command_Radiate_Final
    connect ModeManagerCompositionType.Pp_IsRadiateForced -> SWC_PLT_CDD_Radar_Control.Rp_IsRadiateForced
    connect SWC_PLT_CDD_Radar_Control.Pp_Radar_Init_Status -> SWC_PLT_CDD_XCP.Rp_Radar_Init_Status
    connect SWC_PLT_CDD_Radar_Control.Pp_Radar_CMD_Radiate -> SWC_PLT_CDD_XCP.Rp_Radar_CMD_Radiate
    connect SWC_PLT_CDD_Radar_Control.Pp_RadarCoreStatus -> ModeManagerCompositionType.Rp_RadarCoreStatus
    connect SWC_PLT_CDD_Radar_Control.Pp_Diag_MMIC_ErrorFlags -> ModeManagerCompositionType.Rp_Diag_MMIC_ErrorFlags
    connect SWC_PLT_CDD_XCP.Pp_XCP_Fault_Override -> ModeManagerCompositionType.Rp_XCP_Fault_Override
    connect SWC_PLT_Appl_PlatformTime.Pp_TR_platform_Time -> ModeManagerCompositionType.Rp_TR_platform_Time
    delegate ModeManagerCompositionType.Rp_Alignment_Faults <-> outer port Rp_Alignment_Faults
    connect SWC_PLT_Appl_PlatformTime.Get_PlatfromTime_us -> ModeManagerCompositionType.Pp_Get_PlatfromTime_us_diag
    connect SWC_PLT_CDD_XCP.Pp_XCP_ForceRadiate -> ModeManagerCompositionType.Rp_XCP_ForceRadiate
    connect SWC_PLT_CDD_XCP.Pp_XCP_ADC_MCU_Temp_Override -> ModeManagerCompositionType.Rp_XCP_ADC_MCU_Temp_Override
    connect ModeManagerCompositionType.Pp_Analog_Channel_Count -> SWC_PLT_CDD_XCP.Rp_Analog_Channel_Count
    connect ModeManagerCompositionType.Pp_MCU_Sensor_Count -> SWC_PLT_CDD_XCP.Rp_MCU_Sensor_Count
    connect ModeManagerCompositionType.Pp_BoardRevision_Xcp -> SWC_PLT_CDD_XCP.Rp_BoardRevision_Xcp
    connect ModeManagerCompositionType.CS_Platform_register_set -> SWC_PLT_Appl_PlatformTime.CS_Platform_register_set
    connect ModeManagerCompositionType.Pp_ID_data -> SWC_PLT_CDD_XCP.Rp_ID_data
    connect ModeManagerCompositionType.CS_MCU_Safety_Fault_Injection -> SWC_PLT_CDD_XCP.CS_MCU_Safety_Fault_Injection
    connect SWC_PLT_Appl_PlatformTime.Pp_TR_platform_Time -> ModeManagerCompositionType.Rp_TR_PlatformTime
    connect ModeManagerCompositionType.CS_FailSafe_Fault_Injection -> SWC_PLT_CDD_XCP.CS_FailSafe_Fault_Injection
    connect ModeManagerCompositionType.CS_IPC_Fault_Injection -> SWC_PLT_CDD_XCP.CS_IPC_Fault_Injection
    delegate SWC_PLT_CDD_XCP.Rp_RawAdc_Data_UnFiltered <-> outer port Rp_RawAdc_Data_UnFiltered
    delegate SWC_PLT_CDD_XCP.Rp_RawAdc_Data_Filtered <-> outer port Rp_RawAdc_Data_Filtered
    connect ModeManagerCompositionType.Pp_RawAdc_Data_Filtered -> SWC_PLT_CDD_XCP.Rp_RawAdc_Data_Filtered
    connect ModeManagerCompositionType.Pp_RawAdc_Data_UnFiltered -> SWC_PLT_CDD_XCP.Rp_RawAdc_Data_UnFiltered
    delegate SWC_PLT_CDD_XCP.Rp_PhysicalAdcData <-> outer port Rp_PhysicalAdcData
    connect ModeManagerCompositionType.Pp_PhysicalAdcData -> SWC_PLT_CDD_XCP.Rp_PhysicalAdcData
    connect SWC_PLT_Appl_Communication.Pp_PCAN_Srv_DisableAppTx -> SWC_PLT_CDD_XCP.Rp_PCAN_Srv_DisableAppTx
    connect SWC_PLT_Appl_Communication.Pp_PCAN_Srv_EnableAppTx -> SWC_PLT_CDD_XCP.Rp_PCAN_Srv_EnableAppTx
    connect SWC_PLT_CDD_ExternalWdg.Pp_external_watchdog_init_status -> ModeManagerCompositionType.Rp_external_watchdog_init_status
    connect SWC_PLT_CDD_ExternalWdg.Pp_externalwatchdogstatus -> ModeManagerCompositionType.Rp_externalwatchdogstatus
    connect SWC_PLT_CDD_ExternalWdg.CS_External_Watchdog_Fault_Injection -> SWC_PLT_CDD_XCP.CS_External_Watchdog_Fault_Injection
    delegate SWC_PLT_Appl_Communication.Pp_RDR_Radar_SW_Info <-> outer port Pp_RDR_Radar_SW_Info
    delegate SWC_PLT_Appl_Communication.Pp_RDR_Radar_Status <-> outer port Pp_RDR_Radar_Status
    delegate SWC_PLT_Appl_Communication.Pp_RDR_DetectionList_Event <-> outer port Pp_RDR_DetectionList_Event
    delegate SWC_PLT_Appl_Communication.RP_RDR_Vehicle_Status <-> outer port RP_RDR_Vehicle_Status
    delegate SWC_PLT_CDD_XCP.CS_Modemanager_Fault_Injection <-> outer port CS_Modemanager_Fault_Injection
    connect ModeManagerCompositionType.CS_Modemanager_Fault_Injection -> SWC_PLT_CDD_XCP.CS_Modemanager_Fault_Injection
    connect SWC_PLT_CDD_Radar_Control.CS_Radar_control_Fault_Injection -> SWC_PLT_CDD_XCP.CS_Radar_control_Fault_Injection
    delegate SWC_PLT_CDD_XCP.CS_Diag_Fault_Injection <-> outer port CS_Diag_Fault_Injection
    connect ModeManagerCompositionType.CS_Diag_Fault_Injection -> SWC_PLT_CDD_XCP.CS_Diag_Fault_Injection
    connect SWC_PLT_CDD_WdgHandler.CS_Wdg_Disable -> SWC_PLT_Appl_IntWDG.CS_Wdg_Disable
    delegation sw connector CS_Alignment_Fault_Injection_SWC_PLT_CDD_XCP_CS_Alignment_Fault_Injection: inner-port=SWC_PLT_CDD_XCP.CS_Alignment_Fault_Injection
    delegate SWC_PLT_CDD_XCP.CS_Signal_Integrity_Fault_Injection <-> outer port CS_Signal_Integrity_Fault_Injection
    delegate SWC_PLT_CDD_XCP.Pp_XCP_Set_Output_State <-> outer port Pp_XCP_Set_Output_State
    connect SWC_PLT_CDD_Radar_Control.Pp_MMIC_Count -> SWC_PLT_CDD_XCP.Rp_MMIC_Count
    delegate SWC_PLT_CDD_XCP.CS_ThermMonTemp <-> outer port CS_ThermMonTemp
    connect SWC_PLT_CDD_Radar_Control.Pp_MMIC_Temperature -> SWC_PLT_CDD_XCP.Rp_MMIC_Temperature
    delegate SWC_PLT_CDD_Logging.Rp_FailSafe_ResetReason <-> outer port Rp_FailSafe_ResetReason
    connect ModeManagerCompositionType.Pp_FailSafe_ResetReason -> SWC_PLT_CDD_Logging.Rp_FailSafe_ResetReason
    delegate SWC_PLT_Appl_NvMHandler.Rp_FailSafe_ResetReason <-> outer port Rp_FailSafe_ResetReason
    delegate SWC_PLT_Appl_NvMHandler.CS_Trigger_Write_to_NVM <-> outer port CS_Trigger_Write_to_NVM
    connect SWC_PLT_Appl_NvMHandler.CS_Trigger_Write_to_NVM -> ModeManagerCompositionType.CS_Trigger_Write_to_NVM
    delegate SWC_PLT_Appl_Communication.Rp_TSYN_RESERVED <-> outer port Rp_TSYN_RESERVED
    delegate SWC_PLT_Appl_Communication.Rp_TSYN_SEQUENCE_COUNTER <-> outer port Rp_TSYN_SEQUENCE_COUNTER
    delegate SWC_PLT_Appl_Communication.Rp_TSYN_PDU <-> outer port Rp_TSYN_PDU
    delegate SWC_PLT_Appl_Communication.Rp_TSYN_SYNCTIME_NANOSEC <-> outer port Rp_TSYN_SYNCTIME_NANOSEC
    delegate SWC_PLT_Appl_Communication.Rp_TSYN_USERBYTE <-> outer port Rp_TSYN_USERBYTE
    delegate SWC_PLT_Appl_Communication.Rp_TSYN_TIMEDOMAIN <-> outer port Rp_TSYN_TIMEDOMAIN
    delegate SWC_PLT_Appl_Communication.Rp_TSYN_OVS <-> outer port Rp_TSYN_OVS
    delegate SWC_PLT_Appl_Communication.Rp_TSYN_SGW <-> outer port Rp_TSYN_SGW
    delegate SWC_PLT_Appl_Communication.Rp_TSYNC_CRC <-> outer port Rp_TSYNC_CRC
    delegate SWC_PLT_Appl_Communication.Rp_TSYN_SYNCTIME_SEC <-> outer port Rp_TSYN_SYNCTIME_SEC
    delegate SWC_PLT_Appl_Communication.Pp_SG_TrackerObject010 <-> outer port Pp_SG_TrackerObject010
    delegate SWC_PLT_Appl_Communication.Pp_RDR_NM_CBV_ResdBit_7 <-> outer port Pp_RDR_NM_CBV_ResdBit_7
    delegate SWC_PLT_Appl_Communication.Pp_RDR_NM_CBV_ResdBit_5 <-> outer port Pp_RDR_NM_CBV_ResdBit_5
    delegate SWC_PLT_Appl_Communication.Pp_RDR_NM_CBV_ActWakeBit_4 <-> outer port Pp_RDR_NM_CBV_ActWakeBit_4
    delegate SWC_PLT_Appl_Communication.Pp_RDR_NM_CBV_ReptMsgBit0 <-> outer port Pp_RDR_NM_CBV_ReptMsgBit0
    delegate SWC_PLT_Appl_Communication.Pp_SG_TrackerObject060 <-> outer port Pp_SG_TrackerObject060
    delegate SWC_PLT_Appl_Communication.Pp_SG_TrackerObject038 <-> outer port Pp_SG_TrackerObject038
    delegate SWC_PLT_Appl_Communication.Pp_RDR_NM_Wakeup_And_Reason <-> outer port Pp_RDR_NM_Wakeup_And_Reason
    delegate SWC_PLT_Appl_Communication.Pp_SG_TrackerObject052 <-> outer port Pp_SG_TrackerObject052
    delegate SWC_PLT_Appl_Communication.Pp_SG_TrackerObject051 <-> outer port Pp_SG_TrackerObject051
    delegate SWC_PLT_Appl_Communication.Pp_SG_TrackerObject002 <-> outer port Pp_SG_TrackerObject002
    delegate SWC_PLT_Appl_Communication.Pp_SG_TrackerObject034 <-> outer port Pp_SG_TrackerObject034
    delegate SWC_PLT_Appl_Communication.Pp_SG_TrackerObject050 <-> outer port Pp_SG_TrackerObject050
    delegate SWC_PLT_Appl_Communication.Pp_SG_TrackerObject020 <-> outer port Pp_SG_TrackerObject020
    delegate SWC_PLT_Appl_Communication.Pp_SG_TrackerObject029 <-> outer port Pp_SG_TrackerObject029
    delegate SWC_PLT_Appl_Communication.Pp_SG_TrackerObject057 <-> outer port Pp_SG_TrackerObject057
    delegate SWC_PLT_Appl_Communication.Pp_SG_TrackerObject033 <-> outer port Pp_SG_TrackerObject033
    delegate SWC_PLT_Appl_Communication.Pp_SG_TrackerObject064 <-> outer port Pp_SG_TrackerObject064
    delegate SWC_PLT_Appl_Communication.Pp_SG_TrackerObject063 <-> outer port Pp_SG_TrackerObject063
    delegate SWC_PLT_Appl_Communication.Pp_SG_TrackerObject046 <-> outer port Pp_SG_TrackerObject046
    delegate SWC_PLT_Appl_Communication.Pp_SG_TrackerObject005 <-> outer port Pp_SG_TrackerObject005
    delegate SWC_PLT_Appl_Communication.Pp_RDR_NM_PNC_Reserved3 <-> outer port Pp_RDR_NM_PNC_Reserved3
    delegate SWC_PLT_Appl_Communication.Pp_SG_TrackerObject040 <-> outer port Pp_SG_TrackerObject040
    delegate SWC_PLT_Appl_Communication.Pp_RDR_NM_CBV_NMCoordBit_3 <-> outer port Pp_RDR_NM_CBV_NMCoordBit_3
    delegate SWC_PLT_Appl_Communication.Pp_SG_TrackerObject059 <-> outer port Pp_SG_TrackerObject059
    delegate SWC_PLT_Appl_Communication.Pp_SG_TrackerObject030 <-> outer port Pp_SG_TrackerObject030
    delegate SWC_PLT_Appl_Communication.Pp_SG_TrackerObject042 <-> outer port Pp_SG_TrackerObject042
    delegate SWC_PLT_Appl_Communication.Pp_SG_TrackerObject061 <-> outer port Pp_SG_TrackerObject061
    delegate SWC_PLT_Appl_Communication.Pp_RDR_NM_PN_User_Data <-> outer port Pp_RDR_NM_PN_User_Data
    delegate SWC_PLT_Appl_Communication.Pp_SG_TrackerObject021 <-> outer port Pp_SG_TrackerObject021
    delegate SWC_PLT_Appl_Communication.Pp_SG_TrackerObject036 <-> outer port Pp_SG_TrackerObject036
    delegate SWC_PLT_Appl_Communication.Pp_SG_TrackerObject001 <-> outer port Pp_SG_TrackerObject001
    delegate SWC_PLT_Appl_Communication.Pp_SG_TrackerObject022 <-> outer port Pp_SG_TrackerObject022
    delegate SWC_PLT_Appl_Communication.Pp_SG_TrackerObject041 <-> outer port Pp_SG_TrackerObject041
    delegate SWC_PLT_Appl_Communication.Pp_RDR_NM_CBV_ResdBit_2 <-> outer port Pp_RDR_NM_CBV_ResdBit_2
    delegate SWC_PLT_Appl_Communication.Pp_SG_TrackerObject025 <-> outer port Pp_SG_TrackerObject025
    delegate SWC_PLT_Appl_Communication.Pp_SG_TrackerObject045 <-> outer port Pp_SG_TrackerObject045
    delegate SWC_PLT_Appl_Communication.Pp_SG_TrackerObject013 <-> outer port Pp_SG_TrackerObject013
    delegate SWC_PLT_Appl_Communication.Pp_RDR_NM_CBV_PNIBit_6 <-> outer port Pp_RDR_NM_CBV_PNIBit_6
    delegate SWC_PLT_Appl_Communication.Pp_SG_TrackerObject008 <-> outer port Pp_SG_TrackerObject008
    delegate SWC_PLT_Appl_Communication.Pp_SG_TrackerObject031 <-> outer port Pp_SG_TrackerObject031
    delegate SWC_PLT_Appl_Communication.Pp_SG_TrackerObject062 <-> outer port Pp_SG_TrackerObject062
    delegate SWC_PLT_Appl_Communication.Pp_SG_TrackerObject028 <-> outer port Pp_SG_TrackerObject028
    delegate SWC_PLT_Appl_Communication.Pp_SG_TrackerObject049 <-> outer port Pp_SG_TrackerObject049
    delegate SWC_PLT_Appl_Communication.Pp_SG_TrackerObject019 <-> outer port Pp_SG_TrackerObject019
    delegate SWC_PLT_Appl_Communication.Pp_SG_TrackerObject056 <-> outer port Pp_SG_TrackerObject056
    delegate SWC_PLT_Appl_Communication.Pp_RDR_NM_CAN_NM_State <-> outer port Pp_RDR_NM_CAN_NM_State
    delegate SWC_PLT_Appl_Communication.Pp_SG_TrackerObject035 <-> outer port Pp_SG_TrackerObject035
    delegate SWC_PLT_Appl_Communication.Pp_SG_TrackerObject053 <-> outer port Pp_SG_TrackerObject053
    delegate SWC_PLT_Appl_Communication.Pp_SG_TrackerObject012 <-> outer port Pp_SG_TrackerObject012
    delegate SWC_PLT_Appl_Communication.Pp_RDR_NM_CBV_ResdBit_1 <-> outer port Pp_RDR_NM_CBV_ResdBit_1
    delegate SWC_PLT_Appl_Communication.Pp_SG_TrackerObject011 <-> outer port Pp_SG_TrackerObject011
    delegate SWC_PLT_Appl_Communication.Pp_SG_TrackerObject054 <-> outer port Pp_SG_TrackerObject054
    delegate SWC_PLT_Appl_Communication.Pp_SG_TrackerObject037 <-> outer port Pp_SG_TrackerObject037
    delegate SWC_PLT_Appl_Communication.Pp_SG_TrackerObject023 <-> outer port Pp_SG_TrackerObject023
    delegate SWC_PLT_Appl_Communication.Pp_SG_TrackerObject047 <-> outer port Pp_SG_TrackerObject047
    delegate SWC_PLT_Appl_Communication.Pp_SG_TrackerObject027 <-> outer port Pp_SG_TrackerObject027
    delegate SWC_PLT_Appl_Communication.Pp_SG_TrackerObject007 <-> outer port Pp_SG_TrackerObject007
    delegate SWC_PLT_Appl_Communication.Pp_SG_TrackerObject016 <-> outer port Pp_SG_TrackerObject016
    delegate SWC_PLT_Appl_Communication.Pp_SG_TrackerObject039 <-> outer port Pp_SG_TrackerObject039
    delegate SWC_PLT_Appl_Communication.Pp_SG_TrackerObject055 <-> outer port Pp_SG_TrackerObject055
    delegate SWC_PLT_Appl_Communication.Pp_SG_TrackerHeader <-> outer port Pp_SG_TrackerHeader
    delegate SWC_PLT_Appl_Communication.Pp_SG_TrackerStatus <-> outer port Pp_SG_TrackerStatus
    delegate SWC_PLT_Appl_Communication.Pp_SG_TrackerObject024 <-> outer port Pp_SG_TrackerObject024
    delegate SWC_PLT_Appl_Communication.Pp_SG_TrackerObject014 <-> outer port Pp_SG_TrackerObject014
    delegate SWC_PLT_Appl_Communication.Pp_RDR_NM_PNC_Reserved2 <-> outer port Pp_RDR_NM_PNC_Reserved2
    delegate SWC_PLT_Appl_Communication.Pp_SG_TrackerObject009 <-> outer port Pp_SG_TrackerObject009
    delegate SWC_PLT_Appl_Communication.Pp_SG_TrackerObject044 <-> outer port Pp_SG_TrackerObject044
    delegate SWC_PLT_Appl_Communication.Pp_SG_TrackerObject003 <-> outer port Pp_SG_TrackerObject003
    delegate SWC_PLT_Appl_Communication.Pp_SG_TrackerObject015 <-> outer port Pp_SG_TrackerObject015
    delegate SWC_PLT_Appl_Communication.Pp_SG_TrackerObject026 <-> outer port Pp_SG_TrackerObject026
    delegate SWC_PLT_Appl_Communication.Pp_SG_TrackerObject004 <-> outer port Pp_SG_TrackerObject004
    delegate SWC_PLT_Appl_Communication.Pp_SG_TrackerObject018 <-> outer port Pp_SG_TrackerObject018
    delegate SWC_PLT_Appl_Communication.Pp_SG_TrackerObject006 <-> outer port Pp_SG_TrackerObject006
    delegate SWC_PLT_Appl_Communication.Pp_SG_TrackerObject043 <-> outer port Pp_SG_TrackerObject043
    delegate SWC_PLT_Appl_Communication.Pp_SG_TrackerObject058 <-> outer port Pp_SG_TrackerObject058
    delegate SWC_PLT_Appl_Communication.Pp_SG_TrackerObject032 <-> outer port Pp_SG_TrackerObject032
    delegate SWC_PLT_Appl_Communication.Pp_SG_TrackerObject017 <-> outer port Pp_SG_TrackerObject017
    delegate SWC_PLT_Appl_Communication.Pp_RDR_NM_PNC_Reserved1 <-> outer port Pp_RDR_NM_PNC_Reserved1
    delegate SWC_PLT_Appl_Communication.Pp_SG_TrackerObject048 <-> outer port Pp_SG_TrackerObject048
    connect SWC_PLT_CDD_WdgHandler.CS_WdgHandler_Fault_Injection -> SWC_PLT_CDD_XCP.CS_WdgHandler_Fault_Injection
    delegate SWC_PLT_CDD_FCRU.Pp_PMU_FaultB_PinIntegrity <-> outer port Pp_PMU_FaultB_PinIntegrity
    delegate ModeManagerCompositionType.Rp_PMU_FaultB_PinIntegrity <-> outer port Rp_PMU_FaultB_PinIntegrity
    connect SWC_PLT_CDD_FCRU.Pp_PMU_FaultB_PinIntegrity -> ModeManagerCompositionType.Rp_PMU_FaultB_PinIntegrity
    delegate SWC_PLT_CDD_XCP.Rp_MPU_lock_sts <-> outer port Rp_MPU_lock_sts
    delegate SWC_PLT_CDD_XCP.Pp_MPU_lock_request <-> outer port Pp_MPU_lock_request
    connect ModeManagerCompositionType.Pp_MPU_lock_sts -> SWC_PLT_CDD_XCP.Rp_MPU_lock_sts
    connect SWC_PLT_CDD_XCP.Pp_MPU_lock_request -> ModeManagerCompositionType.Rp_MPU_lock_request
    connect SWC_PLT_CDD_XCP.Pp_Hil_Activation -> SWC_PLT_CDD_HIL.Rp_Hil_Activation
    delegate SWC_PLT_CDD_HIL.Rp_HIL_Periodic_Handler <-> outer port Rp_HIL_Periodic_Handler
    connect ModeManagerCompositionType.Pp_HIL_Periodic_Handler -> SWC_PLT_CDD_HIL.Rp_HIL_Periodic_Handler
    delegate SWC_PLT_Appl_NvMHandler.CS_Pp_Trigger_Write_to_NvM <-> outer port CS_Pp_Trigger_Write_to_NvM
    delegate SWC_PLT_Appl_NvMHandler.Rp_Align_Write_Nvm_Record <-> outer port Rp_Align_Write_Nvm_Record
    connect SWC_PLT_Appl_IntWDG.CS_Disable_Wdg_Supervised_Entites -> SWC_PLT_CDD_Radar_Control.CS_Disable_Wdg_Supervised_Entites
    connect SWC_PLT_CDD_WdgHandler.Pp_Internal_Wdg_Fail_Status -> SWC_PLT_CDD_ExternalWdg.Rp_Internal_Wdg_Fail_Status
    connect SWC_PLT_CDD_FCRU.CS_FCRU_Fault_Injection -> SWC_PLT_CDD_XCP.CS_FCRU_Fault_Injection
    connect ModeManagerCompositionType.CS_Failsafe_Log_ResetReason_at_Startup -> SWC_PLT_CDD_FCRU.CS_Failsafe_Log_ResetReason_at_Startup
    connect SWC_PLT_Appl_NvMHandler.Pp_Alignment_NvM_Read_Record -> SWC_PLT_CDD_XCP.Rp_Alignment_NvM_Read_Record
    delegate ModeManagerCompositionType.Pp_Active_Fault_Latch_Table <-> outer port Pp_Active_Fault_Latch_Table
    delegate ModeManagerCompositionType.Pp_Active_Fault_Table <-> outer port Pp_Active_Fault_Table
    delegate ModeManagerCompositionType.Pp_HistoryFaultTable <-> outer port Pp_HistoryFaultTable
    delegate ModeManagerCompositionType.Pp_Fault_Test_Complete_Table <-> outer port Pp_Fault_Test_Complete_Table
    connect SWC_PLT_Appl_NvMHandler.Pp_NvM_flag_status -> SWC_PLT_CDD_XCP.Rp_NvM_flag_status
    connect SWC_PLT_CDD_XCP.Pp_XCP_Phase_Rotator_Calibration -> SWC_PLT_CDD_Radar_Control.Rp_XCP_Phase_Rotator_Calibration
    connect SWC_PLT_Appl_RTM.Pp_CPU_Load -> SWC_PLT_CDD_Logging.Rp_CPU_Load
    delegate SWC_PLT_CDD_XCP.Rp_Fault_Test_Complete_Table <-> outer port Rp_Fault_Test_Complete_Table
    delegate SWC_PLT_CDD_XCP.Rp_Active_Fault_Table <-> outer port Rp_Active_Fault_Table
    delegate SWC_PLT_CDD_XCP.Rp_HistoryFaultTable <-> outer port Rp_HistoryFaultTable
    delegate SWC_PLT_CDD_XCP.Rp_Active_Fault_Latch_Table <-> outer port Rp_Active_Fault_Latch_Table
    connect SWC_PLT_CDD_XCP.Pp_XCP_Ethernet_En_Dis -> SWC_PLT_CDD_Logging.Rp_XCP_Ethernet_En_Dis
    connect SWC_PLT_Appl_NvMHandler.CS_Trigger_Write_to_NVM -> SWC_PLT_CDD_Radar_Control.CS_Radar_Control_Rfe_R1R2_NvM_Write
    delegate ModeManagerCompositionType.PostRadarProcessing_Detection <-> outer port PostRadarProcessing_Detection
    delegate ModeManagerCompositionType.PostRadarProcessing_Header <-> outer port PostRadarProcessing_Header
    delegate ModeManagerCompositionType.PostRadarProcessing_Radar_Capability <-> outer port PostRadarProcessing_Radar_Capability
    connect SWC_PLT_CDD_Logging.PostRadarProcessing_Detection -> ModeManagerCompositionType.PostRadarProcessing_Detection
    connect SWC_PLT_CDD_Logging.PostRadarProcessing_Header -> ModeManagerCompositionType.PostRadarProcessing_Header
    connect SWC_PLT_CDD_Logging.PostRadarProcessing_Radar_Capability -> ModeManagerCompositionType.PostRadarProcessing_Radar_Capability
    delegate ModeManagerCompositionType.PostRadarProcessing_Debug <-> outer port PostRadarProcessing_Debug
    connect SWC_PLT_CDD_Logging.PostRadarProcessing_Debug -> ModeManagerCompositionType.PostRadarProcessing_Debug
    delegate ModeManagerCompositionType.PostRadarProcessing_MMIC <-> outer port PostRadarProcessing_MMIC
    connect SWC_PLT_CDD_Logging.PostRadarProcessing_MMIC -> ModeManagerCompositionType.PostRadarProcessing_MMIC
    delegate ModeManagerCompositionType.PostRadarProcessing_RDD <-> outer port PostRadarProcessing_RDD
    connect SWC_PLT_CDD_Logging.PostRadarProcessing_RDD -> ModeManagerCompositionType.PostRadarProcessing_RDD
    delegate ModeManagerCompositionType.PostRadarProcessing_Status <-> outer port PostRadarProcessing_Status
    connect SWC_PLT_CDD_Logging.PostRadarProcessing_Status -> ModeManagerCompositionType.PostRadarProcessing_Status
    delegate ModeManagerCompositionType.Pp_Radar_Ctl_Look_Trigger <-> outer port Pp_Radar_Ctl_Look_Trigger
    connect SWC_PLT_CDD_Radar_Control.Pp_Radar_Ctl_Look_Trigger -> ModeManagerCompositionType.Pp_Radar_Ctl_Look_Trigger
    delegate SWC_PLT_Appl_Communication.Pp_SG_Detections_365_368_AL <-> outer port Pp_SG_Detections_365_368_AL
    delegate SWC_PLT_Appl_Communication.Pp_SG_Detections_285_288_AL <-> outer port Pp_SG_Detections_285_288_AL
    delegate SWC_PLT_Appl_Communication.Pp_SG_Detections_341_344_AL <-> outer port Pp_SG_Detections_341_344_AL
    delegate SWC_PLT_Appl_Communication.Pp_SG_Detections_277_280_AL <-> outer port Pp_SG_Detections_277_280_AL
    delegate SWC_PLT_Appl_Communication.Pp_SG_Detections_273_276_AL <-> outer port Pp_SG_Detections_273_276_AL
    delegate SWC_PLT_Appl_Communication.Pp_SG_Detections_249_252_AL <-> outer port Pp_SG_Detections_249_252_AL
    delegate SWC_PLT_Appl_Communication.Pp_SG_Detections_389_392_AL <-> outer port Pp_SG_Detections_389_392_AL
    delegate SWC_PLT_Appl_Communication.Pp_SG_Detections_349_352_AL <-> outer port Pp_SG_Detections_349_352_AL
    delegate SWC_PLT_Appl_Communication.Pp_SG_Detections_245_248_AL <-> outer port Pp_SG_Detections_245_248_AL
    delegate SWC_PLT_Appl_Communication.Pp_SG_Detections_361_364_AL <-> outer port Pp_SG_Detections_361_364_AL
    delegate SWC_PLT_Appl_Communication.Pp_SG_Detections_353_356_AL <-> outer port Pp_SG_Detections_353_356_AL
    delegate SWC_PLT_Appl_Communication.Pp_SG_Detections_253_256_AL <-> outer port Pp_SG_Detections_253_256_AL
    delegate SWC_PLT_Appl_Communication.Pp_SG_Detections_257_260_AL <-> outer port Pp_SG_Detections_257_260_AL
    delegate SWC_PLT_Appl_Communication.Pp_SG_Detections_373_376_AL <-> outer port Pp_SG_Detections_373_376_AL
    delegate SWC_PLT_Appl_Communication.Pp_SG_Detections_305_308_AL <-> outer port Pp_SG_Detections_305_308_AL
    delegate SWC_PLT_Appl_Communication.Pp_SG_Detections_393_396_AL <-> outer port Pp_SG_Detections_393_396_AL
    delegate SWC_PLT_Appl_Communication.Pp_SG_Detections_325_328_AL <-> outer port Pp_SG_Detections_325_328_AL
    delegate SWC_PLT_Appl_Communication.Pp_SG_Detections_377_380_AL <-> outer port Pp_SG_Detections_377_380_AL
    delegate SWC_PLT_Appl_Communication.Pp_SG_Detections_345_348_AL <-> outer port Pp_SG_Detections_345_348_AL
    delegate SWC_PLT_Appl_Communication.Pp_SG_Detections_261_264_AL <-> outer port Pp_SG_Detections_261_264_AL
    delegate SWC_PLT_Appl_Communication.Pp_SG_Detections_357_360_AL <-> outer port Pp_SG_Detections_357_360_AL
    delegate SWC_PLT_Appl_Communication.Pp_SG_Detections_241_244_AL <-> outer port Pp_SG_Detections_241_244_AL
    delegate SWC_PLT_Appl_Communication.Pp_SG_Detections_297_300_AL <-> outer port Pp_SG_Detections_297_300_AL
    delegate SWC_PLT_Appl_Communication.Pp_SG_Detections_233_236_AL <-> outer port Pp_SG_Detections_233_236_AL
    delegate SWC_PLT_Appl_Communication.Pp_SG_Detections_313_316_AL <-> outer port Pp_SG_Detections_313_316_AL
    delegate SWC_PLT_Appl_Communication.Pp_SG_Detections_397_400_AL <-> outer port Pp_SG_Detections_397_400_AL
    delegate SWC_PLT_Appl_Communication.Pp_SG_Detections_237_240_AL <-> outer port Pp_SG_Detections_237_240_AL
    delegate SWC_PLT_Appl_Communication.Pp_SG_Detections_329_332_AL <-> outer port Pp_SG_Detections_329_332_AL
    delegate SWC_PLT_Appl_Communication.Pp_SG_Detections_293_296_AL <-> outer port Pp_SG_Detections_293_296_AL
    delegate SWC_PLT_Appl_Communication.Pp_SG_Detections_333_336_AL <-> outer port Pp_SG_Detections_333_336_AL
    delegate SWC_PLT_Appl_Communication.Pp_SG_Detections_369_372_AL <-> outer port Pp_SG_Detections_369_372_AL
    delegate SWC_PLT_Appl_Communication.Pp_SG_Detections_321_324_AL <-> outer port Pp_SG_Detections_321_324_AL
    delegate SWC_PLT_Appl_Communication.Pp_SG_Detections_317_320_AL <-> outer port Pp_SG_Detections_317_320_AL
    delegate SWC_PLT_Appl_Communication.Pp_SG_Detections_265_268_AL <-> outer port Pp_SG_Detections_265_268_AL
    delegate SWC_PLT_Appl_Communication.Pp_SG_Detections_385_388_AL <-> outer port Pp_SG_Detections_385_388_AL
    delegate SWC_PLT_Appl_Communication.Pp_SG_Detections_309_312_AL <-> outer port Pp_SG_Detections_309_312_AL
    delegate SWC_PLT_Appl_Communication.Pp_SG_Detections_301_304_AL <-> outer port Pp_SG_Detections_301_304_AL
    delegate SWC_PLT_Appl_Communication.Pp_SG_Detections_337_340_AL <-> outer port Pp_SG_Detections_337_340_AL
    delegate SWC_PLT_Appl_Communication.Pp_SG_Detections_281_284_AL <-> outer port Pp_SG_Detections_281_284_AL
    delegate SWC_PLT_Appl_Communication.Pp_SG_Detections_289_292_AL <-> outer port Pp_SG_Detections_289_292_AL
    delegate SWC_PLT_Appl_Communication.Pp_SG_Detections_381_384_AL <-> outer port Pp_SG_Detections_381_384_AL
    delegate SWC_PLT_Appl_Communication.Pp_SG_Detections_269_272_AL <-> outer port Pp_SG_Detections_269_272_AL
    delegate SWC_PLT_Appl_Communication.Pp_SG_Detections_089_092_AL <-> outer port Pp_SG_Detections_089_092_AL
    delegate SWC_PLT_Appl_Communication.Pp_SG_Detections_001_004_AL <-> outer port Pp_SG_Detections_001_004_AL
    delegate SWC_PLT_Appl_Communication.Pp_SG_Detections_209_212_AL <-> outer port Pp_SG_Detections_209_212_AL
    delegate SWC_PLT_Appl_Communication.Pp_SG_Detections_065_068_AL <-> outer port Pp_SG_Detections_065_068_AL
    delegate SWC_PLT_Appl_Communication.Pp_SG_Detections_133_136_AL <-> outer port Pp_SG_Detections_133_136_AL
    delegate SWC_PLT_Appl_Communication.Pp_SG_Detections_129_132_AL <-> outer port Pp_SG_Detections_129_132_AL
    delegate SWC_PLT_Appl_Communication.Pp_SG_Detections_205_208_AL <-> outer port Pp_SG_Detections_205_208_AL
    delegate SWC_PLT_Appl_Communication.Pp_SG_Detections_041_044_AL <-> outer port Pp_SG_Detections_041_044_AL
    delegate SWC_PLT_Appl_Communication.Pp_SG_Detections_017_020_AL <-> outer port Pp_SG_Detections_017_020_AL
    delegate SWC_PLT_Appl_Communication.Pp_SG_Detections_217_220_AL <-> outer port Pp_SG_Detections_217_220_AL
    delegate SWC_PLT_Appl_Communication.Pp_SG_Detections_149_152_AL <-> outer port Pp_SG_Detections_149_152_AL
    delegate SWC_PLT_Appl_Communication.Pp_SG_Detections_197_200_AL <-> outer port Pp_SG_Detections_197_200_AL
    delegate SWC_PLT_Appl_Communication.Pp_SG_Detections_085_088_AL <-> outer port Pp_SG_Detections_085_088_AL
    delegate SWC_PLT_Appl_Communication.Pp_SG_Detections_225_228_AL <-> outer port Pp_SG_Detections_225_228_AL
    delegate SWC_PLT_Appl_Communication.Pp_SG_Detections_177_180_AL <-> outer port Pp_SG_Detections_177_180_AL
    delegate SWC_PLT_Appl_Communication.Pp_SG_Detections_081_084_AL <-> outer port Pp_SG_Detections_081_084_AL
    delegate SWC_PLT_Appl_Communication.Pp_SG_AlignmentStatus1_AL <-> outer port Pp_SG_AlignmentStatus1_AL
    delegate SWC_PLT_Appl_Communication.Pp_SG_Detections_029_032_AL <-> outer port Pp_SG_Detections_029_032_AL
    delegate SWC_PLT_Appl_Communication.Pp_SG_Detections_169_172_AL <-> outer port Pp_SG_Detections_169_172_AL
    delegate SWC_PLT_Appl_Communication.Pp_SG_Detections_005_008_AL <-> outer port Pp_SG_Detections_005_008_AL
    delegate SWC_PLT_Appl_Communication.Pp_SG_AlignmentStatus2_AL <-> outer port Pp_SG_AlignmentStatus2_AL
    delegate SWC_PLT_Appl_Communication.Pp_SG_Detections_189_192_AL <-> outer port Pp_SG_Detections_189_192_AL
    delegate SWC_PLT_Appl_Communication.Pp_SG_Detections_229_232_AL <-> outer port Pp_SG_Detections_229_232_AL
    delegate SWC_PLT_Appl_Communication.Pp_SG_Detections_009_012_AL <-> outer port Pp_SG_Detections_009_012_AL
    delegate SWC_PLT_Appl_Communication.Pp_SG_Detections_125_128_AL <-> outer port Pp_SG_Detections_125_128_AL
    delegate SWC_PLT_Appl_Communication.Pp_SG_Detections_137_140_AL <-> outer port Pp_SG_Detections_137_140_AL
    delegate SWC_PLT_Appl_Communication.Pp_SG_Detections_113_116_AL <-> outer port Pp_SG_Detections_113_116_AL
    delegate SWC_PLT_Appl_Communication.Pp_SG_Detections_093_096_AL <-> outer port Pp_SG_Detections_093_096_AL
    delegate SWC_PLT_Appl_Communication.Pp_SG_Detections_073_076_AL <-> outer port Pp_SG_Detections_073_076_AL
    delegate SWC_PLT_Appl_Communication.Pp_SG_Detections_153_156_AL <-> outer port Pp_SG_Detections_153_156_AL
    delegate SWC_PLT_Appl_Communication.Pp_SG_Detections_181_184_AL <-> outer port Pp_SG_Detections_181_184_AL
    delegate SWC_PLT_Appl_Communication.Pp_SG_Detections_145_148_AL <-> outer port Pp_SG_Detections_145_148_AL
    delegate SWC_PLT_Appl_Communication.Pp_SG_Detections_161_164_AL <-> outer port Pp_SG_Detections_161_164_AL
    delegate SWC_PLT_Appl_Communication.Pp_SG_Detections_101_104_AL <-> outer port Pp_SG_Detections_101_104_AL
    delegate SWC_PLT_Appl_Communication.Pp_SG_Detections_061_064_AL <-> outer port Pp_SG_Detections_061_064_AL
    delegate SWC_PLT_Appl_Communication.Pp_SG_Detections_025_028_AL <-> outer port Pp_SG_Detections_025_028_AL
    delegate SWC_PLT_Appl_Communication.Pp_SG_Detections_053_056_AL <-> outer port Pp_SG_Detections_053_056_AL
    delegate SWC_PLT_Appl_Communication.Pp_SG_Detections_201_204_AL <-> outer port Pp_SG_Detections_201_204_AL
    delegate SWC_PLT_Appl_Communication.Pp_SG_Detections_121_124_AL <-> outer port Pp_SG_Detections_121_124_AL
    delegate SWC_PLT_Appl_Communication.Pp_SG_Detections_037_040_AL <-> outer port Pp_SG_Detections_037_040_AL
    delegate SWC_PLT_Appl_Communication.Pp_SG_Detections_033_036_AL <-> outer port Pp_SG_Detections_033_036_AL
    delegate SWC_PLT_Appl_Communication.Pp_SG_Detections_045_048_AL <-> outer port Pp_SG_Detections_045_048_AL
    delegate SWC_PLT_Appl_Communication.Pp_SG_Detections_185_188_AL <-> outer port Pp_SG_Detections_185_188_AL
    delegate SWC_PLT_Appl_Communication.Pp_SG_Detections_069_072_AL <-> outer port Pp_SG_Detections_069_072_AL
    delegate SWC_PLT_Appl_Communication.Pp_SG_Detections_105_108_AL <-> outer port Pp_SG_Detections_105_108_AL
    delegate SWC_PLT_Appl_Communication.Pp_SG_Detections_117_120_AL <-> outer port Pp_SG_Detections_117_120_AL
    delegate SWC_PLT_Appl_Communication.Pp_SG_Detections_057_060_AL <-> outer port Pp_SG_Detections_057_060_AL
    delegate SWC_PLT_Appl_Communication.Pp_SG_Detections_173_176_AL <-> outer port Pp_SG_Detections_173_176_AL
    delegate SWC_PLT_Appl_Communication.Pp_SG_Detections_021_024_AL <-> outer port Pp_SG_Detections_021_024_AL
    delegate SWC_PLT_Appl_Communication.Pp_SG_Detections_077_080_AL <-> outer port Pp_SG_Detections_077_080_AL
    delegate SWC_PLT_Appl_Communication.Pp_SG_Detections_097_100_AL <-> outer port Pp_SG_Detections_097_100_AL
    delegate SWC_PLT_Appl_Communication.Pp_SG_Detections_109_112_AL <-> outer port Pp_SG_Detections_109_112_AL
    delegate SWC_PLT_Appl_Communication.Pp_SG_Detections_221_224_AL <-> outer port Pp_SG_Detections_221_224_AL
    delegate SWC_PLT_Appl_Communication.Pp_SG_Detections_141_144_AL <-> outer port Pp_SG_Detections_141_144_AL
    delegate SWC_PLT_Appl_Communication.Pp_SG_Detections_193_196_AL <-> outer port Pp_SG_Detections_193_196_AL
    delegate SWC_PLT_Appl_Communication.Pp_SG_Detections_165_168_AL <-> outer port Pp_SG_Detections_165_168_AL
    delegate SWC_PLT_Appl_Communication.Pp_SG_Detections_213_216_AL <-> outer port Pp_SG_Detections_213_216_AL
    delegate SWC_PLT_Appl_Communication.Pp_SG_Detections_049_052_AL <-> outer port Pp_SG_Detections_049_052_AL
    delegate SWC_PLT_Appl_Communication.Pp_SG_Detections_157_160_AL <-> outer port Pp_SG_Detections_157_160_AL
    delegate SWC_PLT_Appl_Communication.Pp_SG_Detections_013_016_AL <-> outer port Pp_SG_Detections_013_016_AL
    delegate SWC_PLT_Appl_Communication.Rp_SG_Fusion_Detections_105_108_AL <-> outer port Rp_SG_Fusion_Detections_105_108_AL
    delegate SWC_PLT_Appl_Communication.Rp_SG_Fusion_Detections_121_124_AL <-> outer port Rp_SG_Fusion_Detections_121_124_AL
    delegate SWC_PLT_Appl_Communication.Rp_SG_Fusion_Detections_013_016_AL <-> outer port Rp_SG_Fusion_Detections_013_016_AL
    delegate SWC_PLT_Appl_Communication.Rp_SG_Fusion_Detections_009_012_AL <-> outer port Rp_SG_Fusion_Detections_009_012_AL
    delegate SWC_PLT_Appl_Communication.Rp_SG_Fusion_Detections_017_020_AL <-> outer port Rp_SG_Fusion_Detections_017_020_AL
    delegate SWC_PLT_Appl_Communication.Rp_SG_Fusion_Detections_065_068_AL <-> outer port Rp_SG_Fusion_Detections_065_068_AL
    delegate SWC_PLT_Appl_Communication.Rp_SG_Fusion_Detections_057_060_AL <-> outer port Rp_SG_Fusion_Detections_057_060_AL
    delegate SWC_PLT_Appl_Communication.Rp_SG_Fusion_Detections_073_076_AL <-> outer port Rp_SG_Fusion_Detections_073_076_AL
    delegate SWC_PLT_Appl_Communication.Rp_SG_Fusion_Detections_101_104_AL <-> outer port Rp_SG_Fusion_Detections_101_104_AL
    delegate SWC_PLT_Appl_Communication.Rp_SG_Fusion_Detections_033_036_AL <-> outer port Rp_SG_Fusion_Detections_033_036_AL
    delegate SWC_PLT_Appl_Communication.Rp_SG_Fusion_Detections_005_008_AL <-> outer port Rp_SG_Fusion_Detections_005_008_AL
    delegate SWC_PLT_Appl_Communication.Rp_SG_Fusion_Detections_113_116_AL <-> outer port Rp_SG_Fusion_Detections_113_116_AL
    delegate SWC_PLT_Appl_Communication.Rp_SG_Fusion_Detections_049_052_AL <-> outer port Rp_SG_Fusion_Detections_049_052_AL
    delegate SWC_PLT_Appl_Communication.Rp_SG_Fusion_Detections_109_112_AL <-> outer port Rp_SG_Fusion_Detections_109_112_AL
    delegate SWC_PLT_Appl_Communication.Rp_SG_Fusion_Detections_093_096_AL <-> outer port Rp_SG_Fusion_Detections_093_096_AL
    delegate SWC_PLT_Appl_Communication.Rp_SG_Fusion_Detections_125_128_AL <-> outer port Rp_SG_Fusion_Detections_125_128_AL
    delegate SWC_PLT_Appl_Communication.Rp_SG_Fusion_Detections_085_088_AL <-> outer port Rp_SG_Fusion_Detections_085_088_AL
    delegate SWC_PLT_Appl_Communication.Rp_SG_Fusion_Detections_041_044_AL <-> outer port Rp_SG_Fusion_Detections_041_044_AL
    delegation sw connector Rp_SG_Fusion_RadarStatus_AL_SWC_PLT_Appl_Communication_Rp_SG_Fusion_RadarStatus_AL: inner-port=SWC_PLT_Appl_Communication
    delegate SWC_PLT_Appl_Communication.Rp_SG_Fusion_Detections_061_064_AL <-> outer port Rp_SG_Fusion_Detections_061_064_AL
    delegate SWC_PLT_Appl_Communication.Rp_SG_Fusion_Detections_089_092_AL <-> outer port Rp_SG_Fusion_Detections_089_092_AL
    delegate SWC_PLT_Appl_Communication.Rp_SG_Fusion_Detections_021_024_AL <-> outer port Rp_SG_Fusion_Detections_021_024_AL
    delegate SWC_PLT_Appl_Communication.Rp_SG_Fusion_Detections_037_040_AL <-> outer port Rp_SG_Fusion_Detections_037_040_AL
    delegate SWC_PLT_Appl_Communication.Rp_SG_Fusion_Detections_001_004_AL <-> outer port Rp_SG_Fusion_Detections_001_004_AL
    delegate SWC_PLT_Appl_Communication.Rp_SG_Fusion_Detections_029_032_AL <-> outer port Rp_SG_Fusion_Detections_029_032_AL
    delegate SWC_PLT_Appl_Communication.Rp_SG_Fusion_Detections_025_028_AL <-> outer port Rp_SG_Fusion_Detections_025_028_AL
    delegation sw connector Rp_SG_Fusion_RadarHeader_AL_SWC_PLT_Appl_Communication_Rp_SG_Fusion_RadarHeader_AL: inner-port=SWC_PLT_Appl_Communication
    delegate SWC_PLT_Appl_Communication.Rp_SG_Fusion_Detections_117_120_AL <-> outer port Rp_SG_Fusion_Detections_117_120_AL
    delegate SWC_PLT_Appl_Communication.Rp_SG_Fusion_Detections_081_084_AL <-> outer port Rp_SG_Fusion_Detections_081_084_AL
    delegate SWC_PLT_Appl_Communication.Rp_SG_Fusion_Detections_053_056_AL <-> outer port Rp_SG_Fusion_Detections_053_056_AL
    delegate SWC_PLT_Appl_Communication.Rp_SG_Fusion_Detections_097_100_AL <-> outer port Rp_SG_Fusion_Detections_097_100_AL
    delegate SWC_PLT_Appl_Communication.Rp_SG_Fusion_Detections_045_048_AL <-> outer port Rp_SG_Fusion_Detections_045_048_AL
    delegate SWC_PLT_Appl_Communication.Rp_SG_Fusion_Detections_077_080_AL <-> outer port Rp_SG_Fusion_Detections_077_080_AL
    delegate SWC_PLT_Appl_Communication.Rp_SG_Fusion_Detections_069_072_AL <-> outer port Rp_SG_Fusion_Detections_069_072_AL
    delegation sw connector SWC_PLT_Appl_Communication_Pp_SG_RadarHeader_AL_Pp_SG_RadarHeader_AL: inner-port=SWC_PLT_Appl_Communication
    delegation sw connector SWC_PLT_Appl_Communication_Pp_SG_RadarStatus1_AL_Pp_SG_RadarStatus1_AL: inner-port=SWC_PLT_Appl_Communication
    delegate SWC_PLT_Appl_Communication.Pp_SG_RadarCapability_AL <-> outer port Pp_SG_RadarCapability_AL
    delegate SWC_PLT_Appl_Communication.Pp_SG_RadarStatus2_AL <-> outer port Pp_SG_RadarStatus2_AL
    delegate SWC_PLT_Appl_Communication.Rp_SG_VehicleStatus_AL <-> outer port Rp_SG_VehicleStatus_AL
    delegate SWC_PLT_Appl_Communication.Rp_SG_XcpCTOReq_AL <-> outer port Rp_SG_XcpCTOReq_AL
    delegate SWC_PLT_Appl_Communication.Pp_SG_XcpDAQResp_AL <-> outer port Pp_SG_XcpDAQResp_AL
    delegate SWC_PLT_Appl_Communication.Pp_SG_XcpCTOResp_AL <-> outer port Pp_SG_XcpCTOResp_AL
    connect SWC_PLT_CDD_XCP.Pp_XCP_RFBIST_Calib_Trigger -> SWC_PLT_CDD_Radar_Control.Rp_XCP_RFBIST_Calib_Trigger
    delegate ModeManagerCompositionType.Pp_ECC_Correctable_Fault <-> outer port Pp_ECC_Correctable_Fault
    connect SWC_PLT_Appl_Communication.PostRadarProcessing_CAN_Tx -> SWC_PLT_CDD_Radar_Control.PostRadarProcessing_CAN_Tx
    connect SWC_PLT_Appl_RTM.CS_Rtm_task_measurement -> SWC_PLT_CDD_Logging.CS_Rtm_task_measurement
    connect ModeManagerCompositionType.Pp_ECC_Correctable_Fault -> SWC_PLT_Appl_NvMHandler.Rp_ECC_Correctable_Fault
    connect SWC_PLT_CDD_TimeSync.Pp_TimeSync_Status_No_Tsyn_Error -> SWC_PLT_Appl_Communication.Rp_TimeSync_Status_No_Tsyn_Error
    connect SWC_PLT_CDD_TimeSync.Pp_Time_Stamp_Delta -> SWC_PLT_Appl_Communication.Rp_Time_Stamp_Delta
    connect SWC_PLT_Appl_NvMHandler.Pp_RFE_NvM_Data -> SWC_PLT_CDD_Radar_Control.Rp_RFE_NvM_Data
    connect SWC_PLT_CDD_Radar_Control.Pp_RFE_NvM_Data -> SWC_PLT_Appl_NvMHandler.Rp_RFE_NvM_Data
    delegate SWC_PLT_CDD_ExternalWdg.Pp_Pmic_Mcu_Com_Fault <-> outer port Pp_Pmic_Mcu_Com_Fault
    connect SWC_PLT_CDD_ExternalWdg.Pp_Pmic_Mcu_Com_Fault -> ModeManagerCompositionType.Rp_Pmic_Mcu_Com_Fault
    delegate SWC_PLT_Appl_Communication.Pp_SG_RDR_BSD1_Tx_ALPCAN <-> outer port Pp_SG_RDR_BSD1_Tx_ALPCAN
    delegate SWC_PLT_Appl_Communication.Pp_SG_RadarHeader_ALPCAN <-> outer port Pp_SG_RadarHeader_ALPCAN
    delegate SWC_PLT_Appl_Communication.Pp_SG_RadarStatus1_ALPCAN <-> outer port Pp_SG_RadarStatus1_ALPCAN
    delegate SWC_PLT_Appl_Communication.Pp_SG_GW_prop_ADAS_BSIS_info_ALPCAN <-> outer port Pp_SG_GW_prop_ADAS_BSIS_info_ALPCAN
    delegate SWC_PLT_Appl_Communication.Pp_SG_prop_ADAS_MOIS_info_ALVCAN <-> outer port Pp_SG_prop_ADAS_MOIS_info_ALVCAN
    delegate SWC_PLT_Appl_Communication.Pp_SG_MOIS_ALVCAN <-> outer port Pp_SG_MOIS_ALVCAN
    delegate SWC_PLT_Appl_Communication.Rp_SG_Fusion_AlignmentStatus2_ALPCAN <-> outer port Rp_SG_Fusion_AlignmentStatus2_ALPCAN
    delegate SWC_PLT_Appl_Communication.Rp_SG_GW_VI_ALPCAN <-> outer port Rp_SG_GW_VI_ALPCAN
    delegate SWC_PLT_Appl_Communication.Rp_SG_ETC2_03_ALVCAN <-> outer port Rp_SG_ETC2_03_ALVCAN
    delegate SWC_PLT_Appl_Communication.Rp_SG_GW_ETC2_03_ALPCAN <-> outer port Rp_SG_GW_ETC2_03_ALPCAN
    delegate SWC_PLT_Appl_Communication.Rp_SG_GW_CLS_Tx_16_ALPCAN <-> outer port Rp_SG_GW_CLS_Tx_16_ALPCAN
    delegate SWC_PLT_Appl_Communication.Rp_SG_GW_OEL_ALPCAN <-> outer port Rp_SG_GW_OEL_ALPCAN
    delegate SWC_PLT_Appl_Communication.Rp_SG_Fusion_RadarHeader_ALPCAN <-> outer port Rp_SG_Fusion_RadarHeader_ALPCAN
    delegate SWC_PLT_Appl_Communication.Rp_SG_GW_VD_ALPCAN <-> outer port Rp_SG_GW_VD_ALPCAN
    delegate SWC_PLT_Appl_Communication.Rp_SG_OEL_ALVCAN <-> outer port Rp_SG_OEL_ALVCAN
    delegate SWC_PLT_Appl_Communication.Rp_SG_VI_ALVCAN <-> outer port Rp_SG_VI_ALVCAN
    delegate SWC_PLT_Appl_Communication.Rp_SG_Fusion_RadarStatus2_ALPCAN <-> outer port Rp_SG_Fusion_RadarStatus2_ALPCAN
    delegate SWC_PLT_Appl_Communication.Rp_SG_VD_ALVCAN <-> outer port Rp_SG_VD_ALVCAN
    delegate SWC_PLT_Appl_Communication.Rp_SG_GW_CCVS1_ALPCAN <-> outer port Rp_SG_GW_CCVS1_ALPCAN
    delegate SWC_PLT_Appl_Communication.Rp_SG_Fusion_AlignmentStatus1_ALPCAN <-> outer port Rp_SG_Fusion_AlignmentStatus1_ALPCAN
    delegate SWC_PLT_Appl_Communication.Rp_SG_CLS_Tx_4_ALVCAN <-> outer port Rp_SG_CLS_Tx_4_ALVCAN
    delegate SWC_PLT_Appl_Communication.Rp_SG_Fusion_RadarCapability_ALPCAN <-> outer port Rp_SG_Fusion_RadarCapability_ALPCAN
    delegate SWC_PLT_Appl_Communication.Rp_SG_GW_ETC2_ALPCAN <-> outer port Rp_SG_GW_ETC2_ALPCAN
    delegate SWC_PLT_Appl_Communication.Rp_SG_GW_VDC2_ALPCAN <-> outer port Rp_SG_GW_VDC2_ALPCAN
    delegate SWC_PLT_Appl_Communication.Rp_SG_SAS_ALVCAN <-> outer port Rp_SG_SAS_ALVCAN
    delegate SWC_PLT_Appl_Communication.Rp_SG_TD_ALVCAN <-> outer port Rp_SG_TD_ALVCAN
    delegate SWC_PLT_Appl_Communication.Rp_SG_ETC2_00_ALVCAN <-> outer port Rp_SG_ETC2_00_ALVCAN
    delegate SWC_PLT_Appl_Communication.Rp_SG_CLS_Tx_16_ALVCAN <-> outer port Rp_SG_CLS_Tx_16_ALVCAN
    delegate SWC_PLT_Appl_Communication.Rp_SG_GW_TD_ALPCAN <-> outer port Rp_SG_GW_TD_ALPCAN
    delegate SWC_PLT_Appl_Communication.Rp_SG_CCVS1_ALVCAN <-> outer port Rp_SG_CCVS1_ALVCAN
    delegate SWC_PLT_Appl_Communication.Rp_SG_VDC2_ALVCAN <-> outer port Rp_SG_VDC2_ALVCAN
    delegate SWC_PLT_Appl_Communication.Rp_SG_Fusion_RadarStatus_ALPCAN <-> outer port Rp_SG_Fusion_RadarStatus_ALPCAN
    delegate SWC_PLT_Appl_Communication.Rp_SG_GW_SAS_ALPCAN <-> outer port Rp_SG_GW_SAS_ALPCAN
    delegate SWC_PLT_Appl_Communication.Rp_SG_GW_ADAS_FN_Enable_disable_sts_ALPCAN <-> outer port Rp_SG_GW_ADAS_FN_Enable_disable_sts_ALPCAN
    delegate SWC_PLT_Appl_Communication.Rp_SG_GW_CLS_Tx_4_ALPCAN <-> outer port Rp_SG_GW_CLS_Tx_4_ALPCAN
    delegate SWC_PLT_Appl_Communication.Rp_SG_ADAS_FN_Enable_disable_sts_ALVCAN <-> outer port Rp_SG_ADAS_FN_Enable_disable_sts_ALVCAN
